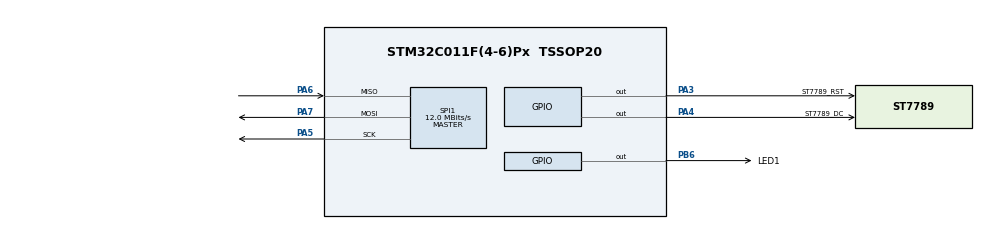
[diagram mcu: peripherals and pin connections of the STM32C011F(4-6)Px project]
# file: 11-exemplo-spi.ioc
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Mcu.Family=STM32C0
Mcu.Name=STM32C011F(4-6)Px
Mcu.Package=TSSOP20
PA13.Mode=Serial_Wire
PA13.Signal=DEBUG_SWDIO
PA14-BOOT0.Mode=Serial_Wire
PA14-BOOT0.Signal=DEBUG_SWCLK
PA3.GPIO_Label=ST7789_RST
PA3.Signal=GPIO_Output
PA4.GPIO_Label=ST7789_DC
PA4.Signal=GPIO_Output
PA5.Mode=Full_Duplex_Master
PA5.Signal=SPI1_SCK
PA6.Mode=Full_Duplex_Master
PA6.Signal=SPI1_MISO
PA7.Mode=Full_Duplex_Master
PA7.Signal=SPI1_MOSI
PB6.GPIO_Label=LED1
PB6.Signal=GPIO_Output
ProjectManager.HeapSize=0x200
ProjectManager.StackSize=0x400
ProjectManager.TargetToolchain=STM32CubeIDE
RCC.ADCFreq_Value=48000000
RCC.AHBFreq_Value=48000000
RCC.CortexFreq_Value=48000000
RCC.EXTERNAL_CLOCK_VALUE=12288000
RCC.HCLKFreq_Value=48000000
RCC.HSE_VALUE=8000000
RCC.HSISYSCLKDivider=RCC_HSI_DIV1
RCC.HSI_VALUE=48000000
RCC.LSE_VALUE=32768
RCC.SYSCLKFreq_VALUE=48000000
SPI1.BaudRatePrescaler=SPI_BAUDRATEPRESCALER_4
SPI1.CLKPolarity=SPI_POLARITY_HIGH
SPI1.CalculateBaudRate=12.0 MBits/s
SPI1.Direction=SPI_DIRECTION_2LINES
SPI1.Mode=SPI_MODE_MASTER
SPI1.VirtualType=VM_MASTER
board=custom

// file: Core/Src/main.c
/* USER CODE BEGIN Header */
/**
  ******************************************************************************
  * @file           : main.c
  * @brief          : Main program body
  ******************************************************************************
  * @attention
  *
  * Copyright (c) 2023 STMicroelectronics.
  * All rights reserved.
  *
  * This software is licensed under terms that can be found in the LICENSE file
  * in the root directory of this software component.
  * If no LICENSE file comes with this software, it is provided AS-IS.
  *
  ******************************************************************************
  */
/* USER CODE END Header */
#include "main.h"
#include "spi.h"
#include "gpio.h"

/* USER CODE BEGIN Includes */

#include "st7789.h"	// Biblioteca utilizada para controlar o display LCD
					// Fonte: https://github.com/Floyd-Fish/ST7789-STM32

/* USER CODE END Includes */

/* USER CODE BEGIN PV */

// Logo Franzininho
const uint16_t logo_franzininho[] =
{
		0xffff, 0xffff, 0xffff, 0xffff, 0xffff, 0xffff, 0xffff, 0xffff, 0xffff, 0xffff, 0xffff, 0xffff, 0xffff, 0xffff, 0xffff, 0xffff, 0xffff, 0xffff, 0xffff, 0xffff, 0xffff, 0xffff, 0xffff, 0xffff, 0xffff, 0xffff, 0xffff, 0xffff, 0xffff, 0xffff, 0xffff, 0xffff, 0xffff, 0xffff, 0xffff, 0xffff, 0xffff, 0xffff, 0xffff, 0xffff, 0xffff, 0xffff, 0xffff, 0xffff, 0xffff, 0xffff, 0xffff, 0xffff, 0xffff, 0xffff, 0xffff, 0xffff, 0xffff, 0xffff, 0xffff, 0xffff, 0xffff, 0xffff, 0xffff, 0xffff, 0xffff, 0xffff, 0xffff, 0xffff, 0xffff, 0xffff, 0xffff, 0xffff, 0xffff, 0xffff, 0xffff, 0xffff, 0xffff, 0xffff, 0xffff, 0xffff, 0xffff, 0xffff, 0xffff, 0xffff, 0xffff, 0x18c6, 0x9ad6, 0xffff, 0xffff, 0xffff, 0xffff, 0xffff, 0xffff, 0xffff, 0xffff, 0xffff, 0xffff, 0xffff, 0xffff, 0xffff,
		0xffff, 0xffff, 0xffff, 0xffff, 0xffff, 0xffff, 0xffff, 0xffff, 0xffff, 0xffff, 0xffff, 0xffff, 0xffff, 0xffff, 0xffff, 0xffff, 0xffff, 0xffff, 0xffff, 0xffff, 0xffff, 0xffff, 0xffff, 0xffff, 0xffff, 0xffff, 0xffff, 0xffff, 0xffff, 0xffff, 0xffff, 0xffff, 0xffff, 0xffff, 0xffff, 0xffff, 0xffff, 0xffff, 0xffff, 0xffff, 0xffff, 0xffff, 0xffff, 0xffff, 0xffff, 0xffff, 0xffff, 0xffff, 0xffff, 0xffff, 0xffff, 0xffff, 0xffff, 0xffff, 0xffff, 0xffff, 0xffff, 0xffff, 0xffff, 0xffff, 0xffff, 0xffff, 0xffff, 0xffff, 0xffff, 0xffff, 0xffff, 0xffff, 0xffff, 0xffff, 0xffff, 0xffff, 0xffff, 0xffff, 0xffff, 0xffff, 0xffff, 0xffff, 0xffff, 0xffff, 0xf7bd, 0x0000, 0xe739, 0xdbde, 0xffff, 0xffff, 0xffff, 0xffff, 0xffff, 0xffff, 0xffff, 0xffff, 0xffff, 0xffff, 0xffff, 0xffff,
		0xffff, 0xffff, 0xffff, 0xffff, 0xffff, 0xffff, 0xffff, 0xffff, 0xffff, 0xffff, 0xffff, 0xffff, 0xffff, 0xffff, 0xffff, 0xffff, 0xffff, 0xffff, 0xffff, 0xffff, 0xffff, 0xffff, 0xffff, 0xffff, 0xffff, 0xffff, 0xffff, 0xffff, 0xffff, 0xffff, 0xffff, 0xffff, 0xffff, 0xffff, 0xffff, 0xffff, 0xffff, 0xffff, 0xffff, 0xffff, 0xffff, 0xffff, 0xffff, 0xffff, 0xffff, 0xffff, 0xffff, 0xffff, 0xffff, 0xffff, 0xffff, 0xffff, 0xffff, 0xffff, 0xffff, 0xffff, 0xffff, 0xffff, 0xffff, 0xffff, 0xffff, 0xffff, 0xffff, 0xffff, 0xffff, 0xffff, 0xffff, 0xffff, 0xffff, 0xffff, 0xffff, 0xffff, 0xffff, 0xffff, 0xffff, 0xffff, 0xffff, 0xffff, 0xffff, 0xd7bd, 0x0000, 0x494a, 0x4529, 0xa631, 0xdbde, 0xffff, 0xffff, 0xffff, 0xffff, 0xffff, 0xffff, 0xffff, 0xffff, 0xffff, 0xffff, 0xffff,
		0xffff, 0xffff, 0xffff, 0xffff, 0xffff, 0xffff, 0xffff, 0xffff, 0xffff, 0xffff, 0xffff, 0xffff, 0xffff, 0xffff, 0xffff, 0xffff, 0xffff, 0xffff, 0xffff, 0xffff, 0xffff, 0xffff, 0xffff, 0xffff, 0xffff, 0xffff, 0xffff, 0xffff, 0xffff, 0xffff, 0xffff, 0xffff, 0xffff, 0xffff, 0xffff, 0xffff, 0xffff, 0xffff, 0xffff, 0xffff, 0xffff, 0xffff, 0xffff, 0xffff, 0xffff, 0xffff, 0xffff, 0xffff, 0xffff, 0xffff, 0xffff, 0xffff, 0xffff, 0xffff, 0xffff, 0xffff, 0xffff, 0xffff, 0xffff, 0xffff, 0xffff, 0xffff, 0xffff, 0xffff, 0xffff, 0xffff, 0xffff, 0xffff, 0xffff, 0xffff, 0xffff, 0xffff, 0xffff, 0xffff, 0xffff, 0xffff, 0xffff, 0xffff, 0xd7bd, 0x0000, 0x2c63, 0x3ce7, 0x9ad6, 0x0000, 0x6529, 0xdbde, 0xffff, 0xffff, 0xffff, 0xffff, 0xffff, 0xffff, 0xffff, 0xffff, 0xffff, 0xffff,
		0xffff, 0xffff, 0xffff, 0xffff, 0xffff, 0xffff, 0xffff, 0xffff, 0xffff, 0xffff, 0xffff, 0xffff, 0xffff, 0xffff, 0xffff, 0xffff, 0xffff, 0xffff, 0xffff, 0xffff, 0xffff, 0xffff, 0xffff, 0xffff, 0xffff, 0xffff, 0xffff, 0xffff, 0xffff, 0xffff, 0xffff, 0xffff, 0xffff, 0xffff, 0xffff, 0xffff, 0xffff, 0xffff, 0xffff, 0xffff, 0xffff, 0xffff, 0xffff, 0xffff, 0xffff, 0xffff, 0xffff, 0xffff, 0xffff, 0xffff, 0xffff, 0xffff, 0xffff, 0xffff, 0xffff, 0xffff, 0xffff, 0xffff, 0xffff, 0xffff, 0xffff, 0xffff, 0xffff, 0xffff, 0xffff, 0xffff, 0xffff, 0xffff, 0xffff, 0xffff, 0xffff, 0xffff, 0xffff, 0xffff, 0xffff, 0xffff, 0xffff, 0xd7bd, 0x0000, 0x0000, 0x34a5, 0xffff, 0xffff, 0x79ce, 0x0000, 0x4529, 0xdbde, 0xffff, 0xffff, 0xffff, 0xffff, 0xffff, 0xffff, 0xffff, 0xffff, 0xffff,
		0xffff, 0xffff, 0xffff, 0xffff, 0xffff, 0xffff, 0xffff, 0xffff, 0xffff, 0xffff, 0xffff, 0xffff, 0xffff, 0xffff, 0xffff, 0xffff, 0xffff, 0xffff, 0xffff, 0xffff, 0xffff, 0xffff, 0xffff, 0xffff, 0xffff, 0xffff, 0xffff, 0xffff, 0xffff, 0xffff, 0xffff, 0xffff, 0xffff, 0xffff, 0xffff, 0xffff, 0xffff, 0xffff, 0xffff, 0xffff, 0xffff, 0xffff, 0xffff, 0xffff, 0xffff, 0xffff, 0xffff, 0xffff, 0xffff, 0xffff, 0xffff, 0xffff, 0xffff, 0xffff, 0xffff, 0xffff, 0xffff, 0xffff, 0xffff, 0xffff, 0xffff, 0xffff, 0xffff, 0xffff, 0xffff, 0xffff, 0xffff, 0xffff, 0xffff, 0xffff, 0xffff, 0xffff, 0xffff, 0xffff, 0xffff, 0xffff, 0xd7bd, 0x0000, 0x8e73, 0xd39c, 0x0000, 0xb6b5, 0xffff, 0xffff, 0x79ce, 0x0000, 0x8631, 0xfbde, 0xffff, 0xffff, 0xffff, 0xffff, 0xffff, 0xffff, 0xffff, 0xffff,
		0xffff, 0xffff, 0xffff, 0xffff, 0xffff, 0xffff, 0xffff, 0xffff, 0xffff, 0xffff, 0xffff, 0xffff, 0xffff, 0xffff, 0xffff, 0xffff, 0xffff, 0xffff, 0xffff, 0xffff, 0xffff, 0xffff, 0xffff, 0xffff, 0xffff, 0xffff, 0xffff, 0xffff, 0xffff, 0xffff, 0xffff, 0xffff, 0xffff, 0xffff, 0xffff, 0xffff, 0xffff, 0xffff, 0xffff, 0xffff, 0xffff, 0xffff, 0xffff, 0xffff, 0xffff, 0xffff, 0xffff, 0xffff, 0xffff, 0xffff, 0xffff, 0xffff, 0xffff, 0xffff, 0xffff, 0xffff, 0xffff, 0xffff, 0xffff, 0xffff, 0xffff, 0xffff, 0xffff, 0xffff, 0xffff, 0xffff, 0xffff, 0xffff, 0xffff, 0xffff, 0xffff, 0xffff, 0xffff, 0xffff, 0xffff, 0xd7bd, 0x0000, 0x2c63, 0x3ce7, 0xffff, 0x34a5, 0x0000, 0xb6b5, 0xffff, 0xffff, 0x79ce, 0x0000, 0x2842, 0x5def, 0xffff, 0xffff, 0xffff, 0xffff, 0xffff, 0xffff, 0xffff,
		0xffff, 0xffff, 0xffff, 0xffff, 0xffff, 0xffff, 0xffff, 0xffff, 0xffff, 0xffff, 0xffff, 0xffff, 0xffff, 0xffff, 0xffff, 0xffff, 0xffff, 0xffff, 0xffff, 0xffff, 0xffff, 0xffff, 0xffff, 0xffff, 0xffff, 0xffff, 0xffff, 0xffff, 0xffff, 0xffff, 0xffff, 0xffff, 0xffff, 0xffff, 0xffff, 0xffff, 0xffff, 0xffff, 0xffff, 0xffff, 0xffff, 0xffff, 0xffff, 0xffff, 0xffff, 0xffff, 0xffff, 0xffff, 0xffff, 0xffff, 0xffff, 0xffff, 0xffff, 0xffff, 0xffff, 0xffff, 0xffff, 0xffff, 0xffff, 0xffff, 0xffff, 0xffff, 0xffff, 0xffff, 0xffff, 0xffff, 0xffff, 0xffff, 0xffff, 0xffff, 0xffff, 0xffff, 0xffff, 0xffff, 0xd7bd, 0x0000, 0x0c63, 0x5def, 0xffff, 0x18c6, 0x59ce, 0x55ad, 0x0000, 0xb6b5, 0xffff, 0xffff, 0x9ad6, 0xe318, 0x2c63, 0x5def, 0xffff, 0xffff, 0xffff, 0xffff, 0xffff, 0xffff,
		0xffff, 0xffff, 0xffff, 0xffff, 0xffff, 0xffff, 0xffff, 0xffff, 0xffff, 0xffff, 0xffff, 0xffff, 0xffff, 0xffff, 0xffff, 0xffff, 0xffff, 0xffff, 0xffff, 0xffff, 0xffff, 0xffff, 0xffff, 0xffff, 0xffff, 0xffff, 0xffff, 0xffff, 0xffff, 0xffff, 0xffff, 0xffff, 0xffff, 0xffff, 0xffff, 0xffff, 0xffff, 0xffff, 0xffff, 0xffff, 0xffff, 0xffff, 0xffff, 0xffff, 0xffff, 0xffff, 0xffff, 0xffff, 0xffff, 0xffff, 0xffff, 0xffff, 0xffff, 0xffff, 0xffff, 0xffff, 0xffff, 0xffff, 0xffff, 0xffff, 0xffff, 0xffff, 0xffff, 0xffff, 0xffff, 0xffff, 0xffff, 0xffff, 0xffff, 0xffff, 0xffff, 0xffff, 0xffff, 0xb6b5, 0x0000, 0x0c63, 0x5def, 0xffff, 0x75ad, 0x0000, 0x18c6, 0xffff, 0x34a5, 0x0000, 0xb6b5, 0xffff, 0xdfff, 0x2c63, 0x0000, 0xbad6, 0xffff, 0xffff, 0xffff, 0xffff, 0xffff, 0xffff,
		0xffff, 0xffff, 0xffff, 0xffff, 0xffff, 0xffff, 0xffff, 0xffff, 0xffff, 0xffff, 0xffff, 0xffff, 0xffff, 0xffff, 0xffff, 0xffff, 0xffff, 0xffff, 0xffff, 0xffff, 0xffff, 0xffff, 0xffff, 0xffff, 0xffff, 0xffff, 0xffff, 0xffff, 0xffff, 0xffff, 0xffff, 0xffff, 0xffff, 0xffff, 0xffff, 0xffff, 0xffff, 0xffff, 0xffff, 0xffff, 0xffff, 0xffff, 0xffff, 0xffff, 0xffff, 0xffff, 0xffff, 0xffff, 0xffff, 0xffff, 0xffff, 0xffff, 0xffff, 0xffff, 0xffff, 0xffff, 0xffff, 0xffff, 0xffff, 0xffff, 0xffff, 0xffff, 0xffff, 0xffff, 0xffff, 0xffff, 0xffff, 0xffff, 0xffff, 0xffff, 0xffff, 0xffff, 0xb6b5, 0x0000, 0x0c63, 0x5def, 0xffff, 0xb6b5, 0x0000, 0x96b5, 0xffff, 0xffff, 0xffff, 0x34a5, 0x0000, 0x75ad, 0x718c, 0x0000, 0xb6b5, 0xffff, 0xffff, 0xffff, 0xffff, 0xffff, 0xffff, 0xffff,
		0xffff, 0xffff, 0xffff, 0xffff, 0xffff, 0xffff, 0xffff, 0xffff, 0xffff, 0xffff, 0xffff, 0xffff, 0xffff, 0xffff, 0xffff, 0xffff, 0xffff, 0xffff, 0xffff, 0xffff, 0xffff, 0xffff, 0xffff, 0xffff, 0xffff, 0xffff, 0xffff, 0xffff, 0xffff, 0xffff, 0xffff, 0xffff, 0xffff, 0xffff, 0xffff, 0xffff, 0xffff, 0xffff, 0xffff, 0xffff, 0xffff, 0xffff, 0xffff, 0xffff, 0xdbde, 0xf7bd, 0xdfff, 0xffff, 0xffff, 0xffff, 0xffff, 0xffff, 0xffff, 0xffff, 0xffff, 0xffff, 0xffff, 0xffff, 0xffff, 0xffff, 0xffff, 0xffff, 0xffff, 0xffff, 0xffff, 0xffff, 0xffff, 0xffff, 0xffff, 0xffff, 0xffff, 0xb6b5, 0x0000, 0x0c63, 0x5def, 0xffff, 0xdfff, 0xb294, 0xf7bd, 0xffff, 0xffff, 0xffff, 0xffff, 0xffff, 0x14a5, 0x0000, 0x0000, 0x75ad, 0xffff, 0xffff, 0xffff, 0xffff, 0xffff, 0xffff, 0xffff, 0xffff,
		0xffff, 0xffff, 0xffff, 0xffff, 0xffff, 0xffff, 0xffff, 0xffff, 0xffff, 0xffff, 0xffff, 0xffff, 0xffff, 0xffff, 0xffff, 0xffff, 0xffff, 0xffff, 0xffff, 0xffff, 0xffff, 0xffff, 0xffff, 0xffff, 0xffff, 0xffff, 0xffff, 0xffff, 0xffff, 0xffff, 0xffff, 0xffff, 0xffff, 0xffff, 0xffff, 0xffff, 0xffff, 0xffff, 0xffff, 0xffff, 0xffff, 0xffff, 0xffff, 0x38c6, 0x6529, 0x0000, 0x55ad, 0xffff, 0xffff, 0xffff, 0xffff, 0xffff, 0xffff, 0xffff, 0xffff, 0xffff, 0xffff, 0xffff, 0xffff, 0xffff, 0xffff, 0xffff, 0xffff, 0xffff, 0xffff, 0xffff, 0xffff, 0xffff, 0xffff, 0xffff, 0xb6b5, 0x0000, 0x0c63, 0x5def, 0xffff, 0x3ce7, 0xdfff, 0xffff, 0xffff, 0xffff, 0xffff, 0xffff, 0xffff, 0xbef7, 0x9294, 0x0000, 0x14a5, 0xffff, 0xffff, 0xffff, 0xffff, 0xffff, 0xffff, 0xffff, 0xffff, 0xffff,
		0xffff, 0xffff, 0xffff, 0xffff, 0xffff, 0xffff, 0xffff, 0xffff, 0xffff, 0xffff, 0xffff, 0xffff, 0xffff, 0xffff, 0xffff, 0xffff, 0xffff, 0xffff, 0xffff, 0xffff, 0xffff, 0xffff, 0xffff, 0xffff, 0xffff, 0xffff, 0xffff, 0xffff, 0xffff, 0xffff, 0xffff, 0xffff, 0xffff, 0xffff, 0xffff, 0xffff, 0xffff, 0xffff, 0xffff, 0xffff, 0xffff, 0xdfff, 0x75ad, 0x0000, 0x4108, 0xa631, 0x0000, 0xd7bd, 0xffff, 0xffff, 0xffff, 0xffff, 0xffff, 0xffff, 0xffff, 0xffff, 0xffff, 0xffff, 0xffff, 0xffff, 0xffff, 0xffff, 0xffff, 0xffff, 0xffff, 0xffff, 0xffff, 0xffff, 0xffff, 0xd7bd, 0x0000, 0x0c63, 0x5def, 0xffff, 0x18c6, 0x2c63, 0x7def, 0xffff, 0xffff, 0xffff, 0xffff, 0xffff, 0xbef7, 0x718c, 0x0000, 0x14a5, 0xdfff, 0xffff, 0xffff, 0xffff, 0xffff, 0xffff, 0xffff, 0xffff, 0xffff, 0xffff,
		0xffff, 0xffff, 0xffff, 0xffff, 0xffff, 0xffff, 0xffff, 0xffff, 0xffff, 0xffff, 0xffff, 0xffff, 0xffff, 0xffff, 0xffff, 0xffff, 0xffff, 0xffff, 0xffff, 0xffff, 0xffff, 0xffff, 0xffff, 0xffff, 0xffff, 0xffff, 0xffff, 0xffff, 0xffff, 0xffff, 0xffff, 0xffff, 0xffff, 0xffff, 0xffff, 0xffff, 0xffff, 0xffff, 0xffff, 0xffff, 0x7def, 0x1084, 0x0000, 0x8a52, 0xdbde, 0xdbde, 0x8631, 0x0000, 0x79ce, 0xffff, 0xffff, 0xffff, 0xffff, 0xffff, 0xffff, 0xffff, 0xffff, 0xffff, 0xffff, 0xffff, 0xffff, 0xffff, 0xffff, 0xffff, 0xffff, 0xffff, 0xffff, 0xffff, 0xb6b5, 0x0000, 0x0c63, 0x5def, 0xffff, 0xb6b5, 0x0000, 0x9ad6, 0xffff, 0xffff, 0xffff, 0xffff, 0xffff, 0xbef7, 0x518c, 0x0000, 0x14a5, 0xdfff, 0xffff, 0xffff, 0xffff, 0xffff, 0xffff, 0xffff, 0xffff, 0xffff, 0xffff, 0xffff,
		0xffff, 0xffff, 0xffff, 0xffff, 0xffff, 0xffff, 0xffff, 0xffff, 0xffff, 0xffff, 0xffff, 0xffff, 0xffff, 0xffff, 0xffff, 0xffff, 0xffff, 0xffff, 0xffff, 0xffff, 0xffff, 0xffff, 0xffff, 0xffff, 0xffff, 0xffff, 0xffff, 0xffff, 0xffff, 0xffff, 0xffff, 0xffff, 0xffff, 0xffff, 0xffff, 0xffff, 0xffff, 0xffff, 0xffff, 0xbad6, 0xaa52, 0x0000, 0x1084, 0x5def, 0xffff, 0xffff, 0x79ce, 0x0000, 0x4529, 0xdbde, 0xffff, 0xffff, 0xffff, 0xffff, 0xffff, 0xffff, 0xffff, 0xffff, 0xffff, 0xffff, 0xffff, 0xffff, 0xffff, 0xffff, 0xffff, 0xffff, 0xffff, 0xb6b5, 0x0000, 0x0c63, 0x5def, 0xffff, 0x75ad, 0x0000, 0xd7bd, 0xffff, 0xffff, 0xffff, 0xffff, 0xffff, 0xdfff, 0x518c, 0x0000, 0xf39c, 0xdfff, 0xffff, 0xffff, 0xffff, 0xffff, 0xffff, 0xffff, 0xffff, 0xffff, 0xffff, 0xffff, 0xffff,
		0xffff, 0xffff, 0xffff, 0xffff, 0xffff, 0xffff, 0xffff, 0xffff, 0xffff, 0xffff, 0xffff, 0xffff, 0xffff, 0xffff, 0xffff, 0xffff, 0xffff, 0xffff, 0xffff, 0xffff, 0xffff, 0xffff, 0xffff, 0xffff, 0xffff, 0xffff, 0xffff, 0xffff, 0xffff, 0xffff, 0xffff, 0xffff, 0xffff, 0xffff, 0xffff, 0xffff, 0xffff, 0xffff, 0xf7bd, 0x0000, 0x0000, 0x55ad, 0xdfff, 0xffff, 0xffff, 0xffff, 0xffff, 0xf7bd, 0x0000, 0x8a52, 0x5def, 0xffff, 0xffff, 0xffff, 0xffff, 0xffff, 0xffff, 0xffff, 0xffff, 0xffff, 0xffff, 0xffff, 0xffff, 0xffff, 0xffff, 0xffff, 0xd7bd, 0x0000, 0x2c63, 0x5def, 0xffff, 0x55ad, 0x0000, 0x96b5, 0xffff, 0xffff, 0xffff, 0xffff, 0xffff, 0xdfff, 0x3084, 0x0000, 0xf39c, 0xdfff, 0xffff, 0xffff, 0xffff, 0xffff, 0xffff, 0xffff, 0xffff, 0xffff, 0xffff, 0xffff, 0xffff, 0xffff,
		0xffff, 0xffff, 0xffff, 0xffff, 0xffff, 0xffff, 0xffff, 0xffff, 0xffff, 0xffff, 0xffff, 0xffff, 0xffff, 0xffff, 0xffff, 0xffff, 0xffff, 0xffff, 0xffff, 0xffff, 0xffff, 0xffff, 0xffff, 0xffff, 0xffff, 0xffff, 0xffff, 0xffff, 0xffff, 0xffff, 0xffff, 0xffff, 0xffff, 0xffff, 0xffff, 0xffff, 0xbef7, 0xd39c, 0x0000, 0x6529, 0x59ce, 0xffff, 0xffff, 0xffff, 0xffff, 0xffff, 0xffff, 0xffff, 0x55ad, 0x0000, 0x8e73, 0xbef7, 0xffff, 0xffff, 0xffff, 0xffff, 0xffff, 0xffff, 0xffff, 0xffff, 0xffff, 0xffff, 0xffff, 0xffff, 0xffff, 0xd7bd, 0x0000, 0x4d6b, 0x3ce7, 0xffff, 0x34a5, 0x0000, 0x96b5, 0xffff, 0xffff, 0xffff, 0xffff, 0xffff, 0xdfff, 0x3084, 0x0000, 0xf39c, 0xdfff, 0xffff, 0xffff, 0xffff, 0xffff, 0xffff, 0xffff, 0xffff, 0xffff, 0xffff, 0xffff, 0xffff, 0xffff, 0xffff,
		0xffff, 0xffff, 0xffff, 0xffff, 0xffff, 0xffff, 0xffff, 0xffff, 0xffff, 0xffff, 0xffff, 0xffff, 0xffff, 0xffff, 0xffff, 0xffff, 0xffff, 0xffff, 0xffff, 0xffff, 0xffff, 0xffff, 0xffff, 0xffff, 0xffff, 0xffff, 0xffff, 0xffff, 0xffff, 0xffff, 0xffff, 0xffff, 0xffff, 0xffff, 0xffff, 0x3ce7, 0xae73, 0x0000, 0x2c63, 0xdbde, 0xffff, 0xffff, 0xffff, 0xffff, 0xffff, 0xffff, 0xffff, 0xffff, 0xdfff, 0x9294, 0x0000, 0x3084, 0xdfff, 0xffff, 0xffff, 0xffff, 0xffff, 0xffff, 0xffff, 0xffff, 0xffff, 0xffff, 0xffff, 0xffff, 0x18c6, 0x0000, 0x2c63, 0x3ce7, 0xffff, 0x34a5, 0x0000, 0x75ad, 0xffff, 0xffff, 0xffff, 0xffff, 0xffff, 0xdfff, 0x3084, 0x0000, 0xf39c, 0xdfff, 0xffff, 0xffff, 0xffff, 0xffff, 0xffff, 0xffff, 0xffff, 0xffff, 0xffff, 0xffff, 0xffff, 0xffff, 0xffff, 0xffff,
		0xffff, 0xffff, 0xffff, 0xffff, 0xffff, 0xffff, 0xffff, 0xffff, 0xffff, 0xffff, 0xffff, 0xffff, 0xffff, 0xffff, 0xffff, 0xffff, 0xffff, 0xffff, 0xffff, 0xffff, 0xffff, 0xffff, 0xffff, 0xffff, 0xffff, 0xffff, 0xffff, 0xffff, 0xffff, 0xffff, 0xffff, 0xffff, 0xffff, 0xffff, 0x79ce, 0x2842, 0x0000, 0x718c, 0x7def, 0xffff, 0xffff, 0xffff, 0xffff, 0xffff, 0xffff, 0xffff, 0xffff, 0xffff, 0xffff, 0x9ef7, 0xcf7b, 0x0000, 0xd39c, 0xffff, 0xffff, 0xffff, 0xffff, 0xffff, 0xffff, 0xffff, 0xffff, 0xffff, 0xffff, 0x38c6, 0x0000, 0x2c63, 0x5def, 0xffff, 0x14a5, 0x0000, 0x75ad, 0xffff, 0xffff, 0xffff, 0xffff, 0xffff, 0xdfff, 0x3084, 0x0000, 0x14a5, 0xdfff, 0xffff, 0xffff, 0xffff, 0xffff, 0xffff, 0xffff, 0xffff, 0xffff, 0xffff, 0xffff, 0xffff, 0xffff, 0xffff, 0xffff, 0xffff,
		0xffff, 0xffff, 0xffff, 0xffff, 0xffff, 0xffff, 0xffff, 0xffff, 0xffff, 0xffff, 0xffff, 0xffff, 0xffff, 0xffff, 0xffff, 0xffff, 0xffff, 0xffff, 0xffff, 0xffff, 0xffff, 0xffff, 0xffff, 0xffff, 0xffff, 0xffff, 0xffff, 0xffff, 0xffff, 0xffff, 0xffff, 0xffff, 0xffff, 0x75ad, 0x0000, 0x0000, 0x96b5, 0xffff, 0xffff, 0xffff, 0xffff, 0xffff, 0xffff, 0xffff, 0xffff, 0xffff, 0xffff, 0xffff, 0xffff, 0xffff, 0x7def, 0x6d6b, 0x0000, 0x96b5, 0xffff, 0xffff, 0xffff, 0xffff, 0xffff, 0xffff, 0xffff, 0xffff, 0x59ce, 0x0000, 0x0c63, 0x5def, 0xffff, 0x14a5, 0x0000, 0x75ad, 0xffff, 0xffff, 0xffff, 0xffff, 0xffff, 0xbef7, 0x518c, 0x0000, 0x34a5, 0xdfff, 0xffff, 0xffff, 0xffff, 0xffff, 0xffff, 0xffff, 0xffff, 0xffff, 0xffff, 0xffff, 0xffff, 0xffff, 0xffff, 0xffff, 0xffff, 0xffff,
		0xffff, 0xffff, 0xffff, 0xffff, 0xffff, 0xffff, 0xffff, 0xffff, 0xffff, 0xffff, 0xffff, 0xffff, 0xffff, 0xffff, 0xffff, 0xffff, 0xffff, 0xffff, 0xffff, 0xffff, 0xffff, 0xffff, 0xffff, 0xffff, 0xffff, 0xffff, 0xffff, 0xffff, 0xffff, 0xffff, 0xffff, 0x7def, 0xb294, 0x0000, 0x0842, 0x79ce, 0xffff, 0xffff, 0xffff, 0xffff, 0xffff, 0xffff, 0xffff, 0xffff, 0xffff, 0xffff, 0xffff, 0xffff, 0xffff, 0xffff, 0xffff, 0x3ce7, 0x694a, 0x0000, 0x18c6, 0xffff, 0xffff, 0xffff, 0xffff, 0xffff, 0xffff, 0xbad6, 0x0000, 0x4d6b, 0x5def, 0xffff, 0x34a5, 0x0000, 0x96b5, 0xffff, 0xffff, 0xffff, 0xffff, 0xffff, 0xbef7, 0x518c, 0x0000, 0x55ad, 0xffff, 0xffff, 0xffff, 0xffff, 0xffff, 0xffff, 0xffff, 0xffff, 0xffff, 0xffff, 0xffff, 0xffff, 0xffff, 0xffff, 0xffff, 0xffff, 0xffff, 0xffff,
		0xffff, 0xffff, 0xffff, 0xffff, 0xffff, 0xffff, 0xffff, 0xffff, 0xffff, 0xffff, 0xffff, 0xffff, 0xffff, 0xffff, 0xffff, 0xffff, 0xffff, 0xffff, 0xffff, 0xffff, 0xffff, 0xffff, 0xffff, 0xffff, 0xffff, 0xffff, 0xffff, 0xffff, 0xffff, 0xffff, 0xfbde, 0x2c63, 0x0000, 0x8e73, 0x3ce7, 0xffff, 0xffff, 0xffff, 0xffff, 0xffff, 0xffff, 0xffff, 0xffff, 0xffff, 0xffff, 0xffff, 0xffff, 0xffff, 0xffff, 0xffff, 0xffff, 0xffff, 0xdbde, 0x0000, 0x0000, 0xbad6, 0xffff, 0xffff, 0xffff, 0xffff, 0xffff, 0xb6b5, 0x0000, 0x9294, 0xffff, 0xb6b5, 0x0000, 0xb6b5, 0xffff, 0xffff, 0xffff, 0xffff, 0xffff, 0x9ef7, 0x518c, 0x0000, 0x75ad, 0xffff, 0xffff, 0xffff, 0xffff, 0xffff, 0xffff, 0xffff, 0xffff, 0xffff, 0xffff, 0xffff, 0xffff, 0xffff, 0xffff, 0xffff, 0xffff, 0xffff, 0xffff, 0xffff,
		0xffff, 0xffff, 0xffff, 0xffff, 0xffff, 0xffff, 0xffff, 0xffff, 0xffff, 0xffff, 0xffff, 0xffff, 0xffff, 0xffff, 0xffff, 0xffff, 0xffff, 0xffff, 0xffff, 0xffff, 0xffff, 0xffff, 0xffff, 0xffff, 0xffff, 0xffff, 0xffff, 0xffff, 0xffff, 0x38c6, 0x8631, 0x0000, 0xd39c, 0xbef7, 0xffff, 0xffff, 0xffff, 0xffff, 0xffff, 0xffff, 0xffff, 0xffff, 0xffff, 0xffff, 0xffff, 0xffff, 0xffff, 0xffff, 0xffff, 0xffff, 0xffff, 0xffff, 0xffff, 0x38c6, 0x0000, 0x9294, 0xffff, 0xffff, 0xffff, 0xffff, 0xffff, 0x75ad, 0x0000, 0x0000, 0xf39c, 0x518c, 0xf7bd, 0xffff, 0xffff, 0xffff, 0xffff, 0xffff, 0x9ef7, 0x718c, 0x0000, 0x75ad, 0xffff, 0xffff, 0xffff, 0xffff, 0xffff, 0xffff, 0xffff, 0xffff, 0xffff, 0xffff, 0xffff, 0xffff, 0xffff, 0xffff, 0xffff, 0xffff, 0xffff, 0xffff, 0xffff, 0xffff,
		0xffff, 0xffff, 0xffff, 0xffff, 0xffff, 0xffff, 0xffff, 0xffff, 0xffff, 0xffff, 0xffff, 0xffff, 0xffff, 0xffff, 0xffff, 0xffff, 0xffff, 0xffff, 0xffff, 0xffff, 0xffff, 0xffff, 0xffff, 0xffff, 0xffff, 0xffff, 0xffff, 0xbef7, 0x55ad, 0x0000, 0x0000, 0xd7bd, 0xffff, 0xffff, 0xffff, 0xffff, 0xffff, 0xffff, 0xffff, 0xffff, 0xffff, 0xffff, 0xffff, 0xffff, 0xffff, 0xffff, 0xffff, 0xffff, 0xffff, 0xffff, 0xffff, 0xffff, 0xffff, 0xffff, 0xbad6, 0x5def, 0xffff, 0xffff, 0xffff, 0xffff, 0x9ad6, 0x0000, 0x6d6b, 0xcf7b, 0x0000, 0x34a5, 0xdfff, 0xffff, 0xffff, 0xffff, 0xffff, 0xbef7, 0x518c, 0x0000, 0x96b5, 0xffff, 0xffff, 0xffff, 0xffff, 0xffff, 0xffff, 0xffff, 0xffff, 0xffff, 0xffff, 0xffff, 0xffff, 0xffff, 0xffff, 0xffff, 0xffff, 0xffff, 0xffff, 0xffff, 0xffff, 0xffff,
		0xffff, 0xffff, 0xffff, 0xffff, 0xffff, 0xffff, 0xffff, 0xffff, 0xffff, 0xffff, 0xffff, 0xffff, 0xffff, 0xffff, 0xffff, 0xffff, 0xffff, 0xffff, 0xffff, 0xffff, 0xffff, 0xffff, 0xffff, 0xffff, 0xffff, 0xffff, 0x7def, 0x518c, 0x0000, 0x494a, 0xfbde, 0xffff, 0xffff, 0xffff, 0xffff, 0xffff, 0xffff, 0xffff, 0xffff, 0xffff, 0xffff, 0xffff, 0xffff, 0xffff, 0xffff, 0xffff, 0xffff, 0xffff, 0xffff, 0xffff, 0xffff, 0xffff, 0xffff, 0xffff, 0xffff, 0xffff, 0xffff, 0xffff, 0xffff, 0xdbde, 0x0000, 0x6d6b, 0xbef7, 0x9ef7, 0x1084, 0x0000, 0x55ad, 0xdfff, 0xffff, 0xffff, 0xbef7, 0x3084, 0x0000, 0xd7bd, 0xffff, 0xffff, 0xffff, 0xffff, 0xffff, 0xffff, 0xffff, 0xffff, 0xffff, 0xffff, 0xffff, 0xffff, 0xffff, 0xffff, 0xffff, 0xffff, 0xffff, 0xffff, 0xffff, 0xffff, 0xffff, 0xffff,
		0xffff, 0xffff, 0xffff, 0xffff, 0xffff, 0xffff, 0xffff, 0xffff, 0xffff, 0xffff, 0xffff, 0xffff, 0xffff, 0xffff, 0xffff, 0xffff, 0xffff, 0xffff, 0xffff, 0xffff, 0xffff, 0xffff, 0xffff, 0xffff, 0xffff, 0xdbde, 0x694a, 0x0000, 0x1084, 0x5def, 0xffff, 0xffff, 0xffff, 0xffff, 0xffff, 0xffff, 0xffff, 0xffff, 0xffff, 0xffff, 0xffff, 0xffff, 0xffff, 0xffff, 0xffff, 0xffff, 0xffff, 0xffff, 0xffff, 0xffff, 0xffff, 0xffff, 0xffff, 0xffff, 0xffff, 0xffff, 0xffff, 0xffff, 0xfbde, 0x8210, 0x8e73, 0x9ef7, 0xffff, 0xffff, 0x9ef7, 0xef7b, 0x0000, 0x14a5, 0xdfff, 0xbef7, 0xef7b, 0x0000, 0x18c6, 0xffff, 0xffff, 0xffff, 0xffff, 0xffff, 0xffff, 0xffff, 0xffff, 0xffff, 0xffff, 0xffff, 0xffff, 0xffff, 0xffff, 0xffff, 0xffff, 0xffff, 0xffff, 0xffff, 0xffff, 0xffff, 0xffff, 0xffff,
		0xffff, 0xffff, 0xffff, 0xffff, 0xffff, 0xffff, 0xffff, 0xffff, 0xffff, 0xffff, 0xffff, 0xffff, 0xffff, 0xffff, 0xffff, 0xffff, 0xffff, 0xffff, 0xffff, 0xffff, 0xffff, 0xffff, 0xffff, 0xffff, 0xf7bd, 0x0000, 0x0000, 0xc522, 0x1ad7, 0xffff, 0xffff, 0xffff, 0xffff, 0xffff, 0xffff, 0xffff, 0xffff, 0xffff, 0xffff, 0xffff, 0xffff, 0xffff, 0xffff, 0xffff, 0xffff, 0xffff, 0xffff, 0xffff, 0xffff, 0xffff, 0xffff, 0xffff, 0xffff, 0xffff, 0xffff, 0xffff, 0xffff, 0x3ce7, 0xc739, 0x6d6b, 0x9ef7, 0xffff, 0xffff, 0xffff, 0xffff, 0x9ef7, 0xcf7b, 0x0000, 0x3084, 0x2c63, 0x0000, 0x79ce, 0xffff, 0xffff, 0xffff, 0xffff, 0xffff, 0xffff, 0xffff, 0xffff, 0xffff, 0xffff, 0xffff, 0xffff, 0xffff, 0xffff, 0xffff, 0xffff, 0xffff, 0xffff, 0xffff, 0xffff, 0xffff, 0xffff, 0xffff, 0xffff,
		0xffff, 0xffff, 0xffff, 0xffff, 0xffff, 0xffff, 0xffff, 0xffff, 0xffff, 0xffff, 0xffff, 0xffff, 0xffff, 0xffff, 0xffff, 0xffff, 0xffff, 0xffff, 0xffff, 0xffff, 0xffff, 0xffff, 0xdfff, 0xd39c, 0x0000, 0xe841, 0x128d, 0xe60b, 0x0e6d, 0xbef7, 0xffff, 0xffff, 0xffff, 0xffff, 0xffff, 0xffff, 0xffff, 0xffff, 0xffff, 0xffff, 0xffff, 0xffff, 0xffff, 0xffff, 0xffff, 0xffff, 0xffff, 0xffff, 0xffff, 0xffff, 0xffff, 0xffff, 0xffff, 0xffff, 0xffff, 0xffff, 0xdfff, 0x8e73, 0x694a, 0x5def, 0xffff, 0xffff, 0xffff, 0xffff, 0xffff, 0xdfff, 0x518c, 0x0000, 0x0000, 0xaa52, 0xdbde, 0xffff, 0xffff, 0xffff, 0xffff, 0xffff, 0xffff, 0xffff, 0xffff, 0xffff, 0xffff, 0xffff, 0xffff, 0xffff, 0xffff, 0xffff, 0xffff, 0xffff, 0xffff, 0xffff, 0xffff, 0xffff, 0xffff, 0xffff, 0xffff, 0xffff,
		0xffff, 0xffff, 0xffff, 0xffff, 0xffff, 0xffff, 0xffff, 0xffff, 0xffff, 0xffff, 0xffff, 0xffff, 0xffff, 0xffff, 0xffff, 0xffff, 0xffff, 0xffff, 0xffff, 0xffff, 0xffff, 0x3ce7, 0xae73, 0x0000, 0x4d6b, 0xfbe6, 0xffff, 0x15a6, 0xa003, 0x7185, 0xdef7, 0xffff, 0xffff, 0xffff, 0xffff, 0xffff, 0xffff, 0xffff, 0xffff, 0xffff, 0xffff, 0xffff, 0xffff, 0xffff, 0xffff, 0xffff, 0xffff, 0xffff, 0xffff, 0xffff, 0xffff, 0xffff, 0xffff, 0xffff, 0xffff, 0xffff, 0xb6b5, 0x0000, 0x38c6, 0xffff, 0xffff, 0xffff, 0xffff, 0xffff, 0xdfff, 0xb294, 0x0000, 0x9294, 0xf7bd, 0x3ce7, 0xffff, 0xffff, 0xffff, 0xffff, 0xffff, 0xffff, 0xffff, 0xffff, 0xffff, 0xffff, 0xffff, 0xffff, 0xffff, 0xffff, 0xffff, 0xffff, 0xffff, 0xffff, 0xffff, 0xffff, 0xffff, 0xffff, 0xffff, 0xffff, 0xffff, 0xffff,
		0xffff, 0xffff, 0xffff, 0xffff, 0xffff, 0xffff, 0xffff, 0xffff, 0xffff, 0xffff, 0xffff, 0xffff, 0xffff, 0xffff, 0xffff, 0xffff, 0xffff, 0xffff, 0xffff, 0xffff, 0x9ad6, 0x2842, 0x0000, 0x518c, 0x7def, 0xffff, 0xffff, 0xdff7, 0xb395, 0x8003, 0xf49d, 0xffff, 0xffff, 0xffff, 0xffff, 0xffff, 0xffff, 0xffff, 0xffff, 0xffff, 0xffff, 0xffff, 0xffff, 0xffff, 0xffff, 0xffff, 0xffff, 0xffff, 0xffff, 0xffff, 0xffff, 0xffff, 0xffff, 0xffff, 0xffff, 0xdfff, 0x694a, 0xcf7b, 0xdfff, 0xffff, 0xffff, 0xffff, 0xffff, 0xdfff, 0xd39c, 0x0000, 0xb6b5, 0xffff, 0xffff, 0xffff, 0xffff, 0xffff, 0xffff, 0xffff, 0xffff, 0xffff, 0xffff, 0xffff, 0xffff, 0xffff, 0xffff, 0xffff, 0xffff, 0xffff, 0xffff, 0xffff, 0xffff, 0xffff, 0xffff, 0xffff, 0xffff, 0xffff, 0xffff, 0xffff, 0xffff, 0xffff,
		0xffff, 0xffff, 0xffff, 0xffff, 0xffff, 0xffff, 0xffff, 0xffff, 0xffff, 0xffff, 0xffff, 0xffff, 0xffff, 0xffff, 0xffff, 0xffff, 0xffff, 0xffff, 0xffff, 0x96b5, 0x0000, 0x0000, 0x96b5, 0xdfff, 0xffff, 0xffff, 0xffff, 0xffff, 0xdef7, 0x718d, 0xa003, 0x56b6, 0xffff, 0xffff, 0xffff, 0xffff, 0xffff, 0xffff, 0xffff, 0xffff, 0xffff, 0xffff, 0xffff, 0xffff, 0xffff, 0xffff, 0xffff, 0xffff, 0xffff, 0xffff, 0xffff, 0xffff, 0xffff, 0xffff, 0xffff, 0x18c6, 0x0000, 0x18c6, 0xffff, 0xffff, 0xffff, 0xffff, 0xbef7, 0x718c, 0x0000, 0x18c6, 0xffff, 0xffff, 0xffff, 0xffff, 0xffff, 0xffff, 0xffff, 0xffff, 0xffff, 0xffff, 0xffff, 0xffff, 0xffff, 0xffff, 0xffff, 0xffff, 0xffff, 0xffff, 0xffff, 0xffff, 0xffff, 0xffff, 0xffff, 0xffff, 0xffff, 0xffff, 0xffff, 0xffff, 0xffff, 0xffff,
		0xffff, 0xffff, 0xffff, 0xffff, 0xffff, 0xffff, 0xffff, 0xffff, 0xffff, 0xffff, 0xffff, 0xffff, 0xffff, 0xffff, 0xffff, 0xffff, 0xffff, 0x9ef7, 0x718c, 0x0000, 0x694a, 0x79ce, 0xffff, 0xffff, 0xffff, 0xffff, 0xffff, 0xffff, 0xffff, 0xbef7, 0x2f75, 0xc103, 0xb8c6, 0xffff, 0xffff, 0xffff, 0xffff, 0xffff, 0xffff, 0xffff, 0xffff, 0xffff, 0xffff, 0xffff, 0xffff, 0xffff, 0xffff, 0xffff, 0xffff, 0xffff, 0xffff, 0xffff, 0xffff, 0xffff, 0xbef7, 0x4d6b, 0x2842, 0x9ef7, 0xffff, 0xffff, 0xffff, 0x1ce7, 0x6d6b, 0x0000, 0x59ce, 0xffff, 0xffff, 0xffff, 0xffff, 0xffff, 0xffff, 0xffff, 0xffff, 0xffff, 0xffff, 0xffff, 0xffff, 0xffff, 0xffff, 0xffff, 0xffff, 0xffff, 0xffff, 0xffff, 0xffff, 0xffff, 0xffff, 0xffff, 0xffff, 0xffff, 0xffff, 0xffff, 0xffff, 0xffff, 0xffff, 0xffff,
		0xffff, 0xffff, 0xffff, 0xffff, 0xffff, 0xffff, 0xffff, 0xffff, 0xffff, 0xffff, 0xffff, 0xffff, 0xffff, 0xffff, 0xffff, 0xffff, 0xfbde, 0xae73, 0x0000, 0x8e73, 0x3ce7, 0xffff, 0xffff, 0xffff, 0xffff, 0xffff, 0xffff, 0xffff, 0xffff, 0xffff, 0x9def, 0xac54, 0xe503, 0xface, 0xffff, 0xffff, 0xffff, 0xffff, 0xffff, 0xffff, 0xffff, 0xffff, 0xffff, 0xffff, 0xffff, 0xffff, 0xffff, 0xffff, 0xffff, 0xffff, 0xffff, 0xffff, 0xffff, 0xffff, 0x1ce7, 0x0000, 0xb6b5, 0xffff, 0xffff, 0xdbde, 0x34a5, 0x2421, 0x494a, 0xbad6, 0xffff, 0xffff, 0xffff, 0xffff, 0xffff, 0xffff, 0xffff, 0xffff, 0xffff, 0xffff, 0xffff, 0xffff, 0xffff, 0xffff, 0xffff, 0xffff, 0xffff, 0xffff, 0xffff, 0xffff, 0xffff, 0xffff, 0xffff, 0xffff, 0xffff, 0xffff, 0xffff, 0xffff, 0xffff, 0xffff, 0xffff, 0xffff,
		0xffff, 0xffff, 0xffff, 0xffff, 0xffff, 0xffff, 0xffff, 0xffff, 0xffff, 0xffff, 0xffff, 0xffff, 0xffff, 0xffff, 0xffff, 0x38c6, 0x4529, 0x0000, 0xb294, 0xbef7, 0xffff, 0xffff, 0xffff, 0xffff, 0xffff, 0xffff, 0xffff, 0xffff, 0xffff, 0xffff, 0xffff, 0x5bdf, 0x4934, 0x2834, 0x1bd7, 0xffff, 0xffff, 0xffff, 0xffff, 0xffff, 0xffff, 0xffff, 0xffff, 0xffff, 0xffff, 0xffff, 0xffff, 0xffff, 0xffff, 0xffff, 0xffff, 0xffff, 0xffff, 0xffff, 0xd39c, 0x0000, 0xb6b5, 0x59ce, 0x3084, 0x0000, 0x0000, 0xb294, 0x7def, 0xffff, 0xffff, 0xffff, 0xffff, 0xffff, 0xffff, 0xffff, 0xffff, 0xffff, 0xffff, 0xffff, 0xffff, 0xffff, 0xffff, 0xffff, 0xffff, 0xffff, 0xffff, 0xffff, 0xffff, 0xffff, 0xffff, 0xffff, 0xffff, 0xffff, 0xffff, 0xffff, 0xffff, 0xffff, 0xffff, 0xffff, 0xffff, 0xffff,
		0xffff, 0xffff, 0xffff, 0xffff, 0xffff, 0xffff, 0xffff, 0xffff, 0xffff, 0xffff, 0xffff, 0xffff, 0xffff, 0xbef7, 0x55ad, 0x0000, 0x2529, 0xd7bd, 0xffff, 0xffff, 0xffff, 0xffff, 0xffff, 0xffff, 0xffff, 0xffff, 0xffff, 0xffff, 0xffff, 0xffff, 0xffff, 0xffff, 0xd9ce, 0xe60b, 0x493c, 0xd9ce, 0x9def, 0x7ce7, 0x9def, 0xffff, 0xffff, 0xffff, 0xffff, 0xffff, 0xffff, 0xffff, 0xffff, 0xffff, 0xffff, 0xffff, 0xffff, 0xffff, 0xffff, 0x7def, 0x8a52, 0x0000, 0x2000, 0x0000, 0x6529, 0xd39c, 0x1ce7, 0xffff, 0xffff, 0xffff, 0xffff, 0xffff, 0xffff, 0xffff, 0xffff, 0xffff, 0xffff, 0xffff, 0xffff, 0xffff, 0xffff, 0xffff, 0xffff, 0xffff, 0xffff, 0xffff, 0xffff, 0xffff, 0xffff, 0xffff, 0xffff, 0xffff, 0xffff, 0xffff, 0xffff, 0xffff, 0xffff, 0xffff, 0xffff, 0xffff, 0xffff, 0xffff,
		0xffff, 0xffff, 0xffff, 0xffff, 0xffff, 0xffff, 0xffff, 0xffff, 0xffff, 0xffff, 0xffff, 0xffff, 0x7def, 0x1084, 0x0000, 0x0000, 0xb5a5, 0xffff, 0xffff, 0xffff, 0xffff, 0xffff, 0xffff, 0xffff, 0xffff, 0xffff, 0xffff, 0xffff, 0xffff, 0xffff, 0xffff, 0xffff, 0xffff, 0x15a6, 0xc403, 0x0724, 0x6b4c, 0x2934, 0x4a44, 0x928d, 0x5cdf, 0xffff, 0xffff, 0xffff, 0xffff, 0xffff, 0xffff, 0xffff, 0xffff, 0xffff, 0xffff, 0xffff, 0xffff, 0x1ce7, 0x0000, 0x0000, 0x4d6b, 0xf7bd, 0x9ef7, 0xffff, 0xffff, 0xffff, 0xffff, 0xffff, 0x1ce7, 0x8e73, 0x1ce7, 0xffff, 0xffff, 0xffff, 0xffff, 0xffff, 0xffff, 0xffff, 0xffff, 0xffff, 0xffff, 0xffff, 0xffff, 0xffff, 0xffff, 0xffff, 0xffff, 0xffff, 0xffff, 0xffff, 0xffff, 0xffff, 0xffff, 0xffff, 0xffff, 0xffff, 0xffff, 0xffff, 0xffff, 0xffff,
		0xffff, 0xffff, 0xffff, 0xffff, 0xffff, 0xffff, 0xffff, 0xffff, 0xffff, 0xffff, 0xffff, 0xfbde, 0xcb5a, 0x0000, 0x8d6b, 0x2a44, 0x6a44, 0x3bdf, 0xffff, 0xffff, 0xffff, 0xffff, 0xffff, 0xffff, 0xffff, 0xffff, 0xffff, 0xffff, 0xffff, 0xffff, 0xffff, 0xffff, 0xffff, 0xdef7, 0xac5c, 0xc403, 0x4a44, 0x3085, 0xee6c, 0xe403, 0x2724, 0xd9ce, 0xffff, 0xffff, 0xffff, 0xffff, 0xffff, 0xffff, 0xffff, 0xffff, 0xffff, 0xffff, 0xffff, 0x7def, 0x96b5, 0x1ce7, 0xbef7, 0xffff, 0xffff, 0xffff, 0xffff, 0xffff, 0xffff, 0xffff, 0xdbde, 0x0000, 0x4d6b, 0x9ef7, 0xffff, 0xffff, 0xffff, 0xffff, 0xffff, 0xffff, 0xffff, 0xffff, 0xffff, 0xffff, 0xffff, 0xffff, 0xffff, 0xffff, 0xffff, 0xffff, 0xffff, 0xffff, 0xffff, 0xffff, 0xffff, 0xffff, 0xffff, 0xffff, 0xffff, 0xffff, 0xffff, 0xffff,
		0xffff, 0xffff, 0xffff, 0xffff, 0xffff, 0xffff, 0xffff, 0xffff, 0xffff, 0xffff, 0xf7bd, 0x0000, 0x0000, 0x34a5, 0xdfff, 0xd9c6, 0xc403, 0xac5c, 0x9def, 0xffff, 0xffff, 0xffff, 0xffff, 0xffff, 0xffff, 0xffff, 0xffff, 0xffff, 0xffff, 0xffff, 0xffff, 0xffff, 0xffff, 0xbdef, 0x6a4c, 0xce64, 0x5ce7, 0xffff, 0xdfff, 0xb8c6, 0xe503, 0xcd64, 0xdef7, 0xffff, 0xffff, 0xffff, 0xffff, 0xffff, 0xffff, 0xffff, 0xffff, 0xffff, 0xffff, 0xffff, 0xffff, 0xffff, 0xffff, 0xffff, 0xffff, 0xffff, 0xffff, 0xffff, 0xffff, 0xffff, 0xffff, 0xb294, 0x0000, 0x14a5, 0xffff, 0xffff, 0xffff, 0xffff, 0xffff, 0xffff, 0xffff, 0xffff, 0xffff, 0xffff, 0xffff, 0xffff, 0xffff, 0xffff, 0xffff, 0xffff, 0xffff, 0xffff, 0xffff, 0xffff, 0xffff, 0xffff, 0xffff, 0xffff, 0xffff, 0xffff, 0xffff, 0xffff,
		0xffff, 0xffff, 0xffff, 0xffff, 0xffff, 0xffff, 0xffff, 0xffff, 0xdfff, 0xd39c, 0x0000, 0xc739, 0x38c6, 0xffff, 0xffff, 0xffff, 0x56b6, 0xa003, 0x507d, 0xdef7, 0xffff, 0xffff, 0xffff, 0xffff, 0xffff, 0xffff, 0xffff, 0xffff, 0xffff, 0xffff, 0xffff, 0xffff, 0xffff, 0xd9ce, 0xc203, 0x97be, 0xffff, 0xffff, 0xffff, 0xffff, 0x507d, 0x282c, 0x9def, 0xffff, 0xffff, 0xffff, 0xffff, 0xffff, 0xffff, 0xffff, 0xffff, 0xffff, 0xffff, 0xffff, 0xffff, 0xffff, 0xffff, 0xffff, 0xffff, 0xffff, 0xffff, 0xffff, 0xffff, 0xffff, 0xffff, 0x9ef7, 0xeb5a, 0x0000, 0x38c6, 0xffff, 0xffff, 0xffff, 0xffff, 0xffff, 0xffff, 0xffff, 0xffff, 0xffff, 0xffff, 0xffff, 0xffff, 0xffff, 0xffff, 0xffff, 0xffff, 0xffff, 0xffff, 0xffff, 0xffff, 0xffff, 0xffff, 0xffff, 0xffff, 0xffff, 0xffff, 0xffff,
		0xffff, 0xffff, 0xffff, 0xffff, 0xffff, 0xffff, 0xffff, 0xffff, 0x3ce7, 0x0000, 0x0000, 0x38c6, 0xffff, 0xffff, 0xffff, 0xffff, 0xffff, 0xf4a5, 0xa003, 0x15a6, 0xffff, 0xffff, 0xffff, 0xffff, 0xffff, 0xffff, 0xffff, 0xffff, 0xffff, 0xffff, 0xffff, 0xffff, 0xffff, 0xf9ce, 0xc303, 0x98be, 0xffff, 0xffff, 0xffff, 0xffff, 0xb28d, 0x2824, 0x9def, 0xffff, 0xffff, 0xffff, 0xffff, 0xffff, 0xffff, 0xffff, 0xffff, 0xffff, 0xffff, 0xffff, 0xffff, 0xffff, 0xffff, 0xffff, 0xffff, 0xffff, 0xffff, 0xffff, 0xffff, 0xffff, 0xffff, 0xffff, 0xdbde, 0x0000, 0xc739, 0x1ce7, 0xffff, 0xffff, 0xffff, 0xffff, 0xffff, 0xffff, 0xffff, 0xffff, 0xffff, 0xffff, 0xffff, 0xffff, 0xffff, 0xffff, 0xffff, 0xffff, 0xffff, 0xffff, 0xffff, 0xffff, 0xffff, 0xffff, 0xffff, 0xffff, 0xffff, 0xffff,
		0xffff, 0xffff, 0xffff, 0xffff, 0xffff, 0xffff, 0xffff, 0xffff, 0xffff, 0x96b5, 0x0000, 0x1084, 0xbef7, 0xffff, 0xffff, 0xffff, 0xffff, 0xdef7, 0x5185, 0xa003, 0xb8c6, 0xffff, 0xffff, 0xffff, 0xffff, 0xffff, 0xffff, 0xffff, 0xffff, 0xffff, 0xffff, 0xffff, 0xffff, 0xbef7, 0x6a4c, 0x307d, 0xdff7, 0xffff, 0xffff, 0x5ce7, 0x493c, 0xac5c, 0xbef7, 0xffff, 0xffff, 0xffff, 0xffff, 0xffff, 0xffff, 0xffff, 0xffff, 0xffff, 0xffff, 0xffff, 0xffff, 0xffff, 0xffff, 0xffff, 0xffff, 0xffff, 0xffff, 0xffff, 0xffff, 0xffff, 0xffff, 0xffff, 0xffff, 0xb6b5, 0x0000, 0xcf7b, 0xdfff, 0xffff, 0xffff, 0xffff, 0xffff, 0xffff, 0xffff, 0xffff, 0xffff, 0xffff, 0xffff, 0xffff, 0xffff, 0xffff, 0xffff, 0xffff, 0xffff, 0xffff, 0xffff, 0xffff, 0xffff, 0xffff, 0xffff, 0xffff, 0xffff, 0xffff,
		0xffff, 0xffff, 0xffff, 0xffff, 0xffff, 0xffff, 0xffff, 0xffff, 0xffff, 0xdfff, 0x3084, 0x0000, 0xf39c, 0xffff, 0xffff, 0xffff, 0xffff, 0xffff, 0x9def, 0xac54, 0x0614, 0x3bdf, 0xffff, 0xffff, 0xffff, 0xffff, 0xffff, 0xffff, 0xffff, 0xffff, 0xffff, 0xffff, 0xffff, 0xffff, 0x97be, 0xc103, 0x307d, 0x77b6, 0x35ae, 0x8c54, 0xe503, 0xd9c6, 0xffff, 0xffff, 0xffff, 0xffff, 0xffff, 0xffff, 0xffff, 0xffff, 0xffff, 0xffff, 0xffff, 0xffff, 0xffff, 0xffff, 0xffff, 0xffff, 0xffff, 0xffff, 0xffff, 0xffff, 0xffff, 0xffff, 0xffff, 0xffff, 0xffff, 0xffff, 0x3084, 0x0000, 0x75ad, 0xffff, 0xffff, 0xffff, 0xffff, 0xffff, 0xffff, 0xffff, 0xffff, 0xffff, 0xffff, 0xffff, 0xffff, 0xffff, 0xffff, 0xffff, 0xffff, 0xffff, 0xffff, 0xffff, 0xffff, 0xffff, 0xffff, 0xffff, 0xffff, 0xffff,
		0xffff, 0xffff, 0xffff, 0xffff, 0xffff, 0xffff, 0xffff, 0xffff, 0xffff, 0xffff, 0x9ef7, 0x2c63, 0x0000, 0xb6b5, 0xffff, 0xffff, 0xffff, 0xffff, 0xffff, 0x5cdf, 0x282c, 0xac54, 0x7de7, 0xffff, 0xffff, 0xffff, 0xffff, 0xffff, 0xffff, 0xffff, 0xffff, 0xffff, 0xffff, 0xffff, 0xffff, 0x98be, 0x8c54, 0x8003, 0xa003, 0xee6c, 0xd9ce, 0xffff, 0xffff, 0xffff, 0xffff, 0xffff, 0xffff, 0xffff, 0xffff, 0xffff, 0xffff, 0xffff, 0xffff, 0xffff, 0xffff, 0xffff, 0xffff, 0xffff, 0xffff, 0xffff, 0xffff, 0xffff, 0xffff, 0xffff, 0xffff, 0xffff, 0xffff, 0xffff, 0x5def, 0x694a, 0x0000, 0x9ad6, 0xffff, 0xffff, 0xffff, 0xffff, 0xffff, 0xffff, 0xffff, 0xffff, 0xffff, 0xffff, 0xffff, 0xffff, 0xffff, 0xffff, 0xffff, 0xffff, 0xffff, 0xffff, 0xffff, 0xffff, 0xffff, 0xffff, 0xffff, 0xffff,
		0xffff, 0xffff, 0xffff, 0xffff, 0xffff, 0xffff, 0xffff, 0xffff, 0xffff, 0xffff, 0xffff, 0x1ce7, 0xc739, 0x4108, 0x9ad6, 0xffff, 0xffff, 0xffff, 0xffff, 0xffff, 0xd9ce, 0xe403, 0x307d, 0xbef7, 0xffff, 0xffff, 0xffff, 0xffff, 0xffff, 0xffff, 0xffff, 0xffff, 0xffff, 0xffff, 0xffff, 0xffff, 0xbef7, 0x1ad7, 0x1bd7, 0xdef7, 0xffff, 0xffff, 0xffff, 0xffff, 0xffff, 0xffff, 0xffff, 0xffff, 0xffff, 0xffff, 0xffff, 0xffff, 0xffff, 0xffff, 0xffff, 0xffff, 0xffff, 0xffff, 0xffff, 0xffff, 0xffff, 0xffff, 0xffff, 0xffff, 0xffff, 0xffff, 0xffff, 0xffff, 0xffff, 0x79ce, 0x0000, 0x694a, 0x5def, 0xffff, 0xffff, 0xffff, 0xffff, 0xffff, 0xffff, 0xffff, 0xffff, 0xffff, 0xffff, 0xffff, 0xffff, 0xffff, 0xffff, 0xffff, 0xffff, 0xffff, 0xffff, 0xffff, 0xffff, 0xffff, 0xffff, 0xffff,
		0xffff, 0xffff, 0xffff, 0xffff, 0xffff, 0xffff, 0xffff, 0xffff, 0xffff, 0xffff, 0xffff, 0xffff, 0x59ce, 0x0000, 0x2842, 0x3ce7, 0xffff, 0xffff, 0xffff, 0xffff, 0xffff, 0x77b6, 0xa003, 0xb395, 0xffff, 0xffff, 0xffff, 0xffff, 0xffff, 0xffff, 0xffff, 0xffff, 0xffff, 0xffff, 0xffff, 0xffff, 0xffff, 0xffff, 0xffff, 0xffff, 0xffff, 0xffff, 0xffff, 0xffff, 0xffff, 0xffff, 0xffff, 0xffff, 0xffff, 0xffff, 0xffff, 0xffff, 0xffff, 0xffff, 0xffff, 0xffff, 0xffff, 0xffff, 0xffff, 0xffff, 0xffff, 0xffff, 0xffff, 0xffff, 0xffff, 0xffff, 0xffff, 0xffff, 0xffff, 0xffff, 0x55ad, 0x0000, 0x518c, 0xffff, 0xffff, 0xffff, 0xffff, 0xffff, 0xffff, 0xffff, 0xffff, 0xffff, 0xffff, 0xffff, 0xffff, 0xffff, 0xffff, 0xffff, 0xffff, 0xffff, 0xffff, 0xffff, 0xffff, 0xffff, 0xffff, 0xffff,
		0xffff, 0xffff, 0xffff, 0xffff, 0xffff, 0xffff, 0xffff, 0xffff, 0xffff, 0xffff, 0xffff, 0xffff, 0xffff, 0x75ad, 0x0000, 0x6d6b, 0x9ef7, 0xffff, 0xffff, 0xffff, 0xffff, 0xffff, 0xf49d, 0xa003, 0x35ae, 0xffff, 0xffff, 0xffff, 0xffff, 0xffff, 0xffff, 0xffff, 0xffff, 0xffff, 0xffff, 0xffff, 0xffff, 0xffff, 0xffff, 0xffff, 0xffff, 0xffff, 0xffff, 0xffff, 0xffff, 0xffff, 0xffff, 0xffff, 0xffff, 0xffff, 0xffff, 0xffff, 0xffff, 0xffff, 0xffff, 0xffff, 0xffff, 0xffff, 0xffff, 0xffff, 0xffff, 0xffff, 0xffff, 0xffff, 0xffff, 0xffff, 0xffff, 0xffff, 0xffff, 0xffff, 0xbef7, 0xcf7b, 0x0000, 0xb6b5, 0xffff, 0xffff, 0xffff, 0xffff, 0xffff, 0xffff, 0xffff, 0xffff, 0xffff, 0xffff, 0xffff, 0xffff, 0xffff, 0xffff, 0xffff, 0xffff, 0xffff, 0xffff, 0xffff, 0xffff, 0xffff, 0xffff,
		0xffff, 0xffff, 0xffff, 0xffff, 0xffff, 0xffff, 0xffff, 0xffff, 0xffff, 0xffff, 0xffff, 0xffff, 0xffff, 0xffff, 0xd39c, 0x0000, 0x9294, 0xffff, 0xffff, 0xffff, 0xffff, 0xffff, 0xdfff, 0x7185, 0xa003, 0x98be, 0xffff, 0xffff, 0xffff, 0xffff, 0xffff, 0xffff, 0xbdef, 0x1ad7, 0x98be, 0xd9ce, 0xbeef, 0xffff, 0xffff, 0xffff, 0xffff, 0xffff, 0xffff, 0xffff, 0xffff, 0xffff, 0xffff, 0xffff, 0xffff, 0xffff, 0xffff, 0xffff, 0xffff, 0xffff, 0xffff, 0xffff, 0xffff, 0xffff, 0xffff, 0xffff, 0xffff, 0xffff, 0xffff, 0xffff, 0xffff, 0xffff, 0xffff, 0xffff, 0xffff, 0xffff, 0xffff, 0x1ce7, 0xa631, 0xc318, 0xfbde, 0xffff, 0xffff, 0xffff, 0xffff, 0xffff, 0xffff, 0xffff, 0xffff, 0xffff, 0xffff, 0xffff, 0xffff, 0xffff, 0xffff, 0xffff, 0xffff, 0xffff, 0xffff, 0xffff, 0xffff, 0xffff,
		0xffff, 0xffff, 0xffff, 0xffff, 0xffff, 0xffff, 0xffff, 0xffff, 0xffff, 0xffff, 0xffff, 0xffff, 0xffff, 0xffff, 0x9ef7, 0x6d6b, 0x0000, 0x96b5, 0xffff, 0xffff, 0xffff, 0xffff, 0xffff, 0xdef7, 0x0f75, 0xc303, 0xb9c6, 0xffff, 0xffff, 0xffff, 0xffff, 0x1ad7, 0x8c54, 0xc003, 0x0604, 0xa003, 0xcd5c, 0x5ce7, 0xffff, 0xffff, 0xffff, 0xffff, 0xffff, 0xffff, 0xffff, 0xffff, 0xffff, 0xffff, 0xffff, 0xffff, 0xffff, 0xffff, 0xffff, 0xffff, 0xffff, 0xffff, 0xffff, 0xffff, 0xffff, 0xffff, 0xffff, 0xffff, 0xffff, 0xffff, 0xffff, 0xffff, 0xffff, 0xffff, 0xffff, 0xffff, 0xffff, 0xffff, 0x18c6, 0x0000, 0xeb5a, 0x9ef7, 0xffff, 0xffff, 0xffff, 0xffff, 0xffff, 0xffff, 0xffff, 0xffff, 0xffff, 0xffff, 0xffff, 0xffff, 0xffff, 0xffff, 0xffff, 0xffff, 0xffff, 0xffff, 0xffff, 0xffff,
		0xffff, 0xffff, 0xffff, 0xffff, 0xffff, 0xffff, 0xffff, 0xffff, 0xffff, 0xffff, 0xffff, 0xffff, 0xffff, 0xffff, 0xffff, 0x3ce7, 0x0842, 0x0000, 0x79ce, 0xffff, 0xffff, 0xffff, 0xffff, 0xffff, 0x9de7, 0xad5c, 0xe503, 0x98be, 0xffff, 0xffff, 0xfad6, 0x060c, 0x0614, 0x98be, 0x9def, 0x98be, 0xe60b, 0x0e6d, 0xdef7, 0xffff, 0xffff, 0xffff, 0xffff, 0xffff, 0xffff, 0xffff, 0xffff, 0xffff, 0xffff, 0xffff, 0xffff, 0xffff, 0xffff, 0xffff, 0xffff, 0xffff, 0xffff, 0xffff, 0xffff, 0xffff, 0xffff, 0xffff, 0xffff, 0xffff, 0xffff, 0xffff, 0xffff, 0xffff, 0xffff, 0xffff, 0xffff, 0xffff, 0xffff, 0x34a5, 0x0000, 0xd39c, 0xffff, 0xffff, 0xffff, 0xffff, 0xffff, 0xffff, 0xffff, 0xffff, 0xffff, 0xffff, 0xffff, 0xffff, 0xffff, 0xffff, 0xffff, 0xffff, 0xffff, 0xffff, 0xffff, 0xffff,
		0xffff, 0xffff, 0xffff, 0xffff, 0xffff, 0xffff, 0xffff, 0xffff, 0xffff, 0xffff, 0xffff, 0xffff, 0xffff, 0xffff, 0xffff, 0xffff, 0x9ad6, 0x0000, 0x6529, 0x3ce7, 0xffff, 0xffff, 0xffff, 0xffff, 0xffff, 0x5ce7, 0xac54, 0xc203, 0x5185, 0xb39d, 0x2834, 0x071c, 0xd9c6, 0xffff, 0xffff, 0xffff, 0x56b6, 0x8003, 0xb8c6, 0xffff, 0xffff, 0xffff, 0xffff, 0xffff, 0xffff, 0xffff, 0xffff, 0xffff, 0xffff, 0xffff, 0xffff, 0xffff, 0xffff, 0xffff, 0xffff, 0xffff, 0xffff, 0xffff, 0xffff, 0xffff, 0xffff, 0xffff, 0xffff, 0xffff, 0xffff, 0xffff, 0xffff, 0xffff, 0xffff, 0xffff, 0xffff, 0xffff, 0xffff, 0x9ef7, 0x2c63, 0x0000, 0x59ce, 0xffff, 0xffff, 0xffff, 0xffff, 0xffff, 0xffff, 0xffff, 0xffff, 0xffff, 0xffff, 0xffff, 0xffff, 0xffff, 0xffff, 0xffff, 0xffff, 0xffff, 0xffff, 0xffff,
		0xffff, 0xffff, 0xffff, 0xffff, 0xffff, 0xffff, 0xffff, 0xffff, 0xffff, 0xffff, 0xffff, 0xffff, 0xffff, 0xffff, 0xffff, 0xffff, 0xffff, 0xb6b5, 0x0000, 0xeb5a, 0x7def, 0xffff, 0xffff, 0xffff, 0xffff, 0xffff, 0x7ce7, 0x728d, 0xe61b, 0xa203, 0xe503, 0xad64, 0xdef7, 0xffff, 0xffff, 0xffff, 0x5cdf, 0xa003, 0x15a6, 0xffff, 0xffff, 0xffff, 0xffff, 0xffff, 0xffff, 0xffff, 0xffff, 0xffff, 0xffff, 0xffff, 0xffff, 0xffff, 0xffff, 0xffff, 0xffff, 0xffff, 0xffff, 0xffff, 0xffff, 0xffff, 0xffff, 0xffff, 0xffff, 0xffff, 0xffff, 0xffff, 0xffff, 0xffff, 0xffff, 0xffff, 0xffff, 0xffff, 0xffff, 0xffff, 0xdbde, 0x2000, 0x8631, 0x1ce7, 0xffff, 0xffff, 0xffff, 0xffff, 0xffff, 0xffff, 0xffff, 0xffff, 0xffff, 0xffff, 0xffff, 0xffff, 0xffff, 0xffff, 0xffff, 0xffff, 0xffff, 0xffff,
		0xffff, 0xffff, 0xffff, 0xffff, 0xffff, 0xffff, 0xffff, 0xffff, 0xffff, 0xffff, 0xffff, 0xffff, 0xffff, 0xffff, 0xffff, 0xffff, 0xffff, 0xdfff, 0x14a5, 0x0000, 0x718c, 0xdfff, 0xffff, 0xffff, 0xffff, 0xffff, 0xffff, 0xffff, 0x7ce7, 0x97be, 0x282c, 0x493c, 0x7ce7, 0xffff, 0xffff, 0xffff, 0xfad6, 0x8003, 0x56b6, 0xffff, 0xffff, 0xffff, 0xffff, 0xffff, 0xffff, 0xffff, 0xffff, 0xffff, 0xffff, 0xffff, 0xffff, 0xffff, 0xffff, 0xffff, 0xffff, 0xffff, 0xffff, 0x7ce7, 0x36ae, 0xd49d, 0x98c6, 0xdff7, 0xffff, 0xffff, 0xffff, 0xffff, 0xffff, 0xffff, 0xffff, 0xffff, 0xffff, 0xffff, 0xffff, 0xffff, 0xffff, 0xd7bd, 0x0000, 0xae73, 0xbef7, 0xffff, 0xffff, 0xffff, 0xffff, 0xffff, 0xffff, 0xffff, 0xffff, 0xffff, 0xffff, 0xffff, 0xffff, 0xffff, 0xffff, 0xffff, 0xffff, 0xffff,
		0xffff, 0xffff, 0xffff, 0xffff, 0xffff, 0xffff, 0xffff, 0xffff, 0xffff, 0xffff, 0xffff, 0xffff, 0xffff, 0xffff, 0xffff, 0xffff, 0xffff, 0xffff, 0xbef7, 0xcf7b, 0x0000, 0x75ad, 0xffff, 0xffff, 0xffff, 0xffff, 0xffff, 0xffff, 0xffff, 0xffff, 0x56ae, 0xa003, 0x507d, 0x5bdf, 0xdef7, 0x3bdf, 0xee6c, 0x493c, 0x7de7, 0xffff, 0xffff, 0xffff, 0xffff, 0xffff, 0xffff, 0xffff, 0xffff, 0xffff, 0xffff, 0xffff, 0xffff, 0xffff, 0xffff, 0xffff, 0xffff, 0xffff, 0x35ae, 0x2834, 0x8003, 0xa103, 0x8003, 0x307d, 0x7de7, 0xffff, 0xffff, 0xffff, 0xffff, 0xffff, 0xffff, 0xffff, 0xffff, 0xffff, 0xffff, 0xffff, 0xffff, 0xffff, 0xcf7b, 0x0000, 0x96b5, 0xffff, 0xffff, 0xffff, 0xffff, 0xffff, 0xffff, 0xffff, 0xffff, 0xffff, 0xffff, 0xffff, 0xffff, 0xffff, 0xffff, 0xffff, 0xffff, 0xffff,
		0xffff, 0xffff, 0xffff, 0xffff, 0xffff, 0xffff, 0xffff, 0xffff, 0xffff, 0xffff, 0xffff, 0xffff, 0xffff, 0xffff, 0xffff, 0xffff, 0xffff, 0xffff, 0xffff, 0x5def, 0x2842, 0x0000, 0x59ce, 0xffff, 0xffff, 0xffff, 0xffff, 0xffff, 0xffff, 0xffff, 0xdfff, 0xb395, 0x8003, 0x071c, 0xad5c, 0xe503, 0x061c, 0xb9c6, 0xffff, 0xffff, 0xffff, 0xffff, 0xffff, 0xffff, 0xffff, 0xffff, 0xffff, 0xffff, 0xffff, 0xffff, 0xffff, 0xffff, 0xffff, 0xffff, 0xffff, 0x77be, 0xa003, 0x0f6d, 0x1ad7, 0x5ce7, 0x35ae, 0xe403, 0xee6c, 0xdef7, 0xffff, 0xffff, 0xffff, 0xffff, 0xffff, 0xffff, 0xffff, 0xffff, 0xffff, 0xffff, 0xffff, 0x18c6, 0xe739, 0x0000, 0xb6b5, 0xffff, 0xffff, 0xffff, 0xffff, 0xffff, 0xffff, 0xffff, 0xffff, 0xffff, 0xffff, 0xffff, 0xffff, 0xffff, 0xffff, 0xffff, 0xffff, 0xffff,
		0xffff, 0xffff, 0xffff, 0xffff, 0xffff, 0xffff, 0xffff, 0xffff, 0xffff, 0xffff, 0xffff, 0xffff, 0xffff, 0xffff, 0xffff, 0xffff, 0xffff, 0xffff, 0xffff, 0xffff, 0xdbde, 0x0000, 0x4529, 0xdbde, 0xffff, 0xffff, 0xffff, 0xffff, 0xffff, 0xffff, 0xffff, 0xffff, 0xb8c6, 0x928d, 0x507d, 0xd395, 0x3bdf, 0xffff, 0xffff, 0xffff, 0xffff, 0xffff, 0xffff, 0xffff, 0xffff, 0xffff, 0xffff, 0xffff, 0xffff, 0xffff, 0xffff, 0xffff, 0xffff, 0xffff, 0xdef7, 0xee6c, 0x0724, 0x5cdf, 0xffff, 0xffff, 0xffff, 0x56b6, 0xa003, 0xb8c6, 0xffff, 0xffff, 0xffff, 0xffff, 0xffff, 0xffff, 0xffff, 0xffff, 0xffff, 0xbef7, 0xd39c, 0x0000, 0x0421, 0xf7bd, 0xffff, 0xffff, 0xffff, 0xffff, 0xffff, 0xffff, 0xffff, 0xffff, 0xffff, 0xffff, 0xffff, 0xffff, 0xffff, 0xffff, 0xffff, 0xffff, 0xffff, 0xffff,
		0xffff, 0xffff, 0xffff, 0xffff, 0xffff, 0xffff, 0xffff, 0xffff, 0xffff, 0xffff, 0xffff, 0xffff, 0xffff, 0xffff, 0xffff, 0xffff, 0xffff, 0xffff, 0xffff, 0xffff, 0xffff, 0xf7bd, 0x0000, 0x4d6b, 0x7def, 0xffff, 0xffff, 0xffff, 0xffff, 0xffff, 0xffff, 0xffff, 0xffff, 0xffff, 0xffff, 0xffff, 0xffff, 0xffff, 0xffff, 0xffff, 0xffff, 0xffff, 0xffff, 0x1ad7, 0x97be, 0xb8c6, 0x7ce7, 0xffff, 0xffff, 0xffff, 0xffff, 0xffff, 0xffff, 0xffff, 0xbef7, 0xab4c, 0xcd5c, 0xdfff, 0xffff, 0xffff, 0xffff, 0x5ce7, 0xe60b, 0x36ae, 0xffff, 0xffff, 0xffff, 0xffff, 0xffff, 0xffff, 0xffff, 0xffff, 0x1ce7, 0xef7b, 0x0000, 0x2c63, 0xdbde, 0xffff, 0xffff, 0xffff, 0xffff, 0xffff, 0xffff, 0xffff, 0xffff, 0xffff, 0xffff, 0xffff, 0xffff, 0xffff, 0xffff, 0xffff, 0xffff, 0xffff, 0xffff, 0xffff,
		0xffff, 0xffff, 0xffff, 0xffff, 0xffff, 0xffff, 0xffff, 0xffff, 0xffff, 0xffff, 0xffff, 0xffff, 0xffff, 0xffff, 0xffff, 0xffff, 0xffff, 0xffff, 0xffff, 0xffff, 0xffff, 0xffff, 0xf39c, 0x0000, 0xef7b, 0xbef7, 0xffff, 0xffff, 0xffff, 0xffff, 0xffff, 0xffff, 0xffff, 0xffff, 0xffff, 0xffff, 0xffff, 0xffff, 0xffff, 0xffff, 0xffff, 0xdef7, 0xb295, 0xc403, 0xa003, 0xa003, 0x2834, 0x98be, 0xffff, 0xffff, 0xffff, 0xffff, 0xffff, 0xffff, 0xdef7, 0x0e6d, 0x493c, 0x9def, 0xffff, 0xffff, 0xffff, 0xb9c6, 0xc303, 0xb9c6, 0xffff, 0xffff, 0xffff, 0xffff, 0xffff, 0xffff, 0xffff, 0x59ce, 0x8631, 0x0000, 0x518c, 0xbef7, 0xffff, 0xffff, 0xffff, 0xffff, 0xffff, 0xffff, 0xffff, 0xffff, 0xffff, 0xffff, 0xffff, 0xffff, 0xffff, 0xffff, 0xffff, 0xffff, 0xffff, 0xffff, 0xffff, 0xffff,
		0xffff, 0xffff, 0xffff, 0xffff, 0xffff, 0xffff, 0xffff, 0xffff, 0xffff, 0xffff, 0xffff, 0xffff, 0xffff, 0xffff, 0xffff, 0xffff, 0xffff, 0xffff, 0xffff, 0xffff, 0xffff, 0xffff, 0xdfff, 0x1084, 0x0000, 0x14a5, 0xffff, 0xffff, 0xffff, 0xffff, 0xffff, 0xffff, 0xffff, 0xffff, 0xffff, 0xffff, 0xffff, 0xffff, 0xffff, 0xffff, 0xffff, 0xf49d, 0xa003, 0xee6c, 0x97be, 0x77be, 0xcd64, 0xa003, 0x98be, 0xffff, 0xffff, 0xffff, 0xffff, 0xffff, 0xffff, 0x98be, 0xc003, 0xd395, 0x9def, 0xbeef, 0xface, 0x6a44, 0x8b4c, 0xbef7, 0xffff, 0xffff, 0xffff, 0xffff, 0xffff, 0xbef7, 0x34a5, 0x0000, 0x0000, 0xb6b5, 0xdfff, 0xffff, 0xffff, 0xffff, 0xffff, 0xffff, 0xffff, 0xffff, 0xffff, 0xffff, 0xffff, 0xffff, 0xffff, 0xffff, 0xffff, 0xffff, 0xffff, 0xffff, 0xffff, 0xffff, 0xffff, 0xffff,
		0xffff, 0xffff, 0xffff, 0xffff, 0xffff, 0xffff, 0xffff, 0xffff, 0xffff, 0xffff, 0xffff, 0xffff, 0xffff, 0xffff, 0xffff, 0xffff, 0xffff, 0xffff, 0xffff, 0xffff, 0xffff, 0xffff, 0xffff, 0x7def, 0xeb5a, 0x0000, 0x18c6, 0xffff, 0xffff, 0xffff, 0xffff, 0xffff, 0xffff, 0xffff, 0xffff, 0xffff, 0xffff, 0xffff, 0xffff, 0xffff, 0x7ce7, 0x2834, 0x8b54, 0x7de7, 0xffff, 0xffff, 0xbef7, 0x2f75, 0xee6c, 0xffff, 0xffff, 0xffff, 0xffff, 0xffff, 0xffff, 0xffff, 0x928d, 0xa003, 0x4a44, 0x8c5c, 0xc403, 0x4834, 0xface, 0xffff, 0xffff, 0xffff, 0xffff, 0xffff, 0x5def, 0xcf7b, 0x0000, 0x694a, 0xdbde, 0xffff, 0xffff, 0xffff, 0xffff, 0xffff, 0xffff, 0xffff, 0xffff, 0xffff, 0xffff, 0xffff, 0xffff, 0xffff, 0xffff, 0xffff, 0xffff, 0xffff, 0xffff, 0xffff, 0xffff, 0xffff, 0xffff, 0xffff,
		0xffff, 0xffff, 0xffff, 0xffff, 0xffff, 0xffff, 0xffff, 0xffff, 0xffff, 0xffff, 0xffff, 0xffff, 0xffff, 0xffff, 0xffff, 0xffff, 0xffff, 0xffff, 0xffff, 0xffff, 0xffff, 0xffff, 0xffff, 0xffff, 0xdbde, 0xc318, 0x6108, 0xbad6, 0xffff, 0xffff, 0xffff, 0xffff, 0xffff, 0xffff, 0xffff, 0xffff, 0xffff, 0xffff, 0xffff, 0xffff, 0x1bd7, 0xc303, 0xb395, 0xffff, 0xffff, 0xffff, 0xffff, 0x98c6, 0x0724, 0x7ce7, 0xffff, 0xffff, 0xffff, 0xffff, 0xffff, 0xffff, 0xdef7, 0xb8c6, 0x493c, 0xc403, 0xd395, 0x9def, 0xffff, 0xffff, 0xffff, 0xffff, 0xffff, 0x79ce, 0xe739, 0x0000, 0x718c, 0x9ef7, 0xffff, 0xffff, 0xffff, 0xffff, 0xffff, 0xffff, 0xffff, 0xffff, 0xffff, 0xffff, 0xffff, 0xffff, 0xffff, 0xffff, 0xffff, 0xffff, 0xffff, 0xffff, 0xffff, 0xffff, 0xffff, 0xffff, 0xffff, 0xffff,
		0xffff, 0xffff, 0xffff, 0xffff, 0xffff, 0xffff, 0xffff, 0xffff, 0xffff, 0xffff, 0xffff, 0xffff, 0xffff, 0xffff, 0xffff, 0xffff, 0xffff, 0xffff, 0xffff, 0xffff, 0xffff, 0xffff, 0xffff, 0xffff, 0xffff, 0x38c6, 0x0000, 0xaa52, 0x7def, 0xffff, 0xffff, 0xffff, 0xffff, 0xffff, 0xffff, 0xffff, 0xffff, 0xffff, 0xffff, 0xffff, 0x1bd7, 0xe303, 0x728d, 0xffff, 0xffff, 0xffff, 0xffff, 0xb295, 0x8b4c, 0xbdef, 0xffff, 0xffff, 0xffff, 0xffff, 0xffff, 0xffff, 0xffff, 0xffff, 0xee6c, 0xef74, 0xffff, 0xffff, 0xffff, 0xffff, 0xffff, 0xbef7, 0x55ad, 0x0000, 0x0000, 0x96b5, 0xdfff, 0xffff, 0xffff, 0xffff, 0xffff, 0xffff, 0xffff, 0xffff, 0xffff, 0xffff, 0xffff, 0xffff, 0xffff, 0xffff, 0xffff, 0xffff, 0xffff, 0xffff, 0xffff, 0xffff, 0xffff, 0xffff, 0xffff, 0xffff, 0xffff, 0xffff,
		0xffff, 0xffff, 0xffff, 0xffff, 0xffff, 0xffff, 0xffff, 0xffff, 0xffff, 0xffff, 0xffff, 0xffff, 0xffff, 0xffff, 0xffff, 0xffff, 0xffff, 0xffff, 0xffff, 0xffff, 0xffff, 0xffff, 0xffff, 0xffff, 0xffff, 0xffff, 0x34a5, 0x0000, 0xae73, 0xbef7, 0xffff, 0xffff, 0xffff, 0xffff, 0xffff, 0xffff, 0xffff, 0xffff, 0xffff, 0xffff, 0x1ad7, 0x060c, 0x2834, 0xd9c6, 0xffff, 0xffff, 0x77b6, 0xa003, 0xb395, 0xffff, 0xffff, 0xffff, 0xffff, 0xffff, 0xffff, 0xffff, 0xffff, 0x5cdf, 0x2724, 0x718d, 0xffff, 0xffff, 0xffff, 0xffff, 0x5def, 0xcf7b, 0x0000, 0x494a, 0x9ad6, 0xffff, 0xffff, 0xffff, 0xffff, 0xffff, 0xffff, 0xffff, 0xffff, 0xffff, 0xffff, 0xffff, 0xffff, 0xffff, 0xffff, 0xffff, 0xffff, 0xffff, 0xffff, 0xffff, 0xffff, 0xffff, 0xffff, 0xffff, 0xffff, 0xffff, 0xffff, 0xffff,
		0xffff, 0xffff, 0xffff, 0xffff, 0xffff, 0xffff, 0xffff, 0xffff, 0xffff, 0xffff, 0xffff, 0xffff, 0xffff, 0xffff, 0xffff, 0xffff, 0xffff, 0xffff, 0xffff, 0xffff, 0xffff, 0xffff, 0xffff, 0xffff, 0xffff, 0xffff, 0xbef7, 0x518c, 0x0000, 0xd39c, 0xffff, 0xffff, 0xffff, 0xffff, 0xffff, 0xffff, 0xffff, 0xffff, 0xffff, 0x5ce7, 0x0e6d, 0xc403, 0xc403, 0xe503, 0x3075, 0x307d, 0xc403, 0xad64, 0x7de7, 0xffff, 0xffff, 0xffff, 0xffff, 0xffff, 0xffff, 0xffff, 0xffff, 0xb395, 0x6003, 0x56ae, 0xffff, 0xffff, 0xffff, 0x9ad6, 0x694a, 0x0000, 0x718c, 0x5def, 0xffff, 0xffff, 0xffff, 0xffff, 0xffff, 0xffff, 0xffff, 0xffff, 0xffff, 0xffff, 0xffff, 0xffff, 0xffff, 0xffff, 0xffff, 0xffff, 0xffff, 0xffff, 0xffff, 0xffff, 0xffff, 0xffff, 0xffff, 0xffff, 0xffff, 0xffff, 0xffff, 0xffff,
		0xffff, 0xffff, 0xffff, 0xffff, 0xffff, 0xffff, 0xffff, 0xffff, 0xffff, 0xffff, 0xffff, 0xffff, 0xffff, 0xffff, 0xffff, 0xffff, 0xffff, 0xffff, 0xffff, 0xffff, 0xffff, 0xffff, 0xffff, 0xffff, 0xffff, 0xffff, 0xffff, 0x7def, 0x8e73, 0x0000, 0xd7bd, 0xffff, 0xffff, 0xffff, 0xffff, 0xffff, 0xffff, 0xffff, 0xd9c6, 0x6a4c, 0xa003, 0xf49d, 0xd8c6, 0xd49d, 0x8b4c, 0x8b4c, 0xd49d, 0x7ce7, 0xffff, 0xffff, 0xffff, 0xffff, 0xffff, 0xffff, 0xffff, 0x9def, 0x718d, 0xc103, 0x15a6, 0xdfff, 0xffff, 0xdfff, 0x96b5, 0x0000, 0x0000, 0x55ad, 0xdfff, 0xffff, 0xffff, 0xffff, 0xffff, 0xffff, 0xffff, 0xffff, 0xffff, 0xffff, 0xffff, 0xffff, 0xffff, 0xffff, 0xffff, 0xffff, 0xffff, 0xffff, 0xffff, 0xffff, 0xffff, 0xffff, 0xffff, 0xffff, 0xffff, 0xffff, 0xffff, 0xffff, 0xffff, 0xffff,
		0xffff, 0xffff, 0xffff, 0xffff, 0xffff, 0xffff, 0xffff, 0xffff, 0xffff, 0xffff, 0xffff, 0xffff, 0xffff, 0xffff, 0xffff, 0xffff, 0xffff, 0xffff, 0xffff, 0xffff, 0xffff, 0xffff, 0xffff, 0xffff, 0xffff, 0xffff, 0xffff, 0xffff, 0x1ce7, 0x4529, 0x0000, 0xbad6, 0xffff, 0xffff, 0xffff, 0xffff, 0xffff, 0x36ae, 0xc403, 0x4934, 0x97be, 0xffff, 0xffff, 0xffff, 0xbeef, 0xbeef, 0xffff, 0xffff, 0xffff, 0xffff, 0xffff, 0xffff, 0xffff, 0xffff, 0x1bd7, 0xac5c, 0xe603, 0x98be, 0xffff, 0xffff, 0x5def, 0x3084, 0x0000, 0xe739, 0x59ce, 0xffff, 0xffff, 0xffff, 0xffff, 0xffff, 0xffff, 0xffff, 0xffff, 0xffff, 0xffff, 0xffff, 0xffff, 0xffff, 0xffff, 0xffff, 0xffff, 0xffff, 0xffff, 0xffff, 0xffff, 0xffff, 0xffff, 0xffff, 0xffff, 0xffff, 0xffff, 0xffff, 0xffff, 0xffff, 0xffff, 0xffff,
		0xffff, 0xffff, 0xffff, 0xffff, 0xffff, 0xffff, 0xffff, 0xffff, 0xffff, 0xffff, 0xffff, 0xffff, 0xffff, 0xffff, 0xffff, 0xffff, 0xffff, 0xffff, 0xffff, 0xffff, 0xffff, 0xffff, 0xffff, 0xffff, 0xffff, 0xffff, 0xffff, 0xffff, 0xffff, 0x79ce, 0x0000, 0xe739, 0x3ce7, 0xffff, 0xffff, 0x9def, 0x7185, 0x6003, 0x0e6d, 0x3bdf, 0xffff, 0xffff, 0xffff, 0xffff, 0xffff, 0xffff, 0xffff, 0xffff, 0xffff, 0xffff, 0xffff, 0xffff, 0xffff, 0x77be, 0xe603, 0xac5c, 0x1ad7, 0xffff, 0xffff, 0xbad6, 0xaa52, 0x0000, 0xef7b, 0x3ce7, 0xffff, 0xffff, 0xffff, 0xffff, 0xffff, 0xffff, 0xffff, 0xffff, 0xffff, 0xffff, 0xffff, 0xffff, 0xffff, 0xffff, 0xffff, 0xffff, 0xffff, 0xffff, 0xffff, 0xffff, 0xffff, 0xffff, 0xffff, 0xffff, 0xffff, 0xffff, 0xffff, 0xffff, 0xffff, 0xffff, 0xffff, 0xffff,
		0xffff, 0xffff, 0xffff, 0xffff, 0xffff, 0xffff, 0xffff, 0xffff, 0xffff, 0xffff, 0xffff, 0xffff, 0xffff, 0xffff, 0xffff, 0xffff, 0xffff, 0xffff, 0xffff, 0xffff, 0xffff, 0xffff, 0xffff, 0xffff, 0xffff, 0xffff, 0xffff, 0xffff, 0xffff, 0xffff, 0x96b5, 0x0000, 0xef7b, 0x9ef7, 0x1bd7, 0xac5c, 0xa003, 0xd395, 0xbef7, 0xffff, 0xffff, 0xffff, 0xffff, 0xffff, 0xffff, 0xffff, 0xffff, 0xffff, 0xffff, 0xffff, 0xffff, 0xbdef, 0xd39d, 0xa003, 0x507d, 0x9def, 0xffff, 0xffff, 0xd7bd, 0xa210, 0x0000, 0x34a5, 0xdfff, 0xffff, 0xffff, 0xffff, 0xffff, 0xffff, 0xffff, 0xffff, 0xffff, 0xffff, 0xffff, 0xffff, 0xffff, 0xffff, 0xffff, 0xffff, 0xffff, 0xffff, 0xffff, 0xffff, 0xffff, 0xffff, 0xffff, 0xffff, 0xffff, 0xffff, 0xffff, 0xffff, 0xffff, 0xffff, 0xffff, 0xffff, 0xffff, 0xffff,
		0xffff, 0xffff, 0xffff, 0xffff, 0xffff, 0xffff, 0xffff, 0xffff, 0xffff, 0xffff, 0xffff, 0xffff, 0xffff, 0xffff, 0xffff, 0xffff, 0xffff, 0xffff, 0xffff, 0xffff, 0xffff, 0xffff, 0xffff, 0xffff, 0xffff, 0xffff, 0xffff, 0xffff, 0xffff, 0xffff, 0xdfff, 0x718c, 0x0000, 0x4f7c, 0x4a44, 0x271c, 0x77be, 0xffff, 0xffff, 0xffff, 0xffff, 0xffff, 0xffff, 0xffff, 0xffff, 0xffff, 0xffff, 0xffff, 0xffff, 0xffff, 0x3bdf, 0xee6c, 0xa003, 0xf49d, 0xdef7, 0xffff, 0x7def, 0x9294, 0x0000, 0xa631, 0x38c6, 0xffff, 0xffff, 0xffff, 0xffff, 0xffff, 0xffff, 0xffff, 0xffff, 0xffff, 0xffff, 0xffff, 0xffff, 0xffff, 0xffff, 0xffff, 0xffff, 0xffff, 0xffff, 0xffff, 0xffff, 0xffff, 0xffff, 0xffff, 0xffff, 0xffff, 0xffff, 0xffff, 0xffff, 0xffff, 0xffff, 0xffff, 0xffff, 0xffff, 0xffff, 0xffff,
		0xffff, 0xffff, 0xffff, 0xffff, 0xffff, 0xffff, 0xffff, 0xffff, 0xffff, 0xffff, 0xffff, 0xffff, 0xffff, 0xffff, 0xffff, 0xffff, 0xffff, 0xffff, 0xffff, 0xffff, 0xffff, 0xffff, 0xffff, 0xffff, 0xffff, 0xffff, 0xffff, 0xffff, 0xffff, 0xffff, 0xffff, 0x9ef7, 0x2c63, 0x0000, 0x072b, 0xface, 0xffff, 0xffff, 0xffff, 0xffff, 0xffff, 0xffff, 0xffff, 0xffff, 0xffff, 0xffff, 0xffff, 0xffff, 0xffff, 0xb8c6, 0x072c, 0x282c, 0x98c6, 0xffff, 0xffff, 0xdbde, 0x0c63, 0x0000, 0x6d6b, 0x1ce7, 0xffff, 0xffff, 0xffff, 0xffff, 0xffff, 0xffff, 0xffff, 0xffff, 0xffff, 0xffff, 0xffff, 0xffff, 0xffff, 0xffff, 0xffff, 0xffff, 0xffff, 0xffff, 0xffff, 0xffff, 0xffff, 0xffff, 0xffff, 0xffff, 0xffff, 0xffff, 0xffff, 0xffff, 0xffff, 0xffff, 0xffff, 0xffff, 0xffff, 0xffff, 0xffff, 0xffff,
		0xffff, 0xffff, 0xffff, 0xffff, 0xffff, 0xffff, 0xffff, 0xffff, 0xffff, 0xffff, 0xffff, 0xffff, 0xffff, 0xffff, 0xffff, 0xffff, 0xffff, 0xffff, 0xffff, 0xffff, 0xffff, 0xffff, 0xffff, 0xffff, 0xffff, 0xffff, 0xffff, 0xffff, 0xffff, 0xffff, 0xffff, 0xffff, 0x5def, 0x0842, 0x0000, 0x79ce, 0xffff, 0xffff, 0xffff, 0xffff, 0xffff, 0xffff, 0xffff, 0xffff, 0xffff, 0xffff, 0xffff, 0xbef7, 0xd49d, 0xa003, 0xee64, 0x5cdf, 0xffff, 0xffff, 0x38c6, 0x6108, 0x0000, 0xf39c, 0xbef7, 0xffff, 0xffff, 0xffff, 0xffff, 0xffff, 0xffff, 0xffff, 0xffff, 0xffff, 0xffff, 0xffff, 0xffff, 0xffff, 0xffff, 0xffff, 0xffff, 0xffff, 0xffff, 0xffff, 0xffff, 0xffff, 0xffff, 0xffff, 0xffff, 0xffff, 0xffff, 0xffff, 0xffff, 0xffff, 0xffff, 0xffff, 0xffff, 0xffff, 0xffff, 0xffff, 0xffff, 0xffff,
		0xffff, 0xffff, 0xffff, 0xffff, 0xffff, 0xffff, 0xffff, 0xffff, 0xffff, 0xffff, 0xffff, 0xffff, 0xffff, 0xffff, 0xffff, 0xffff, 0xffff, 0xffff, 0xffff, 0xffff, 0xffff, 0xffff, 0xffff, 0xffff, 0xffff, 0xffff, 0xffff, 0xffff, 0xffff, 0xffff, 0xffff, 0xffff, 0xffff, 0x79ce, 0x0000, 0xa631, 0x1ce7, 0xffff, 0xffff, 0xffff, 0xffff, 0xffff, 0xffff, 0xffff, 0xffff, 0xffff, 0x5ce7, 0xee6c, 0xa003, 0xb395, 0xbef7, 0xffff, 0x9ef7, 0xb294, 0x0000, 0xe318, 0x18c6, 0xffff, 0xffff, 0xffff, 0xffff, 0xffff, 0xffff, 0xffff, 0xffff, 0xffff, 0xffff, 0xffff, 0xffff, 0xffff, 0xffff, 0xffff, 0xffff, 0xffff, 0xffff, 0xffff, 0xffff, 0xffff, 0xffff, 0xffff, 0xffff, 0xffff, 0xffff, 0xffff, 0xffff, 0xffff, 0xffff, 0xffff, 0xffff, 0xffff, 0xffff, 0xffff, 0xffff, 0xffff, 0xffff, 0xffff,
		0xffff, 0xffff, 0xffff, 0xffff, 0xffff, 0xffff, 0xffff, 0xffff, 0xffff, 0xffff, 0xffff, 0xffff, 0xffff, 0xffff, 0xffff, 0xffff, 0xffff, 0xffff, 0xffff, 0xffff, 0xffff, 0xffff, 0xffff, 0xffff, 0xffff, 0xffff, 0xffff, 0xffff, 0xffff, 0xffff, 0xffff, 0xffff, 0xffff, 0xffff, 0xd7bd, 0x0000, 0x4d6b, 0x9ef7, 0xffff, 0xffff, 0xffff, 0xffff, 0xffff, 0xffff, 0xffff, 0x98be, 0x282c, 0xe503, 0x77be, 0xffff, 0xffff, 0xfbde, 0x2c63, 0x0000, 0x4d6b, 0xfbde, 0xffff, 0xffff, 0xffff, 0xffff, 0xffff, 0xffff, 0xffff, 0xffff, 0xffff, 0xffff, 0xffff, 0xffff, 0xffff, 0xffff, 0xffff, 0xffff, 0xffff, 0xffff, 0xffff, 0xffff, 0xffff, 0xffff, 0xffff, 0xffff, 0xffff, 0xffff, 0xffff, 0xffff, 0xffff, 0xffff, 0xffff, 0xffff, 0xffff, 0xffff, 0xffff, 0xffff, 0xffff, 0xffff, 0xffff, 0xffff,
		0xffff, 0xffff, 0xffff, 0xffff, 0xffff, 0xffff, 0xffff, 0xffff, 0xffff, 0xffff, 0xffff, 0xffff, 0xffff, 0xffff, 0xffff, 0xffff, 0xffff, 0xffff, 0xffff, 0xffff, 0xffff, 0xffff, 0xffff, 0xffff, 0xffff, 0xffff, 0xffff, 0xffff, 0xffff, 0xffff, 0xffff, 0xffff, 0xffff, 0xffff, 0xffff, 0xd39c, 0x0000, 0x718c, 0xffff, 0xffff, 0xffff, 0xffff, 0xffff, 0xbef7, 0xb395, 0xc003, 0xac5c, 0x3bd7, 0xffff, 0xffff, 0x59ce, 0xc318, 0x0000, 0xd39c, 0x9ef7, 0xffff, 0xffff, 0xffff, 0xffff, 0xffff, 0xffff, 0xffff, 0xffff, 0xffff, 0xffff, 0xffff, 0xffff, 0xffff, 0xffff, 0xffff, 0xffff, 0xffff, 0xffff, 0xffff, 0xffff, 0xffff, 0xffff, 0xffff, 0xffff, 0xffff, 0xffff, 0xffff, 0xffff, 0xffff, 0xffff, 0xffff, 0xffff, 0xffff, 0xffff, 0xffff, 0xffff, 0xffff, 0xffff, 0xffff, 0xffff, 0xffff,
		0xffff, 0xffff, 0xffff, 0xffff, 0xffff, 0xffff, 0xffff, 0xffff, 0xffff, 0xffff, 0xffff, 0xffff, 0xffff, 0xffff, 0xffff, 0xffff, 0xffff, 0xffff, 0xffff, 0xffff, 0xffff, 0xffff, 0xffff, 0xffff, 0xffff, 0xffff, 0xffff, 0xffff, 0xffff, 0xffff, 0xffff, 0xffff, 0xffff, 0xffff, 0xffff, 0xbef7, 0x8e73, 0x0000, 0x55ad, 0xffff, 0xffff, 0xffff, 0x3bdf, 0xee6c, 0xa003, 0x9295, 0x9def, 0xffff, 0xbef7, 0xd39c, 0x0000, 0x2000, 0x18c6, 0xdfff, 0xffff, 0xffff, 0xffff, 0xffff, 0xffff, 0xffff, 0xffff, 0xffff, 0xffff, 0xffff, 0xffff, 0xffff, 0xffff, 0xffff, 0xffff, 0xffff, 0xffff, 0xffff, 0xffff, 0xffff, 0xffff, 0xffff, 0xffff, 0xffff, 0xffff, 0xffff, 0xffff, 0xffff, 0xffff, 0xffff, 0xffff, 0xffff, 0xffff, 0xffff, 0xffff, 0xffff, 0xffff, 0xffff, 0xffff, 0xffff, 0xffff, 0xffff,
		0xffff, 0xffff, 0xffff, 0xffff, 0xffff, 0xffff, 0xffff, 0xffff, 0xffff, 0xffff, 0xffff, 0xffff, 0xffff, 0xffff, 0xffff, 0xffff, 0xffff, 0xffff, 0xffff, 0xffff, 0xffff, 0xffff, 0xffff, 0xffff, 0xffff, 0xffff, 0xffff, 0xffff, 0xffff, 0xffff, 0xffff, 0xffff, 0xffff, 0xffff, 0xffff, 0xffff, 0x3ce7, 0x8a52, 0x0000, 0x59ce, 0xffff, 0x77be, 0x2934, 0xc403, 0x36ae, 0xdff7, 0xffff, 0x1ce7, 0x8e73, 0x0000, 0x0c63, 0xbad6, 0xffff, 0xffff, 0xffff, 0xffff, 0xffff, 0xffff, 0xffff, 0xffff, 0xffff, 0xffff, 0xffff, 0xffff, 0xffff, 0xffff, 0xffff, 0xffff, 0xffff, 0xffff, 0xffff, 0xffff, 0xffff, 0xffff, 0xffff, 0xffff, 0xffff, 0xffff, 0xffff, 0xffff, 0xffff, 0xffff, 0xffff, 0xffff, 0xffff, 0xffff, 0xffff, 0xffff, 0xffff, 0xffff, 0xffff, 0xffff, 0xffff, 0xffff, 0xffff, 0xffff,
		0xffff, 0xffff, 0xffff, 0xffff, 0xffff, 0xffff, 0xffff, 0xffff, 0xffff, 0xffff, 0xffff, 0xffff, 0xffff, 0xffff, 0xffff, 0xffff, 0xffff, 0xffff, 0xffff, 0xffff, 0xffff, 0xffff, 0xffff, 0xffff, 0xffff, 0xffff, 0xffff, 0xffff, 0xffff, 0xffff, 0xffff, 0xffff, 0xffff, 0xffff, 0xffff, 0xffff, 0xffff, 0x9ad6, 0x6110, 0xc739, 0x318d, 0xc303, 0x493c, 0xd9ce, 0xffff, 0xffff, 0x38c6, 0xc739, 0x0000, 0x9294, 0x7def, 0xffff, 0xffff, 0xffff, 0xffff, 0xffff, 0xffff, 0xffff, 0xffff, 0xffff, 0xffff, 0xffff, 0xffff, 0xffff, 0xffff, 0xffff, 0xffff, 0xffff, 0xffff, 0xffff, 0xffff, 0xffff, 0xffff, 0xffff, 0xffff, 0xffff, 0xffff, 0xffff, 0xffff, 0xffff, 0xffff, 0xffff, 0xffff, 0xffff, 0xffff, 0xffff, 0xffff, 0xffff, 0xffff, 0xffff, 0xffff, 0xffff, 0xffff, 0xffff, 0xffff, 0xffff,
		0xffff, 0xffff, 0xffff, 0xffff, 0xffff, 0xffff, 0xffff, 0xffff, 0xffff, 0xffff, 0xffff, 0xffff, 0xffff, 0xffff, 0xffff, 0xffff, 0xffff, 0xffff, 0xffff, 0xffff, 0xffff, 0xffff, 0xffff, 0xffff, 0xffff, 0xffff, 0xffff, 0xffff, 0xffff, 0xffff, 0xffff, 0xffff, 0xffff, 0xffff, 0xffff, 0xffff, 0xffff, 0xffff, 0xf7bd, 0x0000, 0x0000, 0xce6c, 0x7ce7, 0xffff, 0xbef7, 0x34a5, 0x0000, 0x4108, 0xb6b5, 0xffff, 0xffff, 0xffff, 0xffff, 0xffff, 0xffff, 0xffff, 0xffff, 0xffff, 0xffff, 0xffff, 0xffff, 0xffff, 0xffff, 0xffff, 0xffff, 0xffff, 0xffff, 0xffff, 0xffff, 0xffff, 0xffff, 0xffff, 0xffff, 0xffff, 0xffff, 0xffff, 0xffff, 0xffff, 0xffff, 0xffff, 0xffff, 0xffff, 0xffff, 0xffff, 0xffff, 0xffff, 0xffff, 0xffff, 0xffff, 0xffff, 0xffff, 0xffff, 0xffff, 0xffff, 0xffff, 0xffff,
		0xffff, 0xffff, 0xffff, 0xffff, 0xffff, 0xffff, 0xffff, 0xffff, 0xffff, 0xffff, 0xffff, 0xffff, 0xffff, 0xffff, 0xffff, 0xffff, 0xffff, 0xffff, 0xffff, 0xffff, 0xffff, 0xffff, 0xffff, 0xffff, 0xffff, 0xffff, 0xffff, 0xffff, 0xffff, 0xffff, 0xffff, 0xffff, 0xffff, 0xffff, 0xffff, 0xffff, 0xffff, 0xffff, 0xffff, 0x14a5, 0x0000, 0x3084, 0xffff, 0x3ce7, 0xcf7b, 0x0000, 0xaa52, 0xbad6, 0xffff, 0xffff, 0xffff, 0xffff, 0xffff, 0xffff, 0xffff, 0xffff, 0xffff, 0xffff, 0xffff, 0xffff, 0xffff, 0xffff, 0xffff, 0xffff, 0xffff, 0xffff, 0xffff, 0xffff, 0xffff, 0xffff, 0xffff, 0xffff, 0xffff, 0xffff, 0xffff, 0xffff, 0xffff, 0xffff, 0xffff, 0xffff, 0xffff, 0xffff, 0xffff, 0xffff, 0xffff, 0xffff, 0xffff, 0xffff, 0xffff, 0xffff, 0xffff, 0xffff, 0xffff, 0xffff, 0xffff, 0xffff,
		0xffff, 0xffff, 0xffff, 0xffff, 0xffff, 0xffff, 0xffff, 0xffff, 0xffff, 0xffff, 0xffff, 0xffff, 0xffff, 0xffff, 0xffff, 0xffff, 0xffff, 0xffff, 0xffff, 0xffff, 0xffff, 0xffff, 0xffff, 0xffff, 0xffff, 0xffff, 0xffff, 0xffff, 0xffff, 0xffff, 0xffff, 0xffff, 0xffff, 0xffff, 0xffff, 0xffff, 0xffff, 0xffff, 0xffff, 0xbef7, 0x1084, 0x0000, 0xd39c, 0x8a52, 0x0000, 0x3084, 0x5def, 0xffff, 0xffff, 0xffff, 0xffff, 0xffff, 0xffff, 0xffff, 0xffff, 0xffff, 0xffff, 0xffff, 0xffff, 0xffff, 0xffff, 0xffff, 0xffff, 0xffff, 0xffff, 0xffff, 0xffff, 0xffff, 0xffff, 0xffff, 0xffff, 0xffff, 0xffff, 0xffff, 0xffff, 0xffff, 0xffff, 0xffff, 0xffff, 0xffff, 0xffff, 0xffff, 0xffff, 0xffff, 0xffff, 0xffff, 0xffff, 0xffff, 0xffff, 0xffff, 0xffff, 0xffff, 0xffff, 0xffff, 0xffff, 0xffff,
		0xffff, 0xffff, 0xffff, 0xffff, 0xffff, 0xffff, 0xffff, 0xffff, 0xffff, 0xffff, 0xffff, 0xffff, 0xffff, 0xffff, 0xffff, 0xffff, 0xffff, 0xffff, 0xffff, 0xffff, 0xffff, 0xffff, 0xffff, 0xffff, 0xffff, 0xffff, 0xffff, 0xffff, 0xffff, 0xffff, 0xffff, 0xffff, 0xffff, 0xffff, 0xffff, 0xffff, 0xffff, 0xffff, 0xffff, 0xffff, 0x5def, 0x8a52, 0x0000, 0x0000, 0x75ad, 0xdfff, 0xffff, 0xffff, 0xffff, 0xffff, 0xffff, 0xffff, 0xffff, 0xffff, 0xffff, 0xffff, 0xffff, 0xffff, 0xffff, 0xffff, 0xffff, 0xffff, 0xffff, 0xffff, 0xffff, 0xffff, 0xffff, 0xffff, 0xffff, 0xffff, 0xffff, 0xffff, 0xffff, 0xffff, 0xffff, 0xffff, 0xffff, 0xffff, 0xffff, 0xffff, 0xffff, 0xffff, 0xffff, 0xffff, 0xffff, 0xffff, 0xffff, 0xffff, 0xffff, 0xffff, 0xffff, 0xffff, 0xffff, 0xffff, 0xffff, 0xffff,
		0xffff, 0xffff, 0xffff, 0xffff, 0xffff, 0xffff, 0xffff, 0xffff, 0xffff, 0xffff, 0xffff, 0xffff, 0xffff, 0xffff, 0xffff, 0xffff, 0xffff, 0xffff, 0xffff, 0xffff, 0xffff, 0xffff, 0xffff, 0xffff, 0xffff, 0xffff, 0xffff, 0xffff, 0xffff, 0xffff, 0xffff, 0xffff, 0xffff, 0xffff, 0xffff, 0xffff, 0xffff, 0xffff, 0xffff, 0xffff, 0xffff, 0xfbde, 0xae73, 0xdbde, 0xffff, 0xffff, 0xffff, 0xffff, 0xffff, 0xffff, 0xffff, 0xffff, 0xffff, 0xffff, 0xffff, 0xffff, 0xffff, 0xffff, 0xffff, 0xffff, 0xffff, 0xffff, 0xffff, 0xffff, 0xffff, 0xffff, 0xffff, 0xffff, 0xffff, 0xffff, 0xffff, 0xffff, 0xffff, 0xffff, 0xffff, 0xffff, 0xffff, 0xffff, 0xffff, 0xffff, 0xffff, 0xffff, 0xffff, 0xffff, 0xffff, 0xffff, 0xffff, 0xffff, 0xffff, 0xffff, 0xffff, 0xffff, 0xffff, 0xffff, 0xffff, 0xffff,
		0xffff, 0xffff, 0xffff, 0xffff, 0xffff, 0xffff, 0xffff, 0xffff, 0xffff, 0xffff, 0xffff, 0xffff, 0xffff, 0xffff, 0xffff, 0xffff, 0xffff, 0xffff, 0xffff, 0xffff, 0xffff, 0xffff, 0xffff, 0xffff, 0xffff, 0xffff, 0xffff, 0xffff, 0xffff, 0xffff, 0xffff, 0xffff, 0xffff, 0xffff, 0xffff, 0xffff, 0xffff, 0xffff, 0xffff, 0xffff, 0xffff, 0xffff, 0xdfff, 0xffff, 0xffff, 0xffff, 0xffff, 0xffff, 0xffff, 0xffff, 0xffff, 0xffff, 0xffff, 0xffff, 0xffff, 0xffff, 0xffff, 0xffff, 0xffff, 0xffff, 0xffff, 0xffff, 0xffff, 0xffff, 0xffff, 0xffff, 0xffff, 0xffff, 0xffff, 0xffff, 0xffff, 0xffff, 0xffff, 0xffff, 0xffff, 0xffff, 0xffff, 0xffff, 0xffff, 0xffff, 0xffff, 0xffff, 0xffff, 0xffff, 0xffff, 0xffff, 0xffff, 0xffff, 0xffff, 0xffff, 0xffff, 0xffff, 0xffff, 0xffff, 0xffff, 0xffff,
		0xffff, 0xffff, 0xffff, 0xffff, 0xffff, 0xffff, 0xffff, 0xffff, 0xffff, 0xffff, 0xffff, 0xffff, 0xffff, 0xffff, 0xffff, 0xffff, 0xffff, 0xffff, 0xffff, 0xffff, 0xffff, 0xffff, 0xffff, 0xffff, 0xffff, 0xffff, 0xffff, 0xffff, 0xffff, 0xffff, 0xffff, 0xffff, 0xffff, 0xffff, 0xffff, 0xffff, 0xffff, 0xffff, 0xffff, 0xffff, 0xffff, 0xffff, 0xffff, 0xffff, 0xffff, 0xffff, 0xffff, 0xffff, 0xffff, 0xffff, 0xffff, 0xffff, 0xffff, 0xffff, 0xffff, 0xffff, 0xffff, 0xffff, 0xffff, 0xffff, 0xffff, 0xffff, 0xffff, 0xffff, 0xffff, 0xffff, 0xffff, 0xffff, 0xffff, 0xffff, 0xffff, 0xffff, 0xffff, 0xffff, 0xffff, 0xffff, 0xffff, 0xffff, 0xffff, 0xffff, 0xffff, 0xffff, 0xffff, 0xffff, 0xffff, 0xffff, 0xffff, 0xffff, 0xffff, 0xffff, 0xffff, 0xffff, 0xffff, 0xffff, 0xffff, 0xffff,
		0xffff, 0xffff, 0xffff, 0xffff, 0xffff, 0xffff, 0xffff, 0xffff, 0xffff, 0xffff, 0xffff, 0xffff, 0xffff, 0xffff, 0xffff, 0xffff, 0xffff, 0xffff, 0xffff, 0xffff, 0xffff, 0xffff, 0xffff, 0xffff, 0xffff, 0xffff, 0xffff, 0xffff, 0xffff, 0xffff, 0xffff, 0xffff, 0xffff, 0xffff, 0xffff, 0xffff, 0xffff, 0xffff, 0xffff, 0xffff, 0xffff, 0xffff, 0xffff, 0xffff, 0xffff, 0xffff, 0xffff, 0xffff, 0xffff, 0xffff, 0xffff, 0xffff, 0xffff, 0xffff, 0xffff, 0xffff, 0xffff, 0xffff, 0xffff, 0xffff, 0xffff, 0xffff, 0xffff, 0xffff, 0xffff, 0xffff, 0xffff, 0xffff, 0xffff, 0xffff, 0xffff, 0xffff, 0xffff, 0xffff, 0xffff, 0xffff, 0xffff, 0xffff, 0xffff, 0xffff, 0xffff, 0xffff, 0xffff, 0xffff, 0xffff, 0xffff, 0xffff, 0xffff, 0xffff, 0xffff, 0xffff, 0xffff, 0xffff, 0xffff, 0xffff, 0xffff,
		0xffff, 0xffff, 0xffff, 0xffff, 0xffff, 0xffff, 0xffff, 0xffff, 0xffff, 0xffff, 0xffff, 0xffff, 0xffff, 0xffff, 0xffff, 0xffff, 0xffff, 0xffff, 0xffff, 0xffff, 0xffff, 0xffff, 0xffff, 0xffff, 0xffff, 0xffff, 0xffff, 0xffff, 0xffff, 0xffff, 0xffff, 0xffff, 0xffff, 0xffff, 0xffff, 0xffff, 0xffff, 0xffff, 0xffff, 0xffff, 0xffff, 0xffff, 0xffff, 0xffff, 0xffff, 0xffff, 0xffff, 0xffff, 0xffff, 0xffff, 0xffff, 0xffff, 0xffff, 0xffff, 0xffff, 0xffff, 0xffff, 0xffff, 0xffff, 0xffff, 0xffff, 0xffff, 0xffff, 0xffff, 0xffff, 0xffff, 0xffff, 0xffff, 0xffff, 0xffff, 0xffff, 0xffff, 0xffff, 0xffff, 0xffff, 0xffff, 0xffff, 0xffff, 0xffff, 0xffff, 0xffff, 0xffff, 0xffff, 0xffff, 0xffff, 0xffff, 0xffff, 0xffff, 0xffff, 0xffff, 0xffff, 0xffff, 0xffff, 0xffff, 0xffff, 0xffff,
		0xffff, 0xffff, 0xffff, 0xffff, 0xffff, 0xffff, 0xffff, 0xffff, 0xffff, 0xffff, 0xffff, 0xffff, 0xffff, 0xffff, 0xffff, 0xffff, 0xffff, 0xffff, 0xffff, 0xffff, 0xffff, 0xffff, 0xffff, 0xffff, 0xffff, 0xffff, 0xffff, 0xffff, 0xffff, 0xffff, 0xffff, 0xffff, 0xffff, 0xffff, 0xffff, 0xffff, 0xffff, 0xffff, 0xffff, 0xffff, 0xffff, 0xffff, 0xffff, 0xffff, 0xffff, 0xffff, 0xffff, 0xffff, 0xffff, 0xffff, 0xffff, 0xffff, 0xffff, 0xffff, 0xffff, 0xffff, 0xffff, 0xffff, 0xffff, 0xffff, 0xffff, 0xffff, 0xffff, 0xffff, 0xffff, 0xffff, 0xffff, 0xffff, 0xffff, 0xffff, 0xffff, 0xffff, 0xffff, 0xffff, 0xffff, 0xffff, 0xffff, 0xffff, 0xffff, 0xffff, 0xffff, 0xffff, 0xffff, 0xffff, 0xffff, 0xffff, 0xffff, 0xffff, 0xffff, 0xffff, 0xffff, 0xffff, 0xffff, 0xffff, 0xffff, 0xffff,
		0xffff, 0xffff, 0xffff, 0xffff, 0xffff, 0xffff, 0xffff, 0xffff, 0xffff, 0xffff, 0xffff, 0xffff, 0xffff, 0xffff, 0xffff, 0xffff, 0xffff, 0xffff, 0xffff, 0xffff, 0xffff, 0xffff, 0xffff, 0xffff, 0xffff, 0xffff, 0xffff, 0xffff, 0xffff, 0xffff, 0xffff, 0xffff, 0xffff, 0xffff, 0xffff, 0xffff, 0xffff, 0xffff, 0xffff, 0xffff, 0xffff, 0xffff, 0xffff, 0xffff, 0xffff, 0xffff, 0xffff, 0xffff, 0xffff, 0xffff, 0xffff, 0xffff, 0xffff, 0xffff, 0xffff, 0xffff, 0xffff, 0xffff, 0xffff, 0xffff, 0xffff, 0xffff, 0xffff, 0xffff, 0xffff, 0xffff, 0xffff, 0xffff, 0xffff, 0xffff, 0xffff, 0xffff, 0xffff, 0xffff, 0xffff, 0xffff, 0xffff, 0xffff, 0xffff, 0xffff, 0xffff, 0xffff, 0xffff, 0xffff, 0xffff, 0xffff, 0xffff, 0xffff, 0xffff, 0xffff, 0xdef7, 0xdef7, 0xffff, 0xffff, 0xffff, 0xffff,
		0x56ae, 0x5185, 0x5185, 0x5185, 0x5185, 0x5185, 0x5185, 0x928d, 0xbeef, 0x77b6, 0x5185, 0x5185, 0x5185, 0x5185, 0x5185, 0x5185, 0xb295, 0x5ce7, 0xffff, 0xffff, 0xffff, 0xb8c6, 0x928d, 0x5185, 0x5185, 0x5185, 0x5185, 0x56b6, 0xffff, 0x3cdf, 0x2f75, 0x5bdf, 0xffff, 0xffff, 0xffff, 0xffff, 0xd9ce, 0x5185, 0x9de7, 0x1ad7, 0x307d, 0x5185, 0x5185, 0x5185, 0x5185, 0x718d, 0x5185, 0x5bdf, 0x1bd7, 0x3085, 0x5bdf, 0xffff, 0xb395, 0x15a6, 0xffff, 0xffff, 0xffff, 0xffff, 0xdef7, 0xd49d, 0x57b6, 0xffff, 0xd9ce, 0x928d, 0xbef7, 0xbef7, 0x507d, 0xb8c6, 0xffff, 0xffff, 0xffff, 0xffff, 0x5ce7, 0x5185, 0xd9ce, 0xffff, 0xf4a5, 0xf4a5, 0xffff, 0xffff, 0xffff, 0xffff, 0xffff, 0x36ae, 0xf4a5, 0xffff, 0xffff, 0x7ce7, 0xb395, 0xee6c, 0xcd64, 0xcd64, 0xef6c, 0xd49d, 0x7de7, 0xffff,
		0xcd5c, 0x493c, 0x507d, 0x507d, 0x507d, 0x507d, 0x507d, 0xb28d, 0x9def, 0x0f7d, 0xe603, 0x507d, 0x507d, 0x507d, 0x507d, 0x507d, 0x0724, 0x7185, 0xffff, 0xffff, 0xf4a5, 0x8003, 0xac5c, 0x507d, 0x507d, 0x507d, 0x493c, 0x0f6d, 0xffff, 0xfad6, 0x8003, 0x8b4c, 0x5ce7, 0xffff, 0xffff, 0xffff, 0x56b6, 0xa003, 0x5bdf, 0x1ad7, 0x2f75, 0x507d, 0x507d, 0x7185, 0xcd5c, 0xa003, 0x2934, 0x5cdf, 0xb8c6, 0x8003, 0xface, 0xbef7, 0x6b4c, 0xa003, 0x15a6, 0xffff, 0xffff, 0xffff, 0xdef7, 0xac5c, 0x928d, 0xffff, 0x57b6, 0x2604, 0xbeef, 0x9def, 0xe503, 0xe503, 0xd9c6, 0xffff, 0xffff, 0xffff, 0x1ad7, 0x8003, 0x77b6, 0xffff, 0xcd64, 0xcd64, 0xffff, 0xffff, 0xffff, 0xffff, 0xffff, 0x507d, 0xee64, 0xffff, 0xbef7, 0xac54, 0x282c, 0x9185, 0xb295, 0xb295, 0x7185, 0x061c, 0xee6c, 0xbef7,
		0xed5c, 0x728d, 0xffff, 0xffff, 0xffff, 0xffff, 0xffff, 0xffff, 0xdff7, 0x0f75, 0xcd64, 0xffff, 0xffff, 0xffff, 0xffff, 0xffff, 0x718d, 0xee64, 0xffff, 0xface, 0xc003, 0xf4a5, 0xdef7, 0xffff, 0xffff, 0xffff, 0x9295, 0x0f6d, 0xffff, 0xfad6, 0xe503, 0x282c, 0x8c54, 0x7ce7, 0xffff, 0xffff, 0x77b6, 0xe403, 0x3bdf, 0xffff, 0xffff, 0xffff, 0xffff, 0xbef7, 0x2f75, 0x282c, 0xfad6, 0xffff, 0xb8c6, 0xa103, 0xface, 0xbef7, 0x8c5c, 0x282c, 0xe403, 0x35ae, 0xffff, 0xffff, 0xdef7, 0xcd64, 0xb28d, 0xffff, 0x77be, 0x482c, 0xbeef, 0x9def, 0x282c, 0x493c, 0x071c, 0xd9ce, 0xffff, 0xffff, 0x1bd7, 0xc403, 0x77b6, 0xffff, 0xee6c, 0xee6c, 0xffff, 0xffff, 0xffff, 0xffff, 0xffff, 0x7185, 0x0f6d, 0xffff, 0x97be, 0xc303, 0xfad6, 0xffff, 0xffff, 0xffff, 0xffff, 0xb8c6, 0x8003, 0x77b6,
		0xed5c, 0x928d, 0x5cdf, 0xd9ce, 0xd9ce, 0xd9ce, 0xd9ce, 0xbef7, 0xffff, 0x0f75, 0xcd64, 0xffff, 0xffff, 0xffff, 0xffff, 0xbef7, 0xce64, 0x0f75, 0xffff, 0x7185, 0x6b4c, 0xbeef, 0xffff, 0xffff, 0xffff, 0xffff, 0x928d, 0x0f6d, 0xffff, 0xfad6, 0x2714, 0xb8be, 0x6b4c, 0xac5c, 0x7ce7, 0xffff, 0x77b6, 0xe403, 0x3bdf, 0xffff, 0xffff, 0xffff, 0xdfff, 0x5185, 0xc303, 0xd9c6, 0xffff, 0xffff, 0xb8c6, 0xa103, 0xface, 0xbef7, 0x6b4c, 0x7185, 0xf49d, 0xc103, 0x56b6, 0xffff, 0xdef7, 0xcd64, 0xb28d, 0xffff, 0x77be, 0x482c, 0xbeef, 0x9def, 0x260c, 0x77b6, 0x5185, 0x0604, 0xface, 0xffff, 0x1bd7, 0xc403, 0x77b6, 0xffff, 0xef74, 0xac54, 0xd9ce, 0xd9ce, 0xd9ce, 0xf9ce, 0xd9ce, 0xee6c, 0x2f75, 0xffff, 0x7185, 0x8b54, 0xbef7, 0xffff, 0xffff, 0xffff, 0xffff, 0x9def, 0x2834, 0xb395,
		0xcd5c, 0xb395, 0xf395, 0xc003, 0xe503, 0xe503, 0xe203, 0x1ad7, 0xffff, 0x0f75, 0xcd64, 0xb8be, 0xf49d, 0x14a6, 0x15a6, 0x0f75, 0xa003, 0x57b6, 0xffff, 0xee6c, 0xcd64, 0x9def, 0xbeef, 0xbdef, 0xbeef, 0xbef7, 0x7185, 0x0f6d, 0xffff, 0xfad6, 0x0404, 0x7de7, 0x3bdf, 0x282c, 0xce64, 0x9def, 0x77be, 0xe403, 0x3bdf, 0xffff, 0xffff, 0xffff, 0xb395, 0xa003, 0x77b6, 0xffff, 0xffff, 0xffff, 0xb8c6, 0xa103, 0xface, 0xbef7, 0x4a4c, 0x9295, 0xffff, 0xb28d, 0xc203, 0x77be, 0xdef7, 0xcd64, 0xb28d, 0xffff, 0x77be, 0x482c, 0xbeef, 0x9def, 0x0504, 0xd9ce, 0xbef7, 0xee6c, 0x2724, 0x3bd7, 0x3bdf, 0xc403, 0x77b6, 0xffff, 0x0f75, 0xe503, 0xe503, 0xe503, 0xe503, 0xe503, 0xe503, 0xe503, 0x307d, 0xffff, 0x7185, 0x8c5c, 0xbef7, 0xffff, 0xffff, 0xffff, 0xffff, 0xbdef, 0x6a3c, 0x928d,
		0xed5c, 0x928d, 0x9def, 0x5ce7, 0x5ce7, 0x5ce7, 0x5ce7, 0xdef7, 0xffff, 0x0f7d, 0xcd64, 0xd49d, 0xe503, 0xa003, 0xc403, 0x8c5c, 0x56b6, 0xffff, 0xffff, 0xef74, 0x071c, 0x6b54, 0x6b54, 0x6b54, 0x6b54, 0x6b54, 0x082c, 0x3075, 0xffff, 0xfad6, 0x0404, 0x7ce7, 0xffff, 0x1ad7, 0x071c, 0x0f75, 0xf49d, 0xe613, 0x3bdf, 0xffff, 0xffff, 0x35ae, 0xa003, 0x35ae, 0xffff, 0xffff, 0xffff, 0xffff, 0xb8c6, 0xa103, 0xface, 0xbef7, 0x6a4c, 0x928d, 0xffff, 0xdef7, 0x928d, 0xc403, 0x56ae, 0xce64, 0xb28d, 0xffff, 0x77be, 0x482c, 0xbeef, 0x9def, 0x0504, 0xb9c6, 0xffff, 0x9def, 0xcd5c, 0x4a44, 0x35a6, 0xe613, 0x77b6, 0xffff, 0xee74, 0xad5c, 0x5cdf, 0x5ce7, 0x5ce7, 0x5ce7, 0x5cdf, 0x0f75, 0x2f75, 0xffff, 0x9185, 0x6b54, 0xbef7, 0xffff, 0xffff, 0xffff, 0xffff, 0x9def, 0x282c, 0xb395,
		0xed5c, 0x728d, 0xffff, 0xffff, 0xffff, 0xffff, 0xffff, 0xffff, 0xdff7, 0x0f75, 0xcd64, 0xbeef, 0x9def, 0x7185, 0xa003, 0xb395, 0xffff, 0xffff, 0xffff, 0xef74, 0x2934, 0x7185, 0x7185, 0x7185, 0x7185, 0x7185, 0x6a4c, 0x2f75, 0xffff, 0xfad6, 0x0404, 0x7ce7, 0xffff, 0xffff, 0xface, 0x0724, 0x071c, 0x282c, 0x3bdf, 0xffff, 0x98be, 0xa003, 0x928d, 0xdef7, 0xdef7, 0xdef7, 0xdef7, 0xffff, 0xb8c6, 0xa103, 0xface, 0xbef7, 0x6a4c, 0x928d, 0xffff, 0xffff, 0xdef7, 0x7185, 0xe503, 0x071c, 0xd395, 0xffff, 0x77be, 0x482c, 0xbeef, 0x9def, 0x0504, 0xb9c6, 0xffff, 0xffff, 0x7ce7, 0xac5c, 0xe503, 0xe503, 0x77b6, 0xffff, 0xee6c, 0xee6c, 0xffff, 0xffff, 0xffff, 0xffff, 0xffff, 0x7185, 0x0f6d, 0xffff, 0x98be, 0xc203, 0xface, 0xffff, 0xffff, 0xffff, 0xffff, 0x98be, 0x8003, 0x77be,
		0xcc54, 0x718d, 0xffff, 0xffff, 0xffff, 0xffff, 0xffff, 0xffff, 0xdff7, 0xef74, 0xcd5c, 0xffff, 0xffff, 0xdef7, 0xd395, 0xc103, 0x728d, 0xbef7, 0xffff, 0xce6c, 0xce6c, 0xffff, 0xffff, 0xffff, 0xffff, 0xffff, 0x728d, 0x0e6d, 0xffff, 0xfad6, 0xe103, 0x5ce7, 0xffff, 0xffff, 0xffff, 0xd9ce, 0x071c, 0x0614, 0x5bdf, 0x1ad7, 0xe403, 0xe613, 0xce6c, 0x0f75, 0xee6c, 0xee6c, 0xcd64, 0x1ad7, 0xb9c6, 0x8003, 0xface, 0xbef7, 0x4a44, 0x728d, 0xffff, 0xffff, 0xffff, 0xbef7, 0x507d, 0x8003, 0xb395, 0xffff, 0x57be, 0x271c, 0xbeef, 0x9def, 0xe303, 0xb9c6, 0xffff, 0xffff, 0xffff, 0x7ce7, 0xac54, 0xa003, 0x77b6, 0xffff, 0xce6c, 0xce6c, 0xffff, 0xffff, 0xffff, 0xffff, 0xffff, 0x5185, 0x0e6d, 0xffff, 0xbef7, 0xcd64, 0xe503, 0x307d, 0x518d, 0x518d, 0x107d, 0xe503, 0x2f75, 0xdef7,
		0x9185, 0xf4a5, 0xffff, 0xffff, 0xffff, 0xffff, 0xffff, 0xffff, 0xffff, 0xb395, 0x9185, 0xffff, 0xffff, 0xffff, 0xdfff, 0x56ae, 0xcc54, 0xf495, 0xdef7, 0x928d, 0x928d, 0xffff, 0xffff, 0xffff, 0xffff, 0xffff, 0x15a6, 0xb28d, 0xffff, 0x3bdf, 0x0d5d, 0x7def, 0xffff, 0xffff, 0xffff, 0xffff, 0xb8c6, 0x0e6d, 0xdef7, 0x3bdf, 0x0e65, 0xee64, 0xed64, 0xed64, 0xed64, 0xed64, 0xac54, 0x1ad7, 0x1ad7, 0xcc54, 0x3bdf, 0xdef7, 0x2f75, 0x15a6, 0xffff, 0xffff, 0xffff, 0xffff, 0xbef7, 0x507d, 0x56b6, 0xffff, 0xb9c6, 0x2f6d, 0xbef7, 0x9eef, 0x0d65, 0xfad6, 0xffff, 0xffff, 0xffff, 0xffff, 0x5cdf, 0xcd5c, 0x3bdf, 0xffff, 0x928d, 0xb28d, 0xffff, 0xffff, 0xffff, 0xffff, 0xffff, 0xf49d, 0xb28d, 0xffff, 0xffff, 0x9def, 0xf49d, 0x4934, 0x2724, 0x2724, 0x693c, 0x15a6, 0x9def, 0xffff
};

// Foto da placa Franzininho Aprenda Soldar
const uint16_t franzininho_as[] =
{
		0xa559, 0xa559, 0xa559, 0xe559, 0x065a, 0x065a, 0xc551, 0x6451, 0x2349, 0x2349, 0x8451, 0x8441, 0xc220, 0x8108, 0x8208, 0x0419, 0xc310, 0xa310, 0xe741, 0x8862, 0x877a, 0x857a, 0x657a, 0x6672, 0x676a, 0x886a, 0xa86a, 0x886a, 0x886a, 0x2762, 0xa551, 0x6451, 0x4351, 0x6451, 0xa559, 0x2662, 0x886a, 0xc972, 0xca72, 0xc649, 0x6100, 0x0411, 0xe410, 0x6100, 0x064a, 0x0a7b, 0xc87a, 0xa782, 0xc88a, 0xe88a, 0x0a9b, 0x2ba3, 0x4a9b, 0x6a9b, 0xaa9b, 0xaa93, 0xab93, 0xab93, 0x8b9b, 0xaba3, 0xaca3, 0xaca3, 0xadab, 0xaca3, 0xcdab, 0xcda3, 0xaca3, 0x8ba3, 0x8ba3, 0x6b9b, 0x6b9b, 0x6b9b, 0x4b93, 0x4b93, 0x6b93, 0x6b93, 0x8c9b, 0xcca3, 0xcdab, 0xedb3, 0x0eb4, 0x2eac, 0x6fb4, 0x90b4, 0xb1b4, 0x90b4, 0x91bc, 0x70c4, 0x50bc, 0x90b4, 0x909c, 0xcc63, 0xe802, 0x0803, 0xe902, 0xe90a,
		0xa559, 0xa559, 0xc559, 0xe659, 0x0662, 0x065a, 0xc551, 0x8451, 0x4349, 0x4351, 0x6351, 0xa449, 0x6439, 0xe218, 0xe318, 0xe418, 0x0419, 0xc408, 0x2421, 0xc549, 0x2562, 0x0472, 0x2472, 0x256a, 0x2662, 0x2662, 0x4762, 0x4762, 0x2762, 0xe659, 0x8451, 0x6349, 0x4349, 0x6451, 0x6451, 0xc551, 0x265a, 0x4762, 0x896a, 0x0752, 0x6110, 0xa208, 0xc308, 0x6108, 0x2331, 0xa86a, 0x8772, 0x877a, 0xa782, 0xc882, 0x2983, 0x498b, 0x498b, 0x898b, 0x898b, 0x898b, 0xaa93, 0x8a8b, 0x4a9b, 0x4ba3, 0x4ba3, 0x4ca3, 0x6ca3, 0x8ca3, 0x8da3, 0xac9b, 0x6c9b, 0x4c9b, 0x6c9b, 0x6c93, 0x8c8b, 0x8c83, 0x6c73, 0x6c73, 0x8b63, 0xaa5b, 0xaa5b, 0xcb73, 0x0c94, 0xeda3, 0xcdab, 0x2eac, 0x4fac, 0x70b4, 0x90b4, 0x70b4, 0x70bc, 0x70bc, 0x50bc, 0x6fac, 0x6f94, 0x4b4b, 0xe802, 0x2903, 0xea02, 0xca02,
		0xa559, 0xa559, 0xc559, 0xe559, 0xe659, 0xe659, 0xa559, 0x8451, 0x6451, 0x2249, 0x4351, 0x8449, 0x8449, 0x6439, 0xa218, 0x8208, 0xa308, 0x0511, 0x8200, 0xe220, 0xa449, 0xe459, 0xc461, 0xc461, 0xc559, 0xc559, 0xe559, 0xe559, 0xc551, 0xa451, 0x6449, 0x4349, 0x4349, 0x4349, 0x4451, 0xa551, 0xe551, 0x065a, 0x2762, 0xe751, 0xa218, 0x6100, 0x6100, 0x6108, 0x8118, 0x0652, 0x4662, 0x666a, 0x6672, 0x877a, 0xe77a, 0x0783, 0x0783, 0x288b, 0x4893, 0x2893, 0x4993, 0x4a9b, 0x4b9b, 0x4b93, 0x2b93, 0x4b93, 0x6c93, 0x8c93, 0xac83, 0xcd83, 0xcd7b, 0xcd73, 0xac6b, 0xcc5b, 0xec4b, 0x2c44, 0x4c34, 0x6d2c, 0xac2c, 0xec2c, 0xab24, 0x0934, 0xeb63, 0x0d94, 0xcda3, 0x0dac, 0x2eac, 0x4fb4, 0x70b4, 0x70ac, 0x50b4, 0x50bc, 0x70b4, 0x8fa4, 0x6f84, 0x4b43, 0xc802, 0x0903, 0xca0a, 0xeb0a,
		0xa561, 0xc561, 0xc561, 0xc559, 0xc559, 0xa551, 0x8451, 0x6451, 0x4451, 0x0249, 0x0249, 0x2349, 0x4349, 0x8449, 0x2431, 0x6110, 0xa210, 0xc310, 0xc310, 0xe318, 0x4431, 0xa541, 0xa449, 0x8449, 0x8351, 0x8451, 0x8349, 0x6349, 0x6349, 0x4349, 0x4341, 0x2341, 0x2341, 0x2349, 0x4449, 0x8449, 0xa549, 0xc551, 0xc659, 0xe651, 0xe328, 0x8108, 0x6100, 0x8210, 0x2008, 0x6439, 0x065a, 0x2662, 0x456a, 0x6672, 0xa67a, 0xe782, 0xe782, 0xe78a, 0x088b, 0xe882, 0x098b, 0x4a8b, 0x6b7b, 0x8b7b, 0x6b73, 0x4a73, 0x8b6b, 0xac63, 0xec53, 0x2c4c, 0x8d44, 0xcd34, 0xcd2c, 0x2e2d, 0x8f2d, 0xaf25, 0xce1d, 0xce15, 0xad1d, 0x8c1d, 0xad1d, 0x0b15, 0x0a34, 0x0c7c, 0x0da4, 0xecab, 0x2dac, 0x4fac, 0x4fac, 0x4fac, 0x2fac, 0x4fb4, 0x4fa4, 0x8f94, 0x2d6c, 0xcc43, 0xca2b, 0x6813, 0xc80a, 0xca02,
		0xa561, 0xc661, 0xc661, 0xc559, 0xc559, 0xa551, 0x6451, 0x6451, 0x2351, 0x0349, 0xe248, 0xe248, 0x0249, 0x2349, 0x6441, 0xe328, 0x0008, 0xa210, 0xe210, 0xe310, 0xc308, 0x2521, 0x2429, 0x4441, 0x4349, 0x4249, 0x2249, 0x2241, 0x2241, 0x2241, 0x2241, 0x2341, 0x2341, 0x0341, 0x0349, 0x4341, 0x4341, 0x6449, 0x6449, 0x6549, 0xc220, 0x4000, 0x4100, 0x4108, 0x0000, 0x0329, 0xe551, 0x055a, 0x0462, 0x256a, 0x666a, 0xa76a, 0xc76a, 0xc76a, 0xe862, 0x8b6b, 0xac63, 0x8b53, 0x2d5c, 0x6e5c, 0x8e5c, 0x306d, 0xd26d, 0xf265, 0x124e, 0x1146, 0x103e, 0xef35, 0xae25, 0x8d1d, 0x8c15, 0x8c0d, 0xac0d, 0xab05, 0xac15, 0x6c0d, 0xac05, 0x8c0d, 0x8b1c, 0x0b64, 0x0c94, 0x0ca4, 0x0da4, 0x2fac, 0x2fac, 0x2fac, 0x0eac, 0x2fa4, 0x4e94, 0x4d7c, 0x694b, 0x8933, 0x6a34, 0x082c, 0x6823, 0x090b,
		0x8559, 0xa551, 0xa551, 0xa551, 0x8549, 0x6449, 0x4449, 0x2341, 0xe340, 0x0241, 0xe240, 0xc138, 0xe138, 0x2239, 0x6331, 0x6329, 0x2219, 0x6008, 0x4008, 0xa310, 0xc410, 0xe418, 0xe420, 0x0329, 0x6439, 0x4339, 0x4231, 0x2231, 0x2331, 0x2331, 0xe230, 0xe338, 0xe338, 0xe338, 0x0339, 0x0239, 0x2239, 0x2341, 0x2341, 0x2441, 0xa120, 0x2008, 0x4000, 0x4000, 0x2000, 0xc218, 0x8541, 0xa549, 0xe551, 0x2652, 0xa74a, 0x084b, 0x4943, 0xaa3b, 0x2c3c, 0xef4c, 0x9155, 0x135e, 0x7466, 0x946e, 0x5366, 0x115e, 0xf04d, 0xcf35, 0xae1d, 0xad05, 0x8d05, 0x6c05, 0x6c0d, 0x6c0d, 0x8c15, 0x8b15, 0x8b0d, 0xaa15, 0xab0d, 0xac0d, 0xac05, 0x8c05, 0xec1c, 0x0b54, 0xec8b, 0xcca3, 0xcda3, 0xefab, 0x0ea4, 0x2ea4, 0x0da4, 0x0da4, 0x0e94, 0xcc63, 0xc822, 0xc812, 0x681b, 0x082c, 0x293c, 0xc833,
		0x0339, 0x2331, 0x4429, 0x4431, 0x2329, 0x2329, 0x2329, 0x0329, 0xe228, 0xc549, 0x465a, 0xe541, 0x0542, 0xa74a, 0x295b, 0xe74a, 0x8532, 0x6319, 0x4100, 0x6108, 0x6208, 0xc318, 0xe418, 0xc308, 0xc621, 0x472a, 0x6722, 0x461a, 0x261a, 0x261a, 0x061a, 0xc521, 0xa521, 0xa521, 0x8421, 0x6329, 0x4329, 0x2231, 0x0331, 0x2439, 0xa220, 0x0010, 0x2008, 0x2000, 0x4000, 0x2311, 0x4732, 0x093b, 0xab33, 0x2c2c, 0x8d2c, 0xee2c, 0x5035, 0xd135, 0x1136, 0xf02d, 0x1036, 0xd035, 0xaf1d, 0x6e0d, 0x4c05, 0x4c05, 0x6b0d, 0x8b0d, 0xab0d, 0xac05, 0xac05, 0xad0d, 0x8d0d, 0x6c0d, 0x6d0d, 0x6c0d, 0xac0d, 0x8b05, 0xec05, 0xcd05, 0x8d0d, 0x8d0d, 0x2c15, 0x0b44, 0xcc83, 0x8c9b, 0xada3, 0xaea3, 0x0e9c, 0x0c9c, 0xec9b, 0xcc9b, 0xad83, 0xea3a, 0xc90a, 0xca02, 0xe90a, 0xe50a, 0xc633, 0xa854,
		0xa130, 0xa128, 0xa128, 0xa120, 0xa020, 0xc118, 0xc118, 0xc118, 0xc110, 0x0119, 0x4229, 0x0121, 0x0121, 0x6329, 0xe539, 0xa329, 0x4221, 0x2311, 0xc100, 0x8100, 0x6100, 0xa208, 0xc308, 0x0411, 0xe300, 0xa509, 0x6812, 0x8812, 0x880a, 0xc802, 0xc802, 0x0903, 0x2903, 0x0913, 0xc922, 0x8822, 0x461a, 0x0512, 0xa419, 0x6419, 0xc310, 0x0000, 0x0008, 0x0000, 0x0000, 0xc409, 0x6c34, 0x6e25, 0xce1d, 0x0f16, 0xcf1d, 0xae1d, 0xae15, 0xae0d, 0x8d05, 0x8d05, 0x6c05, 0x8d05, 0x8d15, 0x6d15, 0x6c15, 0x6b0d, 0x8b15, 0x8c15, 0x8c15, 0x8c0d, 0xab0d, 0x8b0d, 0x6b0d, 0xce1d, 0x6e15, 0x4e15, 0xb43e, 0x5336, 0x8e0d, 0xad0d, 0x8d15, 0xad0d, 0x6d05, 0x4b2c, 0xec6b, 0x8b8b, 0xcc8b, 0xec8b, 0xec93, 0xac9b, 0x6c93, 0x4c7b, 0x0b53, 0xa912, 0xe902, 0xe702, 0x060b, 0x8723, 0x6944, 0xca54,
		0xc559, 0xc669, 0xa669, 0xa661, 0xa561, 0x4451, 0xe240, 0x0341, 0xe240, 0x2231, 0x0121, 0x0129, 0xe128, 0x8020, 0x2018, 0x2020, 0x6120, 0xa118, 0xc210, 0xc210, 0x6108, 0x8208, 0x8208, 0xc308, 0x8200, 0x8200, 0xa300, 0x2401, 0xc601, 0x4702, 0xc902, 0x4a0b, 0x4a03, 0x4a03, 0x2a0b, 0x6a03, 0x8a03, 0xca13, 0x4913, 0xe501, 0xc200, 0x4100, 0x2000, 0x0008, 0x0008, 0xa309, 0x8b1c, 0xad0d, 0xcc05, 0xcc05, 0xcd05, 0xac05, 0x8c05, 0xad0d, 0x8c0d, 0x8c0d, 0x8c0d, 0x8c0d, 0x6c0d, 0x6c0d, 0x8c0d, 0x8b0d, 0xac0d, 0xac0d, 0x8d0d, 0x8d15, 0xac0d, 0x6a05, 0x0e26, 0x923e, 0x3336, 0x343e, 0x7a5f, 0xf84e, 0x6f15, 0x6d15, 0x6d15, 0xad05, 0xad05, 0xab1c, 0xeb5b, 0x6b7b, 0x8a7b, 0xeb83, 0x8b8b, 0x2c93, 0x2c7b, 0xea52, 0xa81a, 0xc802, 0x0703, 0xa723, 0x6a3c, 0xcb4c, 0x4a3c, 0xa82b,
		0x4b8b, 0x8c93, 0xad9b, 0xad9b, 0xad9b, 0x4c93, 0x897a, 0xe669, 0x6459, 0x6351, 0x6351, 0x8451, 0xe659, 0xc659, 0x8549, 0x4541, 0x0439, 0xe438, 0xc330, 0x8220, 0x4110, 0x6210, 0x2100, 0x4100, 0xa300, 0xe200, 0x4301, 0xe509, 0x670a, 0x8602, 0x2803, 0xaa0b, 0xeb13, 0x4c14, 0xae14, 0xee14, 0x2e15, 0x4e1d, 0x8c1c, 0xa60a, 0xc100, 0x6000, 0x6100, 0x2008, 0x0010, 0x2209, 0xe91b, 0x4c1d, 0x4b15, 0x4b1d, 0x8c0d, 0x8c05, 0x8c15, 0x6c15, 0x6c1d, 0x6c15, 0x6c0d, 0x6c0d, 0x8b0d, 0x6b0d, 0x8c05, 0x8c05, 0xac05, 0xad0d, 0x8d0d, 0x8d0d, 0x6d05, 0xf025, 0x5236, 0x701d, 0xf335, 0x395f, 0xb74e, 0x9225, 0x4f0d, 0x8d15, 0x6d15, 0xae0d, 0xce05, 0xec1c, 0xca53, 0x0a7b, 0x0983, 0x6a83, 0x0a83, 0xea7a, 0xe952, 0x0723, 0x260b, 0x872b, 0x0944, 0xaa4c, 0x8b44, 0xc92b, 0x0813, 0xc802,
		0x6fac, 0xaf9c, 0xd09c, 0xb09c, 0xb0a4, 0x8fa4, 0x0e9c, 0x6c8b, 0xc97a, 0xe671, 0xa569, 0xc669, 0x276a, 0xea72, 0x4c73, 0x8c6b, 0x2b5b, 0xa952, 0x2642, 0x8421, 0xa419, 0xc409, 0x0402, 0x6502, 0xe70a, 0x4703, 0xa803, 0x290c, 0x8a0c, 0xcb0c, 0x0c15, 0x2c15, 0x4d1d, 0x4d1d, 0x2d15, 0x4d0d, 0x4c05, 0x4c0d, 0xcb1c, 0x0713, 0x2201, 0x4000, 0x6000, 0x2008, 0x0008, 0xa000, 0x060b, 0xeb14, 0x4b15, 0x4c1d, 0x6c0d, 0x6c0d, 0x6c15, 0x6c15, 0x6c15, 0x6c0d, 0x8c0d, 0x8c05, 0x6b0d, 0x8c15, 0x6c0d, 0x8d0d, 0x4c05, 0xae15, 0x8e0d, 0x8e05, 0x9015, 0xd746, 0x3436, 0x110d, 0x5546, 0x595f, 0x9546, 0x701d, 0x8e0d, 0xad0d, 0x4d15, 0x8d0d, 0x8d05, 0xec24, 0x8a53, 0xa97a, 0x6882, 0xa97a, 0xc972, 0x8752, 0xa522, 0x8613, 0x6834, 0xa954, 0x695c, 0xc933, 0x2713, 0xc802, 0x0a0b, 0xeb0a,
		0xd1bc, 0xf1b4, 0xf1ac, 0xd1ac, 0xf1b4, 0xf1b4, 0xb0ac, 0xb0ac, 0x4f9c, 0xac8b, 0xc96a, 0xa75a, 0x8752, 0xc84a, 0x8a53, 0xec53, 0xaa4b, 0x693b, 0x2723, 0x2713, 0xa813, 0x090c, 0x690c, 0xaa0c, 0xca0c, 0xea0c, 0x2b0d, 0x4b0d, 0x4b0d, 0x4b0d, 0x2b05, 0x4b0d, 0x4b0d, 0x4b0d, 0x2b0d, 0x4b05, 0x4b05, 0x2b0d, 0x8a1c, 0xe612, 0x0101, 0x2000, 0x2000, 0x2000, 0x0000, 0xc000, 0x6402, 0x6a04, 0x8c05, 0x8c05, 0x6c0d, 0x8d15, 0x8c0d, 0x8d0d, 0xad0d, 0x8d0d, 0x2c05, 0x4c05, 0x6d1d, 0x6d1d, 0x8b0c, 0x4b14, 0x8c14, 0xcd14, 0x8f1d, 0x8e0d, 0xb646, 0xf52d, 0x5746, 0xb84e, 0xb84e, 0x9646, 0xf22d, 0x7336, 0xcf0d, 0x8d05, 0x4d15, 0x6e15, 0xae05, 0x2d1d, 0xca43, 0xa862, 0x676a, 0x8762, 0x864a, 0x0633, 0x0834, 0xeb44, 0xca44, 0x0844, 0x2633, 0x0913, 0xe90a, 0xea0a, 0xea02, 0xeb02,
		0xd1c4, 0xf2c4, 0xf2bc, 0x12bd, 0x32b5, 0x32ad, 0x32a5, 0x1195, 0x8f84, 0x2c6c, 0x6843, 0x072b, 0x061b, 0x461b, 0x870b, 0xc703, 0x0804, 0x290c, 0x6a14, 0xcb14, 0xeb14, 0xea0c, 0x0a0d, 0x2a0d, 0x090d, 0x0a0d, 0x0b0d, 0x0b0d, 0x2b0d, 0x4b0d, 0x4b0d, 0x2b0d, 0x2b0d, 0x4b0d, 0x6b0d, 0x4b05, 0x4b0d, 0x0b15, 0x4a1c, 0xa712, 0xc100, 0x0100, 0x0008, 0x2000, 0x4000, 0xc100, 0xa301, 0xa913, 0x4d15, 0x8d05, 0x4d1d, 0x4d15, 0x2c05, 0x6d0d, 0x6e1d, 0x6b0c, 0x6803, 0x690b, 0x2a04, 0x6c1c, 0x490b, 0x8f4c, 0xb044, 0x2903, 0xee1c, 0xd025, 0xb53e, 0x553e, 0x7646, 0x9746, 0x3636, 0x152e, 0x921d, 0x131e, 0xb326, 0x8d05, 0x2e1d, 0x4e15, 0xae05, 0x6d15, 0x2a2c, 0x073b, 0xa63a, 0xc63a, 0xa73b, 0x8a44, 0xaa4c, 0x093c, 0x071b, 0x080b, 0x0a03, 0x0b13, 0x2b13, 0x0a03, 0x2a03, 0x2a03,
		0xf2c4, 0x13c5, 0x13bd, 0x73b5, 0x5295, 0x6d6c, 0xaa43, 0x8823, 0x8703, 0xe803, 0x080c, 0x2814, 0x6814, 0xa914, 0xa914, 0xc90c, 0xc90c, 0xea0c, 0xca0c, 0xea0c, 0xca0c, 0xe90c, 0xe914, 0xc914, 0xc914, 0xe914, 0xea0c, 0xea0c, 0x2b0d, 0x4b0d, 0x4b05, 0x4b05, 0x2b0d, 0x4b0d, 0x4c05, 0x4b05, 0x4b05, 0x0b15, 0x2a14, 0x660a, 0x8200, 0x2100, 0x2000, 0x4000, 0x4000, 0xc208, 0x6311, 0x4923, 0xad24, 0x0e15, 0x6c14, 0xce3c, 0x1366, 0x6b1c, 0x4b14, 0x8913, 0xf58d, 0xf9b6, 0x6e54, 0x0803, 0xc90a, 0x9164, 0x5485, 0x6b33, 0x4c14, 0x6e1d, 0xf22d, 0x753e, 0x7646, 0x7746, 0x563e, 0xf94e, 0x352e, 0x5526, 0x1216, 0x6c05, 0x4d15, 0x6d15, 0xae05, 0x8e05, 0x8b14, 0x8623, 0xa743, 0x8a4c, 0xcb4c, 0x2934, 0x4723, 0xa81a, 0xca12, 0xeb02, 0x2c03, 0x0b03, 0x0a03, 0x4a0b, 0x4903, 0x2903,
		0x12c5, 0x53c5, 0x53c5, 0x119d, 0xca43, 0xc703, 0x291c, 0x691c, 0xc90c, 0xe90c, 0xc90c, 0xc90c, 0xc90c, 0xc90c, 0xc90c, 0xc90c, 0xe90c, 0xe90c, 0xe90c, 0xc90c, 0xc90c, 0xc90c, 0xca14, 0xca14, 0xca14, 0xe90c, 0x0905, 0x2a0d, 0x0a0d, 0x4b0d, 0x4b05, 0x2a05, 0x2a15, 0x0b15, 0x2d15, 0x4b0d, 0x6a05, 0x2a05, 0x4a0c, 0xc80a, 0xc200, 0x0000, 0x8100, 0x2000, 0x8218, 0x4419, 0xe501, 0xaf3c, 0x1977, 0xb766, 0x0d0c, 0xf68d, 0xfed7, 0x7375, 0xe602, 0x081b, 0xb8ae, 0xfedf, 0x958d, 0xa902, 0xa802, 0x3064, 0x79c6, 0xfabe, 0x0f35, 0x4e0d, 0x4e0d, 0xd22d, 0x3536, 0x563e, 0xb84e, 0x563e, 0x753e, 0xf225, 0x4f15, 0x4e15, 0xcc05, 0xcc05, 0x8e05, 0x7005, 0xac04, 0xca4c, 0xe96c, 0x684c, 0x662b, 0xe80a, 0xca02, 0xec0a, 0xec0a, 0x0b0b, 0x0a03, 0x2a03, 0x2a03, 0x2a03, 0x2a0b, 0x2a13,
		0x33c5, 0x53bd, 0x73bd, 0x2d74, 0xa703, 0xa914, 0x8914, 0x8914, 0xc904, 0xe904, 0xc90c, 0xc90c, 0xc90c, 0xc90c, 0xc90c, 0xc90c, 0xe90c, 0xc90c, 0xc90c, 0xc90c, 0xc90c, 0xe90c, 0xea0c, 0x0a05, 0x0a05, 0x0a05, 0xe904, 0x0a0d, 0xea0c, 0x2c15, 0x0b05, 0x4c15, 0x0b15, 0xcb1c, 0x6b0c, 0xec14, 0x0b15, 0xec0c, 0x8e1c, 0x8c1b, 0xa91a, 0xa511, 0x0000, 0x0411, 0x8932, 0xa81a, 0x4a03, 0x7766, 0xdd97, 0x7d97, 0x7455, 0xb585, 0x5ccf, 0xf68d, 0x2913, 0x4712, 0xb17c, 0x79b6, 0x137d, 0xe912, 0xc802, 0x6b43, 0x507c, 0xd174, 0x2b1c, 0x2d0d, 0x8f0d, 0x6f05, 0xf225, 0xb63e, 0xb746, 0x7636, 0x132e, 0x4f05, 0x2f05, 0x4f0d, 0x8e05, 0x4d05, 0x301d, 0x9435, 0xd33d, 0xec44, 0xea54, 0x0734, 0x050b, 0xe702, 0x090b, 0xea02, 0xeb02, 0xea0a, 0xea0a, 0xea0a, 0xea0a, 0xea0a, 0xea0a, 0xea0a,
		0x73c5, 0x93bd, 0x52ad, 0x694b, 0x490c, 0xc904, 0xc904, 0x8804, 0xc904, 0xe904, 0xc90c, 0xc90c, 0xc90c, 0xc90c, 0xc90c, 0xc90c, 0xc90c, 0xc90c, 0xc90c, 0xc90c, 0xe90c, 0xea04, 0xea04, 0x0b05, 0x0b05, 0x0b0d, 0xca0c, 0xcb1c, 0x8b14, 0x4a04, 0xcb0c, 0x0c1d, 0x4a14, 0x6703, 0xca2b, 0xc913, 0x6c24, 0xf455, 0x1a7f, 0x9976, 0x2e2c, 0x2e4c, 0x548d, 0xd274, 0xac2b, 0x8a03, 0x6d04, 0x5656, 0xbe97, 0x7d9f, 0x9455, 0xad33, 0x137d, 0xb57d, 0x0913, 0x270a, 0xaa32, 0xaf5b, 0x6c43, 0x291b, 0xc702, 0x4612, 0xc509, 0xe301, 0x8803, 0x2e1d, 0x8e0d, 0x8f05, 0x4f05, 0xb21d, 0xb746, 0xf42d, 0x3005, 0x711d, 0xb32d, 0xb41d, 0x132e, 0x3446, 0x3766, 0xfb6e, 0x9756, 0x5045, 0xa62b, 0x493c, 0x2a34, 0x681b, 0xe702, 0xe802, 0xea0a, 0xea0a, 0xeb12, 0xcb12, 0xca0a, 0xca0a, 0xea02, 0xea02,
		0x74c5, 0x73bd, 0x72b5, 0xca5b, 0x2804, 0xe904, 0xc904, 0x880c, 0xa804, 0xc90c, 0xc90c, 0xc90c, 0xc90c, 0xc90c, 0xc90c, 0xc90c, 0xc90c, 0xe90c, 0xe90c, 0xe90c, 0xe90c, 0xca0c, 0xaa14, 0x8a0c, 0x4a04, 0x2a14, 0x0914, 0x2603, 0x070b, 0x6d3c, 0xca23, 0xea1b, 0x0703, 0xb375, 0x9baf, 0x3165, 0x6b13, 0xda86, 0x9e8f, 0x5c7f, 0x523d, 0xeb13, 0x0d3c, 0x0c24, 0x6c0c, 0x0e0d, 0x0e05, 0x7225, 0x3a6f, 0xd65d, 0x6e24, 0x0e44, 0x8d53, 0x8c43, 0xc91a, 0x471a, 0x2832, 0x282a, 0x681a, 0x6a1b, 0x4913, 0xe501, 0x8401, 0x0502, 0xeb0b, 0x3025, 0x4f15, 0x6f05, 0x911d, 0x3536, 0x7746, 0x774e, 0x974e, 0x9756, 0x5b6f, 0xfa5e, 0x7a5f, 0x3967, 0xd966, 0xf966, 0x7656, 0x0f45, 0xcb4b, 0x8a53, 0x0b5c, 0x2b54, 0x893b, 0xe81a, 0xc80a, 0xaa0a, 0xca0a, 0xea0a, 0xea0a, 0x0a03, 0x0a03, 0xe902,
		0x74c5, 0x53c5, 0x73bd, 0xcb63, 0xe703, 0xc904, 0xa80c, 0x8914, 0xa90c, 0xc90c, 0xa90c, 0xa90c, 0xa90c, 0xa90c, 0xc90c, 0xc90c, 0xc90c, 0xe904, 0xe904, 0xe904, 0xca0c, 0x8a14, 0x8703, 0x8923, 0xec3b, 0x6502, 0x8502, 0x2402, 0xed4b, 0x9796, 0x8f54, 0x4602, 0x8712, 0xd485, 0x789e, 0x905c, 0xc902, 0x3876, 0x9e8f, 0x7c7f, 0x3125, 0x6b04, 0xab04, 0x0c05, 0x6e15, 0x6e15, 0x0e0d, 0x912d, 0x395f, 0x511d, 0x2c04, 0x8f64, 0xd595, 0xd485, 0x6e4c, 0xc822, 0x4622, 0xe519, 0x4602, 0xab13, 0x8e24, 0xee33, 0xce43, 0x2e34, 0x312d, 0x3656, 0xb85e, 0xb756, 0xb856, 0xd956, 0x1a67, 0xf95e, 0x1b6f, 0xfa66, 0xd96e, 0xf54d, 0x343e, 0x122e, 0x701d, 0x701d, 0x2f1d, 0x2c3c, 0xf18c, 0xb1a4, 0xb09c, 0xf09c, 0xcf8c, 0x2d6c, 0x6b4b, 0x0a2b, 0xa90a, 0xc902, 0x0903, 0x0903, 0x0903, 0x4a0b,
		0x73c5, 0x53c5, 0x52bd, 0xcb6b, 0x8603, 0x880c, 0x8814, 0x6814, 0xa80c, 0xa80c, 0xa90c, 0xa90c, 0xa90c, 0xa90c, 0xa90c, 0xc90c, 0xc90c, 0xe904, 0xe904, 0xc904, 0xaa14, 0x2914, 0x4202, 0x4e5c, 0xd9b6, 0x6f6c, 0xe301, 0x261a, 0x6c4b, 0xd695, 0x9164, 0x8812, 0x050a, 0x4b43, 0xce53, 0xcd43, 0x0913, 0x4f2c, 0x9445, 0xf95e, 0xf33d, 0x0d05, 0x6c05, 0x6c05, 0x8d05, 0x6e15, 0xee14, 0xf33d, 0x1857, 0x5005, 0x0e05, 0xeb13, 0x726d, 0x7676, 0x8d24, 0xad24, 0x6b24, 0xc803, 0xea0b, 0xce1c, 0x502d, 0x3987, 0x3a97, 0x9766, 0xd866, 0xfa76, 0x1a7f, 0x1a77, 0x575e, 0x975e, 0x975e, 0x364e, 0xb33d, 0xf124, 0x1035, 0xce2c, 0x2d05, 0x4d05, 0x6d0d, 0x6d05, 0x2d15, 0x0b34, 0xd194, 0xd2bc, 0xd2bc, 0x12bd, 0x12b5, 0x12a5, 0x129d, 0xd18c, 0x2f6c, 0x8b3b, 0xe91a, 0xe80a, 0x6a13, 0x6b13,
		0x73bd, 0x73bd, 0x52bd, 0x2c7c, 0x4503, 0x6814, 0x6814, 0x6814, 0xc804, 0xa804, 0xa80c, 0xa80c, 0xa80c, 0xa80c, 0xa80c, 0xa90c, 0xa90c, 0xc90c, 0xc90c, 0xc90c, 0xaa14, 0x0914, 0x4302, 0x4e5c, 0x5bc7, 0x98ae, 0x4a3b, 0xa409, 0x8932, 0x5064, 0x126d, 0x0923, 0x0502, 0xa92a, 0xcb32, 0xe922, 0x281b, 0xeb0b, 0x8d04, 0xd33d, 0x185f, 0x2f1d, 0x2d0d, 0x6d05, 0x6d05, 0x2d05, 0xce0c, 0x154e, 0x9856, 0x3205, 0x921d, 0x5345, 0x755d, 0xd54d, 0x3005, 0x0e05, 0x0d05, 0x4c05, 0x2c15, 0x4d15, 0x6e1d, 0xd66e, 0x3466, 0x7556, 0x7656, 0xb455, 0x9044, 0xb03c, 0x8e24, 0x0f25, 0xee14, 0xed0c, 0x0d0d, 0x0d15, 0xec14, 0x2c15, 0x6c05, 0x6c0d, 0x2b0d, 0x2b0d, 0x0c0d, 0x2c1c, 0x128d, 0x53bd, 0x33bd, 0x13c5, 0x14c5, 0x13c5, 0x13bd, 0x12bd, 0x32b5, 0xf2a4, 0x4f84, 0xac53, 0x0923, 0xe90a,
		0x53b5, 0x52b5, 0x11ad, 0x8d84, 0x040b, 0x4814, 0x6814, 0x880c, 0xc804, 0xa804, 0xa80c, 0xa80c, 0xa80c, 0xa80c, 0xa80c, 0xa80c, 0xa80c, 0xa90c, 0xa90c, 0xa90c, 0xaa14, 0x6a1c, 0x680b, 0xab33, 0x737d, 0xb485, 0x4a3b, 0xa401, 0x472a, 0x0a33, 0x8c3b, 0x0923, 0x2502, 0xa922, 0xab2a, 0x4a2b, 0x891b, 0x4a14, 0xac0c, 0xad04, 0x9656, 0x144e, 0x8d04, 0xcd04, 0x0e05, 0x5025, 0x933d, 0x996e, 0x1c7f, 0xfc76, 0x5d87, 0x5eaf, 0x3fbf, 0x9eaf, 0xda7e, 0xf565, 0xb35d, 0x4f2d, 0xeb04, 0x2b05, 0x2b0d, 0x4d25, 0xac1c, 0x0d1d, 0x7035, 0x8b23, 0x6b2b, 0xcc2b, 0xaa13, 0xcc1c, 0xeb0c, 0x0b05, 0x2b05, 0x2b0d, 0x0b05, 0x4b05, 0x4b05, 0x0b0d, 0xca14, 0xea0c, 0x4d1d, 0xae14, 0x1275, 0xb3b5, 0x73bd, 0x54c5, 0x55cd, 0x14cd, 0x14d5, 0x13d5, 0x32cd, 0x13cd, 0x12bd, 0xd19c, 0x0e6c, 0x0a33,
		0x32bd, 0x11b5, 0x11b5, 0xaf94, 0x062b, 0x0814, 0x880c, 0x880c, 0x6714, 0xa80c, 0xa80c, 0xa80c, 0xa80c, 0xa80c, 0xa80c, 0xa80c, 0xa80c, 0xa804, 0xa804, 0xa804, 0xa90c, 0x6914, 0x8813, 0x450a, 0x6722, 0x0933, 0xa722, 0xe409, 0xe411, 0x4722, 0xa82a, 0xc922, 0x0913, 0x4a1b, 0xc91a, 0xc81a, 0xa502, 0xe903, 0x8c0c, 0xce0c, 0xd445, 0xf96e, 0x376e, 0x586e, 0x9976, 0xfb7e, 0x5d8f, 0x7e97, 0x7e9f, 0x7e9f, 0xbf97, 0x7faf, 0x1ebf, 0x5ebf, 0x5dbf, 0xfbbe, 0xbaae, 0x978e, 0x7045, 0xca0c, 0xea0c, 0xa804, 0xe90c, 0x0b05, 0xa903, 0x0822, 0x2d43, 0x4f54, 0xab2b, 0x6b1c, 0x2b1d, 0xe904, 0xeb0c, 0x290c, 0x0804, 0x6904, 0xea0c, 0xea04, 0xe904, 0xe90c, 0x2d25, 0xef24, 0xb064, 0x73bd, 0x53c5, 0x53c5, 0x94bd, 0x54cd, 0x14dd, 0x34d5, 0x74c5, 0x33cd, 0x33c5, 0x12bd, 0xf1ac, 0x2f84,
		0xf1b4, 0xd0b4, 0xd0b4, 0xd09c, 0x283b, 0xa703, 0x880c, 0x880c, 0x6714, 0x880c, 0xa80c, 0xa80c, 0xa80c, 0xa80c, 0xa80c, 0xa80c, 0xa80c, 0xa804, 0xa804, 0xa804, 0xa80c, 0x6914, 0x460b, 0x0302, 0xe511, 0x671a, 0x8612, 0xa502, 0x6402, 0x0302, 0x2302, 0xe60a, 0x2a1c, 0x6b1c, 0x8b13, 0x4a13, 0xd14c, 0xf55d, 0xb86e, 0x3a77, 0x3b7f, 0x7d8f, 0x7d8f, 0x7d97, 0x9e97, 0x5d97, 0x5e97, 0x5e9f, 0x5e9f, 0x7f9f, 0x7e97, 0x5fbf, 0x9cc6, 0xb8b5, 0x56bd, 0x8f9b, 0xac8a, 0x4d7b, 0xae6c, 0x8a2c, 0xc914, 0xe90c, 0xe90c, 0xea04, 0xe903, 0x0612, 0xc719, 0x8822, 0xa612, 0x8b24, 0x2b1d, 0xea0c, 0x490c, 0x2713, 0xa92b, 0x060b, 0xc80b, 0xaa14, 0xe90c, 0xc804, 0x2c25, 0x0f25, 0x4e54, 0x73bd, 0x53cd, 0x74cd, 0x94bd, 0x74cd, 0x14dd, 0x34d5, 0x74c5, 0x74cd, 0x53c5, 0x32bd, 0x12bd, 0xf2ac,
		0xd1b4, 0xb0b4, 0x8fb4, 0x6e9c, 0x484b, 0x4603, 0x680c, 0x8704, 0x670c, 0x870c, 0xa80c, 0x880c, 0x880c, 0x880c, 0x880c, 0x880c, 0x880c, 0xa80c, 0xa804, 0xa804, 0xa80c, 0xa914, 0xe813, 0xa502, 0xc401, 0x2502, 0x480b, 0x2b1c, 0x0914, 0x4503, 0x6403, 0x4714, 0xc814, 0xaa04, 0x6d04, 0x1556, 0x5c8f, 0x7d97, 0x7e97, 0x5e8f, 0x5e97, 0x1d97, 0x5d8f, 0x3d8f, 0x7e97, 0x5e97, 0x3e9f, 0x5e9f, 0x3e9f, 0x5fa7, 0x5eaf, 0x7cbe, 0xf18b, 0x8f9b, 0xec9a, 0x6498, 0xe9c1, 0x0dd3, 0x667a, 0xe84b, 0xc91c, 0xe904, 0xca0c, 0xcb0c, 0x6a14, 0xc502, 0x8201, 0x8201, 0xe602, 0x8a1c, 0xca0c, 0xca14, 0x4603, 0x082b, 0x4a43, 0x693b, 0xe71a, 0x4a1c, 0xc914, 0xc804, 0xeb14, 0x4f2d, 0x2d3c, 0x32ad, 0x54cd, 0x54cd, 0x74c5, 0x54cd, 0x14dd, 0x34d5, 0x74c5, 0x54cd, 0x54cd, 0x53c5, 0x32bd, 0x12b5,
		0x8fac, 0x0dac, 0x8b9b, 0x4a83, 0x084b, 0x0503, 0x480c, 0x6704, 0x670c, 0x870c, 0x880c, 0x880c, 0x880c, 0x880c, 0x880c, 0x880c, 0x880c, 0x880c, 0xa80c, 0xa804, 0xa80c, 0x8914, 0x4a1c, 0x681b, 0xe401, 0x4502, 0x0a1c, 0xab24, 0xaa14, 0xa914, 0x8814, 0xa914, 0xa904, 0x0c05, 0x543e, 0xbc7f, 0x9e97, 0x7f97, 0x3e8f, 0x5f97, 0x5e97, 0x3e9f, 0x5e97, 0x7e97, 0x5e9f, 0x5e9f, 0x3e9f, 0x1e9f, 0x5fa7, 0xfd9e, 0x778d, 0xb183, 0x2a7a, 0x6eab, 0x2892, 0x24a1, 0xe7c1, 0xaaca, 0xa489, 0x475b, 0x8924, 0xea04, 0xcb14, 0xaa14, 0xaa14, 0x680c, 0x670b, 0x871b, 0x6a1c, 0xca14, 0xc904, 0xaa0c, 0x4703, 0x461a, 0xe521, 0xa72a, 0xe71a, 0x4a1c, 0xc90c, 0xe804, 0xeb14, 0x4f2d, 0xec2b, 0xf194, 0x34c5, 0x13c5, 0x74c5, 0x54cd, 0x14d5, 0x34d5, 0x74c5, 0x74cd, 0x74cd, 0x53c5, 0x32c5, 0xf1bc,
		0x2ea4, 0x6b9b, 0xc98a, 0xa872, 0x6642, 0xe50a, 0x4814, 0x880c, 0x680c, 0x870c, 0x870c, 0x870c, 0x870c, 0x880c, 0x880c, 0x880c, 0x880c, 0x880c, 0xa80c, 0xa80c, 0xa80c, 0x8914, 0xe813, 0xc602, 0x4a2b, 0x8a2b, 0xa813, 0x4914, 0x890c, 0xa90c, 0x6a0c, 0x8b0c, 0x7135, 0x796f, 0xba77, 0x3977, 0x9976, 0x196e, 0x3966, 0x1d7f, 0x7e8f, 0x5e8f, 0x5e97, 0x5e97, 0x9b8e, 0x187e, 0xf97d, 0x7b8e, 0x3ea7, 0xdd9e, 0x3374, 0x4b6a, 0x0a8a, 0x0cb3, 0x07aa, 0xc3a8, 0xc3b0, 0xc298, 0x4389, 0x4763, 0x891c, 0xea04, 0x8a14, 0x8a14, 0xa90c, 0xc904, 0xa914, 0x891c, 0xa914, 0xc904, 0xe904, 0xca0c, 0x0914, 0x0302, 0x030a, 0x4402, 0x6703, 0xaa14, 0xa804, 0xa704, 0xaa14, 0x2f35, 0x2d24, 0xf18c, 0x13bd, 0xf4cc, 0x34c5, 0x33c5, 0x13d5, 0x13cd, 0x33c5, 0x34cd, 0x54cd, 0x53cd, 0x32cd, 0xf1c4,
		0xcc9b, 0xe98a, 0x677a, 0x066a, 0x2542, 0xa51a, 0x0814, 0x680c, 0x680c, 0x670c, 0x6704, 0x870c, 0x870c, 0x880c, 0x880c, 0x880c, 0x880c, 0x880c, 0x880c, 0xa80c, 0x880c, 0x6914, 0x4603, 0xc60a, 0x316d, 0xaf5c, 0x0613, 0x8603, 0x890c, 0xaa0c, 0x6b14, 0xae1c, 0xfa76, 0x1a77, 0x7035, 0xae24, 0xae24, 0xef24, 0xf124, 0x7335, 0xba66, 0x7e8f, 0x7f9f, 0xfd8e, 0x7244, 0xb35c, 0x7675, 0x7254, 0x7b8e, 0x3ea7, 0x526c, 0x0a6a, 0xa989, 0x09aa, 0xe8c9, 0x67d1, 0xe6c0, 0x64a0, 0x8da3, 0x3085, 0xaa04, 0xc904, 0x8914, 0x8914, 0xc80c, 0xe804, 0xc804, 0xc804, 0xc804, 0xc904, 0xc904, 0xc904, 0xaa14, 0xe81b, 0x660b, 0xe70b, 0x8914, 0xa90c, 0xa704, 0xc804, 0x8904, 0xad1c, 0x4d1c, 0x8f74, 0xf3b4, 0xd3cc, 0x14c5, 0x13bd, 0xf3cc, 0xd2c4, 0x12c5, 0x13cd, 0x33cd, 0x33c5, 0x12c5, 0xf2cc,
		0x4b93, 0xa77a, 0x2672, 0xc461, 0x054a, 0x641a, 0x870b, 0x480c, 0x480c, 0x670c, 0x670c, 0x670c, 0x670c, 0x870c, 0x880c, 0x880c, 0x880c, 0x880c, 0x880c, 0x880c, 0x880c, 0x6914, 0x460b, 0xa612, 0x2933, 0xe92a, 0x071b, 0xe813, 0x690c, 0x890c, 0xaa0c, 0x503d, 0xf876, 0x8f24, 0x2a04, 0xcb1c, 0xaa14, 0xca0c, 0xeb04, 0xce0c, 0x7445, 0x3d8f, 0x5e97, 0x5665, 0x514c, 0x9154, 0xb264, 0x7154, 0x566d, 0x1da7, 0xb36c, 0xa440, 0x2679, 0x4699, 0xa8b9, 0x2ad2, 0xeab9, 0x0da3, 0x17be, 0xf375, 0xa904, 0xc904, 0x8814, 0xa80c, 0xc804, 0xc80c, 0xc804, 0xc804, 0xa80c, 0xa90c, 0xa90c, 0xc904, 0xa90c, 0xa914, 0xa81c, 0x870c, 0x870c, 0x870c, 0x870c, 0x870c, 0x890c, 0xed14, 0xae1c, 0x2e5c, 0xd3ac, 0x73c4, 0xd3c4, 0x13c5, 0x13cd, 0xf2cc, 0x13c5, 0xf3cc, 0x13cd, 0x13c5, 0x12c5, 0xd2c4,
		0xe982, 0x6672, 0x056a, 0xc461, 0xe449, 0x241a, 0x460b, 0x2814, 0x480c, 0x670c, 0x6704, 0x670c, 0x670c, 0x880c, 0x880c, 0x880c, 0x870c, 0x880c, 0x880c, 0x880c, 0x880c, 0x6914, 0xc813, 0x4402, 0x8301, 0x8401, 0xc70a, 0x2a1c, 0x890c, 0xa804, 0xa90c, 0x8b24, 0x0e3d, 0x4b1c, 0x6a0c, 0xc90c, 0xc704, 0x490d, 0xec1d, 0x8b04, 0x6f2c, 0xdb86, 0x3d97, 0x565d, 0x6d2b, 0x891a, 0x6912, 0x8e3b, 0xd35c, 0x1ca7, 0x147d, 0x8749, 0x8779, 0x4679, 0x8689, 0x6681, 0xeb7a, 0x179e, 0xd996, 0xef2c, 0xca04, 0xa804, 0x8714, 0xa70c, 0xc704, 0xa80c, 0xa804, 0xa804, 0x8814, 0x6814, 0x8814, 0xa90c, 0x8804, 0x8804, 0x870c, 0x8614, 0x6614, 0x6714, 0x871c, 0x8714, 0x890c, 0xcd0c, 0xef14, 0x0d4c, 0x92a4, 0x73c4, 0xb2bc, 0xf3bc, 0xf3cc, 0xf3cc, 0x33cd, 0xf3cc, 0x13cd, 0x13c5, 0xf2c4, 0xd2c4,
		0xc97a, 0x466a, 0xc469, 0x8461, 0x8449, 0x0422, 0x050b, 0x2814, 0x480c, 0x670c, 0x8704, 0x8804, 0x6804, 0x680c, 0x6814, 0x6814, 0x670c, 0x880c, 0x680c, 0x680c, 0x470c, 0x4714, 0x891c, 0xe713, 0x050b, 0x2503, 0x080c, 0x4814, 0x470c, 0x880c, 0x680c, 0x4603, 0xaa23, 0xca23, 0x690c, 0x880c, 0xc604, 0xe604, 0xc80c, 0x6a0c, 0x0d14, 0x986e, 0xbc8f, 0x366e, 0xce33, 0x2912, 0x491a, 0x4d33, 0x766d, 0xfb96, 0xd46c, 0x0d5b, 0xac6a, 0x4a6a, 0x285a, 0xea52, 0x9485, 0xf575, 0xee34, 0x6904, 0xa90c, 0xa90c, 0x880c, 0xa80c, 0xa80c, 0xa80c, 0x880c, 0x870c, 0x880c, 0x880c, 0x880c, 0xa80c, 0xa80c, 0xa80c, 0xa70c, 0x870c, 0x880c, 0x880c, 0x870c, 0x870c, 0x890c, 0xed14, 0x0f1d, 0xeb3b, 0x70a4, 0x71bc, 0xf1ac, 0xf2b4, 0x92cc, 0xd3cc, 0x54bd, 0x33c5, 0x13c5, 0x13c5, 0xf2c4, 0xd1c4,
		0xa97a, 0x266a, 0xa469, 0x6461, 0x6449, 0xe429, 0xc50a, 0x080c, 0x480c, 0x670c, 0x670c, 0x8804, 0x6804, 0x490c, 0x4914, 0x680c, 0xa804, 0xa804, 0x880c, 0x680c, 0x470c, 0x870c, 0x870c, 0x8814, 0x691c, 0x6914, 0x890c, 0x680c, 0x8814, 0x870c, 0x6814, 0x2603, 0xe812, 0x2813, 0x280c, 0x880c, 0xa70c, 0xc704, 0x8704, 0x4a04, 0x1135, 0xfb76, 0x5d87, 0x1d8f, 0x355d, 0x6d23, 0xeb12, 0x0f2c, 0x1666, 0xd565, 0xef43, 0x6d4b, 0x2d53, 0x0c5b, 0x2d5b, 0x5585, 0xda96, 0xb034, 0x4904, 0x880c, 0x890c, 0x880c, 0x880c, 0x880c, 0x880c, 0x880c, 0x880c, 0x870c, 0x870c, 0x870c, 0xa70c, 0xa70c, 0xa70c, 0xa70c, 0xa70c, 0x870c, 0x880c, 0x880c, 0x870c, 0xa70c, 0x6804, 0x8b0c, 0x0e1d, 0xc923, 0x2f94, 0x91bc, 0xf1a4, 0xd1b4, 0x72d4, 0xb3cc, 0x33bd, 0x12bd, 0xf2bc, 0xf2c4, 0xd1bc, 0xb1bc,
		0xa87a, 0x256a, 0xa461, 0x6461, 0x6449, 0xc429, 0x640a, 0xc70b, 0x480c, 0x470c, 0x670c, 0x6804, 0x6804, 0x690c, 0x4904, 0x6904, 0x6904, 0x890c, 0x480c, 0x6804, 0xa80c, 0x8704, 0x8704, 0x8804, 0x880c, 0x890c, 0x880c, 0x680c, 0x880c, 0x870c, 0x680c, 0xc80b, 0xe70a, 0xe60a, 0xc703, 0x8914, 0xa80c, 0xc90c, 0xaa0c, 0x0f25, 0xf96e, 0x5d87, 0x1f8f, 0x7b7e, 0xf765, 0x8f34, 0xa903, 0x4b14, 0x6b04, 0xea03, 0xa602, 0x4a2b, 0x6d43, 0x4e43, 0x5364, 0x9b96, 0x3c87, 0x7445, 0x6904, 0x880c, 0x880c, 0x880c, 0x880c, 0x880c, 0x880c, 0x880c, 0x870c, 0x870c, 0x870c, 0x870c, 0x870c, 0xa70c, 0xa70c, 0xa70c, 0x870c, 0x870c, 0x880c, 0x880c, 0x870c, 0x8604, 0x8704, 0x6904, 0xab0c, 0xe913, 0x0e84, 0x70b4, 0xb0a4, 0xb1b4, 0x71cc, 0x92cc, 0x13bd, 0xf2c4, 0xf2c4, 0xb1bc, 0xb1bc, 0xb1bc,
		0x8872, 0x256a, 0xa461, 0x6459, 0x6449, 0xa431, 0x230a, 0x8613, 0x280c, 0x270c, 0x470c, 0x6804, 0x4804, 0x2914, 0xad3c, 0x6c34, 0x4703, 0x8703, 0x2814, 0x2704, 0x4704, 0x6704, 0x8804, 0x880c, 0x880c, 0x8804, 0xa80c, 0x680c, 0x870c, 0x6704, 0x680c, 0x4914, 0x681b, 0x481b, 0x8813, 0x0914, 0x2914, 0x290c, 0x4c0c, 0x1556, 0x1b7f, 0x1d87, 0xd86d, 0xad13, 0x2b0c, 0x890c, 0x8804, 0x8804, 0x6804, 0x6904, 0x2c2c, 0xd14c, 0x724c, 0xd564, 0x3b86, 0x1d97, 0x5c87, 0xb33d, 0x6904, 0x880c, 0x880c, 0x880c, 0x870c, 0x870c, 0x870c, 0x870c, 0x870c, 0x870c, 0x870c, 0x870c, 0x870c, 0x870c, 0x870c, 0x870c, 0x870c, 0x870c, 0x680c, 0x870c, 0x870c, 0x8504, 0x860c, 0x4704, 0xeb1c, 0x4b14, 0xac6b, 0x2fa4, 0x70a4, 0x4fac, 0x30bc, 0x72c4, 0xd2bc, 0xf2c4, 0xf2c4, 0xb1bc, 0x91bc, 0x90bc,
		0x887a, 0x056a, 0xa461, 0x6459, 0x4349, 0x8339, 0xe319, 0x260b, 0x480c, 0x470c, 0x4704, 0x6804, 0x280c, 0x880b, 0xae4c, 0xaf5c, 0x1175, 0x282b, 0x460b, 0x4814, 0x680c, 0x670c, 0x670c, 0x680c, 0x680c, 0x8804, 0x6804, 0x6704, 0x6804, 0x8804, 0x880c, 0x280c, 0xc502, 0x640a, 0xe612, 0x2713, 0x280b, 0x6a0b, 0x534d, 0xdb7e, 0xfd8e, 0xfd8e, 0x7555, 0xec0b, 0x4a04, 0x8904, 0xca14, 0x2e35, 0x714d, 0x3676, 0xda86, 0xdc8e, 0x7c8e, 0xbd96, 0x1e97, 0x5c8f, 0x387f, 0x2e2d, 0x4704, 0x670c, 0x670c, 0x870c, 0x870c, 0x870c, 0x870c, 0x870c, 0x870c, 0x870c, 0x870c, 0x870c, 0x670c, 0x670c, 0x670c, 0x670c, 0x670c, 0x670c, 0x680c, 0x680c, 0x860c, 0x850c, 0x6504, 0x6604, 0xca14, 0x6b1c, 0x8b53, 0xee93, 0xee9b, 0xeea3, 0xefb3, 0x50bc, 0x71b4, 0x91bc, 0xb1bc, 0x91bc, 0x90bc, 0x70b4,
		0x887a, 0x056a, 0xc461, 0x8459, 0x4351, 0x6341, 0xc321, 0xe512, 0x280c, 0x670c, 0x4704, 0x6804, 0x070c, 0xe502, 0xc201, 0xc93a, 0x2f6c, 0xac4b, 0x8402, 0x080c, 0x680c, 0x470c, 0x2714, 0x2714, 0x480c, 0x6804, 0x6804, 0x680c, 0x6804, 0x6804, 0x680c, 0xe70b, 0x8302, 0xe101, 0xc201, 0xc201, 0xc80a, 0xd24c, 0xbb86, 0xfd8e, 0xfd96, 0xdd8e, 0xdb7e, 0x3866, 0x175e, 0x996e, 0xfb7e, 0x1d8f, 0xfe96, 0xde9e, 0x1f9f, 0xfe96, 0x1f97, 0xfd8e, 0x1c8f, 0xb876, 0x9045, 0x6814, 0x480c, 0x670c, 0x680c, 0x670c, 0x670c, 0x670c, 0x670c, 0x670c, 0x670c, 0x670c, 0x670c, 0x670c, 0x670c, 0x670c, 0x670c, 0x670c, 0x670c, 0x670c, 0x670c, 0x680c, 0x670c, 0x860c, 0x650c, 0x660c, 0x890c, 0x6c14, 0x6a43, 0xcd83, 0x8d9b, 0xada3, 0xaea3, 0xefab, 0xefab, 0x2fac, 0x50b4, 0x50b4, 0x70b4, 0x70b4,
		0x687a, 0x056a, 0xc461, 0x8459, 0x6451, 0x6341, 0xa329, 0xa412, 0x070c, 0x470c, 0x470c, 0x4704, 0x270c, 0x460b, 0xe201, 0x462a, 0x2622, 0x6622, 0xc502, 0x490c, 0x6804, 0x670c, 0x2714, 0x2714, 0x480c, 0x6804, 0x6704, 0x470c, 0x480c, 0x6804, 0x680c, 0xe70b, 0xa302, 0xe101, 0xa101, 0xa101, 0xea1a, 0xf875, 0x3d97, 0x1e97, 0xdd8e, 0xdd8e, 0x1d87, 0x3e87, 0x3e8f, 0x1f8f, 0xff8e, 0xdf8e, 0xdf96, 0xbe96, 0xfe96, 0x1e8f, 0x9b7e, 0x334d, 0xaf34, 0x6c1c, 0x290c, 0x280c, 0x680c, 0x680c, 0x680c, 0x680c, 0x680c, 0x670c, 0x670c, 0x670c, 0x670c, 0x670c, 0x670c, 0x670c, 0x670c, 0x670c, 0x670c, 0x670c, 0x660c, 0x660c, 0x470c, 0x480c, 0x670c, 0x660c, 0x660c, 0x670c, 0x690c, 0x6c0c, 0x2923, 0x6b73, 0x4c93, 0x6c9b, 0x8d9b, 0x8d9b, 0xaea3, 0xefab, 0x0fac, 0x2fac, 0x4fb4, 0x4fac,
		0x4772, 0xe569, 0xa459, 0x8459, 0x6451, 0x4449, 0x8331, 0x630a, 0xc703, 0x2714, 0x2714, 0x2704, 0x470c, 0xe713, 0xa40a, 0xe201, 0xc401, 0x450a, 0xc91b, 0x690c, 0x8804, 0x8804, 0x270c, 0x2714, 0x6704, 0x6704, 0x470c, 0x470c, 0x470c, 0x480c, 0x480c, 0x281c, 0x0513, 0x0102, 0xc001, 0xc101, 0x4c23, 0x9a7e, 0x3e8f, 0x1e8f, 0x1d8f, 0x1d8f, 0x1c87, 0x1d8f, 0xfd8e, 0xde8e, 0xfe8e, 0x1d8f, 0x3b8f, 0x5b8f, 0x5d97, 0x5c8f, 0xb876, 0x2c04, 0xe903, 0x0a04, 0x4b04, 0x6b0c, 0x2804, 0x4804, 0x480c, 0x480c, 0x680c, 0x680c, 0x680c, 0x680c, 0x670c, 0x670c, 0x670c, 0x670c, 0x670c, 0x670c, 0x670c, 0x6704, 0x660c, 0x660c, 0x470c, 0x480c, 0x4704, 0x4604, 0x670c, 0x470c, 0x6904, 0xcd14, 0x8a23, 0x2b6b, 0x0b93, 0x2b93, 0x6c93, 0x6c93, 0x6da3, 0xaea3, 0xefab, 0x0fac, 0x2fac, 0x2fac,
		0x6772, 0x056a, 0xc461, 0x8459, 0x4351, 0x4349, 0x6331, 0x2312, 0x6613, 0x0714, 0x270c, 0x470c, 0x470c, 0x4714, 0x0714, 0x6603, 0x2503, 0x860b, 0x0714, 0x2804, 0x6804, 0x6804, 0x480c, 0x270c, 0x470c, 0x6704, 0x4704, 0x470c, 0x470c, 0x470c, 0x6704, 0x470c, 0x0714, 0x860b, 0x260b, 0x4813, 0xe80a, 0xd24c, 0x9a7e, 0xdc86, 0xbc7e, 0x5a6e, 0x9776, 0x1b87, 0x1d8f, 0xfe96, 0xfe8e, 0x3d8f, 0x5c8f, 0x5b8f, 0x1c8f, 0x1c8f, 0xfb7e, 0x554d, 0x9555, 0x3766, 0x9976, 0xda7e, 0x3766, 0x8d24, 0x680c, 0x670c, 0x2704, 0x2804, 0x4804, 0xa704, 0x8704, 0x4704, 0x480c, 0x270c, 0x480c, 0x480c, 0x4704, 0x8704, 0x8604, 0x660c, 0x6704, 0x6804, 0x670c, 0x470c, 0x270c, 0x280c, 0x6a0c, 0x2e25, 0x2c24, 0x2a53, 0x0b83, 0x0a93, 0x6b8b, 0x6d93, 0x4da3, 0x8ea3, 0xcea3, 0xcea3, 0xcea3, 0xceab,
		0x476a, 0xe561, 0xa461, 0x6459, 0x2351, 0x2349, 0x6331, 0xe311, 0x2613, 0x080c, 0x270c, 0x270c, 0x470c, 0x470c, 0x480c, 0x0804, 0xe803, 0x0804, 0x280c, 0x280c, 0x480c, 0x480c, 0x480c, 0x470c, 0x470c, 0x470c, 0x470c, 0x270c, 0x2714, 0x470c, 0x6704, 0x4704, 0x280c, 0x2814, 0x0814, 0xc713, 0xc402, 0x6713, 0x8a23, 0x0d2c, 0x4e1c, 0xec03, 0x3245, 0x3b8f, 0xfd8e, 0xfe8e, 0xfe96, 0x1e97, 0x1d8f, 0x1c8f, 0xfd8e, 0x3e97, 0x1d8f, 0x1d87, 0x3d8f, 0x3d8f, 0x3d8f, 0x3d97, 0x5e8f, 0x3666, 0x4904, 0x4804, 0x7045, 0x1456, 0x2f35, 0x8804, 0x6704, 0x280c, 0x2814, 0xe813, 0xe81b, 0x281c, 0x6814, 0x6704, 0x8604, 0x660c, 0x6704, 0x6704, 0x670c, 0x6614, 0x460c, 0x470c, 0x6904, 0x2e25, 0x8d24, 0x2a43, 0x0b7b, 0xea8a, 0x2a83, 0x2c8b, 0x0d9b, 0x4d9b, 0x8d9b, 0xad9b, 0xad9b, 0xada3,
		0x266a, 0xc561, 0xa459, 0x6459, 0x4351, 0x2349, 0x8339, 0xc211, 0xe50a, 0xe813, 0x080c, 0x270c, 0x470c, 0x470c, 0xe803, 0x0f3d, 0xd455, 0xf03c, 0x2a0c, 0xe903, 0x480c, 0x470c, 0x4704, 0x470c, 0x270c, 0x280c, 0x280c, 0x0814, 0x0814, 0x270c, 0x470c, 0x280c, 0x280c, 0x0814, 0x271c, 0x0303, 0x6513, 0x650b, 0xa002, 0xc603, 0x2804, 0x0904, 0x1345, 0xfb86, 0xfc8e, 0xfd96, 0xfe96, 0xfe96, 0xfe96, 0x1e97, 0xfd96, 0x1d97, 0x1d8f, 0x3d8f, 0x3d8f, 0x1c8f, 0x1c8f, 0x1c97, 0x3e8f, 0xba76, 0x8f24, 0xd455, 0x3b7f, 0x7e8f, 0xd976, 0xad24, 0x0804, 0x2914, 0x670b, 0x850a, 0xea33, 0x271b, 0xa70b, 0x480c, 0x670c, 0x660c, 0x670c, 0x680c, 0x670c, 0x660c, 0x6504, 0x6604, 0x6804, 0xcd14, 0x8e1c, 0x2b3b, 0x0b7b, 0xca82, 0x097b, 0xeb82, 0xec92, 0x4c8b, 0x6c8b, 0x8c93, 0xac9b, 0xcc9b,
		0xe669, 0xa559, 0x8451, 0x6451, 0x2349, 0x0341, 0x4331, 0xa219, 0x840a, 0xc813, 0x080c, 0x270c, 0x4604, 0x2604, 0x6a1c, 0xd76e, 0x7d8f, 0x3c87, 0x165e, 0x8d1c, 0x0804, 0x4704, 0x4604, 0x470c, 0x270c, 0x2804, 0x2904, 0x080c, 0x0714, 0x270c, 0x470c, 0x470c, 0x080c, 0x081c, 0x6713, 0xe60a, 0x8913, 0xe702, 0x6e3c, 0xb355, 0x555e, 0xb86e, 0xdb7e, 0x1d8f, 0x1c8f, 0xfc96, 0xfd96, 0xfd96, 0xfe96, 0xff96, 0x1e97, 0xfe8e, 0x1d8f, 0x1d8f, 0x1c8f, 0x1c8f, 0x1d97, 0xfd96, 0x1e97, 0x1d87, 0x5445, 0x1c7f, 0x3f8f, 0xff8e, 0x1e8f, 0xf665, 0xef34, 0xca0b, 0x6502, 0x4a3b, 0x8f64, 0x0833, 0xc502, 0x2814, 0x270c, 0x270c, 0xc70b, 0x6603, 0x8503, 0x060c, 0x660c, 0x4604, 0x4804, 0xad14, 0xef24, 0x4b2b, 0x0c6b, 0xaa7a, 0xa87a, 0xa97a, 0xab8a, 0x0c83, 0x2b83, 0x6a8b, 0x8a93, 0xab93,
		0x6459, 0x4351, 0x2349, 0xe240, 0xc240, 0xc238, 0xe128, 0x4111, 0x230a, 0x870b, 0xe70b, 0x260c, 0x4504, 0x2504, 0x8b24, 0xd876, 0x5d8f, 0x5e8f, 0x5d87, 0x9766, 0xed2c, 0x0604, 0x2604, 0x470c, 0x2704, 0x2804, 0x4804, 0x270c, 0x270c, 0x260c, 0x6704, 0x4704, 0x270c, 0xa713, 0xa502, 0x491b, 0x8c2b, 0xb66d, 0xfc8e, 0x1e8f, 0x3e8f, 0x1e87, 0x1e8f, 0x1d8f, 0xfc8e, 0x1c97, 0xfc96, 0x1d97, 0x1e97, 0x1f97, 0xff8e, 0xff8e, 0x1e8f, 0x1e8f, 0x3e97, 0x1e97, 0xfe96, 0xfe96, 0x3e9f, 0x1d8f, 0xd755, 0xfc7e, 0x3f8f, 0xff96, 0x1e97, 0x3d97, 0xf97e, 0xed1b, 0xe501, 0xca32, 0xad53, 0xc82a, 0xa502, 0xe813, 0x0814, 0x0a24, 0x281b, 0x4a33, 0x0823, 0x0403, 0x070c, 0x270c, 0x290c, 0x8c0c, 0xce1c, 0x8b23, 0xea5a, 0xa972, 0xa872, 0xa97a, 0xaa82, 0xeb7a, 0x0a7b, 0x4983, 0x698b, 0x4a7b,
		0x4451, 0xe240, 0xc138, 0x8138, 0x6030, 0x4028, 0x6018, 0xe008, 0xe309, 0x450b, 0xe60b, 0x260c, 0x2604, 0x0704, 0x0904, 0x3245, 0xfb86, 0x3e8f, 0x3e8f, 0x7c87, 0xd24d, 0x4904, 0x2704, 0x2704, 0x2704, 0x6804, 0x4704, 0x0604, 0x260c, 0x260c, 0x4604, 0x2704, 0x070c, 0xe302, 0x0613, 0x2713, 0x3265, 0xfb96, 0xfd96, 0xfe96, 0xff96, 0xff8e, 0xfe8e, 0xfe8e, 0x1d97, 0x1c97, 0x1c8f, 0xfc8e, 0x596e, 0x396e, 0xfe8e, 0x1e8f, 0x5e8f, 0x1d8f, 0x3e8f, 0x1e8f, 0xff96, 0xdf96, 0xfd96, 0x5d8f, 0xb655, 0xd655, 0xdb7e, 0x3d97, 0x3d9f, 0x1c97, 0x5c97, 0xf765, 0x8e33, 0x8601, 0xa501, 0xe401, 0x2713, 0x281c, 0x0814, 0xa91b, 0x2a2b, 0x7064, 0xf16c, 0x2723, 0x6603, 0x081c, 0x0914, 0x4a0c, 0xed14, 0xcb1b, 0x8942, 0x6862, 0x676a, 0xa972, 0xa97a, 0xa972, 0xc972, 0xc86a, 0x096b, 0xe962,
		0x897a, 0xa559, 0x6449, 0x0341, 0xc238, 0xa138, 0xa128, 0xe110, 0xc309, 0x050b, 0x081c, 0xc70b, 0x0804, 0x4b0c, 0xab03, 0xf244, 0x1c8f, 0x3e97, 0x1d8f, 0x7c87, 0x934d, 0xc903, 0xe803, 0x2804, 0x2704, 0x2704, 0x270c, 0x2714, 0xe713, 0x0714, 0xe70b, 0x0914, 0x2603, 0xa302, 0x250b, 0xa402, 0x3676, 0x3c97, 0xfd96, 0xfd96, 0xfd96, 0xfd96, 0xfe8e, 0xfe8e, 0xfe96, 0xfd8e, 0x3d8f, 0x3766, 0xec03, 0x2d0c, 0x796e, 0x5c8f, 0x7c8f, 0x786e, 0x1766, 0xfc86, 0x1e97, 0xff96, 0x1e97, 0x5e97, 0x175e, 0xcc03, 0xd034, 0x1a87, 0x3b8f, 0x5d97, 0x3d8f, 0x5d97, 0xbb8e, 0x0f3c, 0x4702, 0x280b, 0xe913, 0x070c, 0x280c, 0x4603, 0x2612, 0x2c43, 0xd064, 0x4823, 0x8603, 0x0814, 0xe813, 0x4914, 0xab0c, 0xea13, 0xa83a, 0x475a, 0x475a, 0x675a, 0x4762, 0x666a, 0x465a, 0x874a, 0xc94a, 0x893a,
		0x4b8b, 0x276a, 0xa559, 0x6451, 0x2349, 0xe240, 0xe230, 0x0219, 0x8309, 0xe50a, 0xa813, 0x0b14, 0x3556, 0xd966, 0x175e, 0x9b7e, 0x3d97, 0x1d8f, 0x5e8f, 0x7a6e, 0x7024, 0x8e24, 0x8c14, 0x2804, 0x470c, 0x270c, 0xc813, 0x4613, 0xc502, 0x060b, 0x891b, 0x280b, 0x4b33, 0x325d, 0xb03c, 0x4c03, 0x1866, 0x3e8f, 0x1e8f, 0x1d8f, 0x1d8f, 0x1c8f, 0xfd96, 0xfe96, 0x1e97, 0xfe8e, 0x5d8f, 0x5766, 0x0a04, 0xe903, 0x303d, 0xb76e, 0x5566, 0x4c1c, 0xab03, 0xb55d, 0x3d8f, 0x1e97, 0x1f97, 0x5e8f, 0xba6e, 0x0d04, 0x0b04, 0xd35d, 0x1a87, 0x1d87, 0x3e97, 0x1d97, 0x3c8f, 0xf665, 0xd034, 0x2b14, 0x0804, 0x2704, 0x870c, 0x0604, 0x4302, 0x2201, 0x661a, 0xe502, 0x070c, 0x060c, 0xe713, 0x0614, 0x2804, 0x8803, 0x662a, 0xe549, 0xe549, 0x064a, 0x0652, 0x2452, 0x4542, 0x662a, 0x681a, 0x6912,
		0xcd9b, 0xa97a, 0xe661, 0x8559, 0x4449, 0x0341, 0x2339, 0x2329, 0x6319, 0x840a, 0x8703, 0x1035, 0x3b7f, 0x7e8f, 0x5e8f, 0x3e8f, 0x1e9f, 0x3d97, 0xfb7e, 0x133d, 0xf75d, 0x1b7f, 0xb876, 0x0f3d, 0x2704, 0x0804, 0x270b, 0x4402, 0xa71a, 0x081b, 0x4602, 0x4b23, 0x5886, 0x3c9f, 0x1c87, 0x1866, 0xd955, 0x1e87, 0x1e8f, 0x1d8f, 0x1d8f, 0x1d8f, 0x3e97, 0xbd86, 0xf96d, 0xdb76, 0x1a77, 0x513d, 0x0904, 0x2804, 0x0a04, 0x090c, 0x2804, 0xe803, 0xeb0b, 0xf665, 0x5c97, 0x1c97, 0x1e97, 0x3e8f, 0xfb76, 0xae1c, 0x0904, 0xe803, 0xae2c, 0x996e, 0x7c8f, 0x1c8f, 0xfd96, 0x1d97, 0x1b87, 0xd24d, 0x0804, 0x0704, 0x2704, 0x6804, 0xa70b, 0x250b, 0x450b, 0xc60b, 0x460c, 0x2604, 0x060c, 0x0614, 0x0704, 0xa70b, 0xa61a, 0xe631, 0xc631, 0xe631, 0xe529, 0xe742, 0x2a5c, 0x883b, 0xa712, 0x890a,
		0x2fac, 0x2c8b, 0x4872, 0xc661, 0x6451, 0x2349, 0x2339, 0x2331, 0x2321, 0x2312, 0x660b, 0x8d1c, 0xb976, 0x3e97, 0x1d8f, 0x3d8f, 0x1d97, 0x1c8f, 0xb655, 0x7545, 0x3d7f, 0x3d8f, 0x3d9f, 0x166e, 0xef2c, 0x6d1c, 0xa702, 0x870a, 0xed43, 0x1265, 0x2a1b, 0x703c, 0xdb8e, 0xfc96, 0x3c8f, 0x3d87, 0x3a66, 0x1d87, 0x3d8f, 0x1d97, 0x1e97, 0x1e8f, 0x3d8f, 0x544d, 0xcc03, 0x6d24, 0xac24, 0x0804, 0x2704, 0x270c, 0x280c, 0x0704, 0x2604, 0x0704, 0x6d24, 0xba76, 0x5e97, 0x1c97, 0x1d8f, 0x1d8f, 0x3b87, 0x1035, 0xe803, 0x0704, 0xe803, 0x5045, 0x1877, 0x1a87, 0xde9e, 0xbfa6, 0xfd96, 0xf876, 0xcd24, 0x0a04, 0xc903, 0x0904, 0x0804, 0x2814, 0x060c, 0x260c, 0x250c, 0x250c, 0x260c, 0x070c, 0xe60b, 0xc613, 0x0613, 0x681a, 0x4922, 0x481a, 0x681a, 0xc822, 0xe943, 0xeb5c, 0x093c, 0xc812,
		0xb1b4, 0xad9b, 0x897a, 0xe661, 0x6459, 0x4349, 0x2341, 0x4331, 0x2329, 0xe311, 0x470b, 0xc903, 0x8e2c, 0xf565, 0x3a87, 0x9c87, 0x5c97, 0x587e, 0x0e24, 0xda76, 0x5d87, 0x1d8f, 0x1e9f, 0xfd96, 0x1c8f, 0x997e, 0x8c23, 0x6802, 0x4c33, 0x504c, 0x8d2b, 0x7565, 0x1c97, 0x1c97, 0x1c8f, 0x5d87, 0xf855, 0xbb76, 0x1d8f, 0xfd96, 0xfd8e, 0x1d8f, 0xfa86, 0x3045, 0xc803, 0x270c, 0x0504, 0x260c, 0x0504, 0x0604, 0xe603, 0x0504, 0x260c, 0x270c, 0xeb0b, 0xb655, 0xfc7e, 0xfc86, 0x1d8f, 0x1d8f, 0x5c87, 0xb34d, 0x0804, 0x270c, 0x080c, 0xe903, 0x0b0c, 0xb55d, 0xfe96, 0xdf9e, 0xfe96, 0x3c87, 0x1a7f, 0xf65d, 0x366e, 0xf565, 0x8d2c, 0xc803, 0x280c, 0x060c, 0x060c, 0x050c, 0x060c, 0x2704, 0x2604, 0x070c, 0x4703, 0xa80a, 0x8912, 0x890a, 0xa90a, 0x8a0a, 0xa70a, 0xa82b, 0xca4c, 0x8944,
		0xf1b4, 0x0ea4, 0xca7a, 0x066a, 0x8459, 0x6451, 0x4341, 0x4439, 0x4329, 0xc419, 0x060b, 0xe80b, 0xa703, 0xc813, 0x4f3d, 0xb666, 0x3566, 0x2d34, 0xcb13, 0x565e, 0xbd87, 0x5e8f, 0x3f97, 0xfe9e, 0xffa6, 0x1e9f, 0xd875, 0x935c, 0x6f3b, 0x8b12, 0x966d, 0x5d9f, 0x1d97, 0x1d97, 0x1c87, 0x1866, 0x501c, 0xbb76, 0x3d97, 0x1d97, 0x1d97, 0x3d8f, 0x3d8f, 0xf97e, 0xad34, 0xe603, 0x270c, 0xe70b, 0x0b14, 0x3245, 0xd455, 0x103d, 0x0804, 0x0804, 0xe903, 0x0b0c, 0x8e2c, 0xb034, 0x5a7e, 0x1d8f, 0x5d8f, 0x155e, 0xe803, 0x0604, 0x270c, 0xe70b, 0xc803, 0x8e2c, 0x997e, 0x1e97, 0x1e8f, 0x3e8f, 0x1d87, 0x5e8f, 0x1d97, 0x1c97, 0x576e, 0x6d24, 0xe803, 0x0704, 0x0604, 0x060c, 0x060c, 0x2704, 0x2604, 0x2704, 0x6703, 0xe902, 0xca02, 0xcb02, 0xeb02, 0xeb0a, 0xca0a, 0xc802, 0x6623, 0xc84c,
		0x12b5, 0x4fa4, 0x0a83, 0x276a, 0xa561, 0x6451, 0x4341, 0x4339, 0x2331, 0xa421, 0xa60a, 0xc70b, 0xe60b, 0xc60b, 0xe603, 0x0704, 0xc903, 0xa703, 0xc703, 0xee34, 0x1456, 0x7866, 0x3d87, 0x1e97, 0xfe9e, 0xfe9e, 0x1e97, 0xdd9e, 0x7b96, 0x1665, 0xbc8e, 0x5e9f, 0x1d97, 0x3d97, 0x186e, 0xac03, 0xac03, 0x5866, 0x1d8f, 0xfe96, 0x1d97, 0x1d8f, 0x3f8f, 0x3c87, 0x3145, 0xa803, 0xe90b, 0xaa03, 0xb655, 0x1e87, 0x3e8f, 0x1b7f, 0x1135, 0xe803, 0x2804, 0x0704, 0xa603, 0xc703, 0xf76d, 0xfd8e, 0x5d8f, 0x776e, 0x0904, 0x070c, 0x0604, 0x060c, 0x0704, 0xe803, 0x2c14, 0xb55d, 0x3d8f, 0xfd8e, 0x1e97, 0x1e97, 0xfd96, 0xfd96, 0x5c8f, 0x5556, 0x6b04, 0x2804, 0x2704, 0xe603, 0xe70b, 0x070c, 0x0604, 0x0704, 0x6703, 0xe902, 0xca02, 0xcb02, 0xeb02, 0xe902, 0xeb02, 0xab02, 0xa702, 0x441b,
		0x12bd, 0xb0ac, 0x8c8b, 0x6872, 0xc561, 0x6451, 0x4349, 0x2341, 0x0331, 0x6321, 0x850a, 0xa60b, 0xe60b, 0xe50b, 0x0604, 0x2704, 0xe80b, 0xe713, 0xe60b, 0xc703, 0xc803, 0x2b04, 0x9766, 0x7c8f, 0x1c97, 0x1d97, 0x3e97, 0x1e9f, 0xfe9e, 0xfd96, 0x3d8f, 0x1d8f, 0x3d97, 0x5d97, 0xf665, 0xaa03, 0xc903, 0xd555, 0x1d8f, 0xfe96, 0xfd96, 0x1c8f, 0x3d87, 0x9976, 0x6d24, 0xe803, 0xe803, 0x6d24, 0xda76, 0x3e8f, 0x1d8f, 0x5c8f, 0x355e, 0x0804, 0x2704, 0x0704, 0x2b1c, 0x1145, 0x7a86, 0xfe96, 0x1d8f, 0xba7e, 0x4c24, 0xe703, 0x0604, 0x260c, 0x0604, 0x2604, 0xe603, 0x8c24, 0xb97e, 0x1d97, 0xfe96, 0xfc96, 0xfc8e, 0x1d97, 0x5c8f, 0x5977, 0xce24, 0xe803, 0x090c, 0x0814, 0xc713, 0xc713, 0xe60b, 0x060c, 0x8703, 0xe802, 0xaa0a, 0xab02, 0xca02, 0x0803, 0xca02, 0x8b02, 0xcc12, 0x491b,
		0x32bd, 0xd1b4, 0xed9b, 0xa87a, 0xe569, 0x8459, 0x2349, 0x2341, 0x0339, 0x4321, 0x440a, 0x6603, 0xc60b, 0xc613, 0x0604, 0x0704, 0xc70b, 0xc60b, 0xc60b, 0xc713, 0x8713, 0x8803, 0xad24, 0xd355, 0xd565, 0x1b8f, 0x5d97, 0x1d97, 0x1d97, 0xfd8e, 0x9b76, 0x3d87, 0x3c8f, 0x3876, 0x8e2c, 0xc803, 0xe703, 0x3145, 0xdc86, 0xff96, 0x1e97, 0x1b8f, 0x524d, 0xea0b, 0x080c, 0x070c, 0xe603, 0x6b1c, 0xd76e, 0x5b87, 0x1a8f, 0x5b8f, 0xf45d, 0xe803, 0xe703, 0xe803, 0x9455, 0x1e8f, 0x1e97, 0xfd96, 0x1e97, 0xfc86, 0xaf34, 0xc703, 0xe603, 0x2704, 0x0604, 0x2604, 0x2604, 0x2904, 0x7776, 0x1d9f, 0xdd96, 0x3c97, 0x797e, 0xd665, 0xd97e, 0x1566, 0x2c24, 0xa90b, 0xe91b, 0x8813, 0x4713, 0xa713, 0xe60b, 0x060c, 0xc70b, 0xe702, 0xa90a, 0xaa0a, 0xca02, 0xe802, 0xc902, 0xec0a, 0x4d1b, 0x2b1b,
		0x12b5, 0xd1ac, 0xed9b, 0xe97a, 0xe569, 0x8459, 0x2351, 0x0341, 0xe238, 0x2221, 0x030a, 0x2503, 0xa713, 0xa713, 0xe703, 0xe703, 0xc613, 0xc713, 0x670b, 0xc50a, 0x8402, 0x270b, 0x8803, 0x8803, 0xca03, 0x1566, 0x1b87, 0x3c8f, 0x1c8f, 0x7655, 0x100c, 0xdb76, 0xdb7e, 0x0e24, 0xa803, 0x270c, 0xe503, 0xae2c, 0xbb7e, 0xff96, 0xfe96, 0xfa86, 0xcf2c, 0x8803, 0xc703, 0xe703, 0x080c, 0xc803, 0x914d, 0xf97e, 0x1c8f, 0xbb7e, 0x902c, 0xc903, 0x070c, 0x080c, 0x366e, 0x1e97, 0xfd96, 0xfd96, 0xfe96, 0x1d8f, 0x534d, 0xc803, 0x0804, 0x2704, 0xe70b, 0xe603, 0x2604, 0x8a14, 0xb876, 0x1e9f, 0xfe96, 0xdb86, 0xb03c, 0x4a03, 0x6a1b, 0x691b, 0xc712, 0x450a, 0xa61a, 0x650a, 0x4402, 0x870b, 0x070c, 0x0604, 0xe70b, 0x0703, 0xc90a, 0xc90a, 0xaa02, 0xcb0a, 0x0a13, 0x6a1b, 0x2a13, 0xca0a,
		0xf1bc, 0xb0ac, 0xed9b, 0xe982, 0x0562, 0x8459, 0x4351, 0x0341, 0xe238, 0x0229, 0xc211, 0x0503, 0xc70b, 0xc70b, 0xc70b, 0xc60b, 0xc613, 0x670b, 0x4402, 0xa82a, 0xcd4b, 0x292b, 0x0703, 0xca0b, 0xa903, 0x2c24, 0xf03c, 0x534d, 0xdb7e, 0x9b76, 0x185e, 0x7c87, 0x3666, 0xcb13, 0xc703, 0x0604, 0xc503, 0x2b1c, 0x5976, 0xfe8e, 0xfd8e, 0x1b8f, 0xf565, 0x534d, 0xf03c, 0xea03, 0xe803, 0xe803, 0xc903, 0x534d, 0xfe8e, 0x9c7e, 0x5024, 0xc903, 0x0704, 0x0704, 0x5155, 0xdb86, 0xfd8e, 0xfe8e, 0xde8e, 0x3d8f, 0xd55d, 0xc903, 0x0804, 0x0804, 0xe813, 0xc70b, 0x0704, 0xe803, 0xd45d, 0xfc8e, 0xfd96, 0xfc96, 0x1355, 0x8502, 0xa712, 0x450a, 0xe409, 0xc82a, 0x8b43, 0xd16c, 0xac43, 0x4603, 0xe70b, 0x0604, 0xe70b, 0x2603, 0xc80a, 0xc90a, 0xca0a, 0x0c13, 0x2b1b, 0xe70a, 0xc80a, 0xca0a,
		0xf1bc, 0xb1b4, 0x0ea4, 0x0a83, 0x066a, 0x8459, 0x4349, 0x2341, 0xe338, 0xe330, 0x6219, 0xe402, 0xe603, 0xe603, 0xa60b, 0xa613, 0xc70b, 0x0603, 0x0402, 0x2e5c, 0x9485, 0xad43, 0x6602, 0xe602, 0xe502, 0x2503, 0x8703, 0xaa03, 0xb555, 0x1c87, 0x5c87, 0xb76e, 0xad24, 0xc703, 0xe70b, 0xe60b, 0xc60b, 0xa903, 0x366e, 0x1c8f, 0x1d8f, 0x3d8f, 0x1c97, 0x3d8f, 0xdb76, 0x1035, 0x0704, 0xe503, 0xa703, 0x5455, 0x1d8f, 0x3d8f, 0xf65d, 0x0b04, 0xc703, 0xe803, 0xaa03, 0xd65d, 0x1e87, 0xff8e, 0xde8e, 0x1d8f, 0x5666, 0x0904, 0xe803, 0xe80b, 0xc713, 0xc613, 0xc70b, 0xe70b, 0xe90b, 0xf45d, 0x3b8f, 0xfc96, 0xd364, 0xa722, 0xed4b, 0x4a33, 0xa301, 0x8722, 0x2e54, 0xd58d, 0x4e5c, 0x2503, 0xc60b, 0xe603, 0xe70b, 0x460b, 0xc70a, 0xe912, 0x2b13, 0x0a13, 0xc90a, 0xa80a, 0xa90a, 0xca0a,
		0xd1bc, 0xb1b4, 0x2ea4, 0x2a8b, 0x476a, 0xa459, 0x6349, 0x2341, 0x0339, 0xe330, 0x4219, 0xa402, 0xa603, 0xc603, 0xa60b, 0xa613, 0xc70b, 0x0503, 0x0302, 0x6b43, 0xee53, 0xc822, 0xe812, 0xa923, 0x6713, 0x0403, 0x2503, 0x4703, 0xca13, 0x6d2c, 0x8e34, 0x0a14, 0xa603, 0xe703, 0x0604, 0x060c, 0xe60b, 0xa803, 0x9455, 0x3d8f, 0xfd86, 0x1d8f, 0xfc8e, 0xfd86, 0x5d87, 0xb34d, 0xe703, 0xe603, 0xa903, 0xf765, 0x1d97, 0x1d8f, 0x1b87, 0x3245, 0x5145, 0xae34, 0xb03c, 0xba7e, 0x1c8f, 0xfd8e, 0xdd96, 0x1d8f, 0xb776, 0x4a14, 0xe603, 0x060c, 0xe60b, 0xe50b, 0xe60b, 0x0604, 0xe703, 0xe90b, 0xb25d, 0xf575, 0xea22, 0x4722, 0xac4b, 0xac43, 0x050a, 0xa401, 0xc509, 0x6722, 0x4612, 0x0503, 0xc60b, 0xe603, 0xe70b, 0x670b, 0xe812, 0x2b1b, 0x0b13, 0xa90a, 0xa90a, 0xa90a, 0xaa0a, 0xca0a,
		0xd1bc, 0xb1b4, 0x4fa4, 0x4b8b, 0x476a, 0xa459, 0x4349, 0x2341, 0xe338, 0xc230, 0x2219, 0x4302, 0x6503, 0xc603, 0xa60b, 0xa60b, 0xa70b, 0x460b, 0x4302, 0xc201, 0xa201, 0x450a, 0xe612, 0xe612, 0x0513, 0x4613, 0x250b, 0xc402, 0x0503, 0x4503, 0x6503, 0xa60b, 0xc703, 0xe703, 0x0604, 0x0504, 0x0604, 0xa703, 0x1245, 0x1c87, 0xfd8e, 0xfd8e, 0xfd8e, 0xfd86, 0xdc7e, 0xb034, 0x8803, 0xc903, 0x4e24, 0x7976, 0x1c97, 0xfc8e, 0x3e8f, 0xfc7e, 0x1b7f, 0xda7e, 0xba7e, 0xfc8e, 0x1b8f, 0xfc96, 0xdd96, 0xfd8e, 0xf97e, 0xac24, 0xc503, 0xe50b, 0xe50b, 0xe50b, 0x060c, 0xe50b, 0xe60b, 0xc70b, 0x870b, 0x2703, 0x2402, 0x0512, 0xc409, 0x6612, 0x660a, 0x4502, 0x2402, 0x4502, 0xe612, 0xa60b, 0xe603, 0xe603, 0xc703, 0x670b, 0x2813, 0xe912, 0xa902, 0xaa0a, 0xaa0a, 0xcb0a, 0xcb0a, 0xcb0a,
		0xd1bc, 0xb1b4, 0x4fac, 0x4b8b, 0x466a, 0xa459, 0x4349, 0x2341, 0xe338, 0xc230, 0x2219, 0x030a, 0x2503, 0xc60b, 0xa60b, 0xa60b, 0xa60b, 0xc70b, 0x660b, 0xe50a, 0xa50a, 0xc50a, 0xe502, 0x250b, 0xe40a, 0xa402, 0x060b, 0x2513, 0xc30a, 0xa202, 0x440b, 0xa60b, 0xa70b, 0xc703, 0x0604, 0x0504, 0x0504, 0xc703, 0xaf34, 0xfb7e, 0x1e8f, 0x1e97, 0xfd8e, 0xdd8e, 0xbc7e, 0xb23c, 0xab03, 0x724d, 0xb976, 0x1c8f, 0xfb96, 0xdc96, 0xde8e, 0xde8e, 0xdd86, 0x1d8f, 0x1d8f, 0xdc8e, 0xfb8e, 0xfc96, 0xde96, 0xfe96, 0xfb86, 0xee34, 0xe703, 0xe60b, 0xc613, 0xc713, 0xa60b, 0x850b, 0x2403, 0xc302, 0xa402, 0xa40a, 0xe61a, 0xe61a, 0x2302, 0xe50a, 0x881b, 0x6713, 0x6713, 0xa81b, 0xa713, 0xe60b, 0xc503, 0xe503, 0xc603, 0x870b, 0x0703, 0xc702, 0xc90a, 0xaa0a, 0xab0a, 0xcb0a, 0xcb0a, 0xcb0a,
		0xd1bc, 0xb0b4, 0x4fac, 0x6b93, 0x6772, 0xc559, 0x6451, 0x2349, 0x0339, 0xc330, 0x0221, 0xc311, 0xe50a, 0xa60b, 0xa603, 0xa60b, 0xa70b, 0xc603, 0xc603, 0xa613, 0xa713, 0xa70b, 0x8603, 0xc70b, 0xa713, 0x050b, 0x8502, 0xc40a, 0x2513, 0x0513, 0xa302, 0xe502, 0x880b, 0xa80b, 0xc603, 0xe503, 0xe503, 0xc603, 0x4d24, 0xba7e, 0xfd8e, 0xfe8e, 0xde8e, 0xdd8e, 0x1d8f, 0xbb7e, 0x386e, 0xfb86, 0x1c8f, 0xfc8e, 0xfb96, 0xdc96, 0xde96, 0xde8e, 0xde8e, 0xfd8e, 0xdd8e, 0xfd96, 0xfc8e, 0xdd96, 0xde9e, 0x1e9f, 0xdb86, 0x4d2c, 0x6703, 0x4503, 0xe502, 0xa502, 0xa402, 0xc40a, 0xe512, 0x261b, 0x261b, 0x061b, 0x0613, 0xa302, 0x650b, 0xa613, 0xa60b, 0xc60b, 0xa603, 0xc60b, 0xc603, 0xe503, 0xc503, 0xa503, 0x8503, 0x8703, 0x2703, 0x270b, 0xc80a, 0xaa0a, 0xcb0a, 0xaa0a, 0xaa0a, 0xaa0a,
		0xd0bc, 0x90ac, 0x2fa4, 0x8c93, 0x8872, 0xe561, 0x8451, 0x4449, 0x0341, 0xc330, 0x0321, 0xa319, 0x840a, 0x660b, 0xc603, 0xa703, 0xa70b, 0xc603, 0xc603, 0xa60b, 0xa60b, 0xc603, 0xc603, 0xa603, 0xa70b, 0x8713, 0x4713, 0xc502, 0xa402, 0x0613, 0x2613, 0xc502, 0xc502, 0x2603, 0xa70b, 0xe613, 0xc503, 0xa603, 0xea0b, 0x376e, 0xfc8e, 0xdd8e, 0xfe8e, 0xdd8e, 0xdc8e, 0x1c8f, 0x1c8f, 0xfc8e, 0xdc8e, 0xfd96, 0xfc96, 0xdc96, 0xde96, 0xde96, 0xfd96, 0xfc8e, 0xfc8e, 0xfd8e, 0x1d8f, 0x1d97, 0xfd96, 0x5a86, 0xd14c, 0xc502, 0xc402, 0xa50a, 0xe612, 0x071b, 0x271b, 0x2613, 0x0513, 0xc40a, 0x8402, 0x8402, 0xc402, 0x4403, 0xc60b, 0xc603, 0xc603, 0xc603, 0xc703, 0xa603, 0xa603, 0xa603, 0x8703, 0xca23, 0xad3c, 0x4c2c, 0x4803, 0x6913, 0x2913, 0xaa0a, 0xaa0a, 0xaa0a, 0xaa0a, 0xaa0a,
		0xb0b4, 0x90b4, 0x2fa4, 0xcd9b, 0xc982, 0xe561, 0x8451, 0x4449, 0x0339, 0xc330, 0x0329, 0xa421, 0x6412, 0x660b, 0xa603, 0xc703, 0xa70b, 0xa603, 0xc603, 0xa60b, 0xa60b, 0xa603, 0xc603, 0xa703, 0x870b, 0xa713, 0x860b, 0x8713, 0x2613, 0xa502, 0xa502, 0x0613, 0x050b, 0x8302, 0xc502, 0x650b, 0xa50b, 0xc70b, 0xa903, 0xb55d, 0x1c8f, 0xfd8e, 0xdd8e, 0xdd8e, 0xfc96, 0xfc8e, 0xdd8e, 0xfe96, 0xfe96, 0xdc8e, 0xfd96, 0xdd96, 0xfe96, 0xfd96, 0x1b97, 0x1b8f, 0xfc8e, 0x9c86, 0x3976, 0x755d, 0x9254, 0xac2b, 0x0503, 0x450b, 0x4613, 0xc512, 0xc512, 0xa40a, 0x8302, 0xa302, 0xe402, 0x240b, 0x860b, 0xa70b, 0xa70b, 0xa60b, 0xa603, 0x8603, 0x8603, 0x8703, 0xa903, 0x2c2c, 0xf044, 0x9355, 0x1676, 0x7886, 0x1a8f, 0xd45d, 0x2903, 0x0903, 0x0a13, 0x2b1b, 0xc90a, 0xa902, 0xa902, 0xaa0a,
		0xb0b4, 0xb0ac, 0x6fac, 0x0ea4, 0x0a83, 0x266a, 0xa559, 0x6449, 0x2341, 0xe338, 0x2431, 0xa429, 0x2412, 0x460b, 0xa703, 0xc703, 0xa70b, 0xa60b, 0x860b, 0x8613, 0x8613, 0x870b, 0xa70b, 0x470b, 0x060b, 0xc402, 0x0403, 0x460b, 0x6713, 0x6713, 0xc502, 0xa302, 0x040b, 0x2613, 0xa50a, 0x8302, 0x640b, 0xa60b, 0x8803, 0x324d, 0x1c8f, 0x1d8f, 0xde8e, 0xdc86, 0xdb86, 0xfc8e, 0xfd8e, 0xde96, 0xfe96, 0x1d97, 0xfc8e, 0xdc8e, 0xbc8e, 0x7986, 0x377e, 0x335d, 0x503c, 0x6f1b, 0xcf1b, 0x3034, 0x2b0b, 0xa602, 0xe40a, 0xe202, 0xe302, 0xa402, 0x050b, 0x450b, 0x8613, 0x8613, 0xa613, 0xa60b, 0xa603, 0xa503, 0x8603, 0x8803, 0xea1b, 0x8e34, 0x314d, 0xd565, 0x987e, 0xb986, 0xfb86, 0x3c8f, 0x1d97, 0xfd9e, 0x3d97, 0x1866, 0x6c03, 0xa902, 0xca0a, 0x0a13, 0x4b1b, 0xe912, 0xc90a, 0xc90a,
		0xb0ac, 0xb0ac, 0x90a4, 0x0e9c, 0x4b83, 0x486a, 0xc559, 0x6451, 0x2349, 0x0341, 0x2339, 0x8431, 0xe419, 0x060b, 0xa70b, 0xc60b, 0xa60b, 0xa613, 0x460b, 0x260b, 0x2713, 0x4813, 0xc60a, 0x460a, 0xc401, 0x2933, 0xe722, 0xc50a, 0x6713, 0x870b, 0xa713, 0x250b, 0x8302, 0x840a, 0x0713, 0x0613, 0x8202, 0xc302, 0x0603, 0x8f3c, 0xdc86, 0xfe8e, 0xff8e, 0x1e8f, 0x1c87, 0x3c87, 0x1c8f, 0xfc8e, 0x7a86, 0x387e, 0xb565, 0xf24c, 0x303c, 0x6c1b, 0x2a13, 0x0903, 0x2b03, 0x965d, 0xbb86, 0xdb8e, 0xf775, 0x6a1b, 0x2503, 0x840b, 0xc50b, 0xc70b, 0xc70b, 0xa603, 0x8603, 0x6503, 0x4503, 0xa803, 0x0b24, 0xce3c, 0x9255, 0x1666, 0xb97e, 0x1a87, 0x1b8f, 0x1c8f, 0xfd96, 0xfd96, 0xfe96, 0x1d8f, 0xfd96, 0xdd96, 0x1d97, 0x7976, 0xad13, 0xc902, 0xc90a, 0xca0a, 0x0a13, 0x4b1b, 0x0a13, 0xc90a,
		0x90ac, 0x90a4, 0x70a4, 0x0e9c, 0x6c8b, 0x886a, 0xe659, 0x8551, 0x2349, 0x0341, 0x2339, 0x8431, 0xe419, 0xe612, 0x860b, 0xa603, 0xa60b, 0x6613, 0x6402, 0x440a, 0xc71a, 0x4502, 0x2502, 0x092b, 0xf27c, 0xf695, 0x6a3b, 0x0202, 0x6713, 0xa70b, 0x860b, 0x8613, 0x4613, 0xc402, 0x8402, 0x0513, 0x2513, 0xe40a, 0x6302, 0x491b, 0xb565, 0xfc8e, 0xfc96, 0xba86, 0xb97e, 0x176e, 0x5455, 0x513c, 0xad2b, 0x2913, 0x080b, 0xc802, 0x8802, 0x880a, 0x2502, 0x2402, 0x9044, 0x1b8f, 0x1c8f, 0x1d8f, 0x1b8f, 0x8f3c, 0x8603, 0xc50b, 0xc503, 0xc703, 0xa803, 0xca0b, 0x2c2c, 0x104d, 0x9365, 0x3676, 0xd986, 0x1a87, 0x3b8f, 0x3b8f, 0x1b8f, 0x1c8f, 0xfc8e, 0xdd8e, 0xdd96, 0xdd96, 0xfd96, 0x1c97, 0xfc96, 0xdc96, 0x1c97, 0xba7e, 0x0e2c, 0xc802, 0xc90a, 0xca0a, 0xa90a, 0x0a13, 0x2b1b, 0x0a13,
		0x6fac, 0x70a4, 0x70a4, 0x2f9c, 0x8c8b, 0xa972, 0xe659, 0x8551, 0x0341, 0x0239, 0xe230, 0x4329, 0xc319, 0xa50a, 0x660b, 0x8603, 0xa60b, 0xe50a, 0x240a, 0x082b, 0xec4b, 0xe82a, 0xa301, 0xc932, 0x548d, 0x548d, 0x2933, 0x2402, 0x260b, 0xa60b, 0xa603, 0x8503, 0x850b, 0x8613, 0x250b, 0xc402, 0xc502, 0x260b, 0x0713, 0x6502, 0xe812, 0x4e44, 0xd154, 0x4e44, 0x8c1b, 0xef2b, 0xb34c, 0x9244, 0x290b, 0xa502, 0x4402, 0x250a, 0x4b3b, 0xed4b, 0x4a3b, 0x2402, 0xb04c, 0xfb8e, 0x1d8f, 0x1d8f, 0x9976, 0xed23, 0x8703, 0xa503, 0xc503, 0xa603, 0x514d, 0x9876, 0xb986, 0xfb8e, 0xfc8e, 0x1c97, 0xfd96, 0xfd8e, 0x1d8f, 0xfc8e, 0xfc8e, 0xfd96, 0xfd96, 0xdd96, 0xdd96, 0xdd96, 0xfd96, 0x1b97, 0xfb96, 0xdc9e, 0xfb96, 0x1b8f, 0xb144, 0xc802, 0xc90a, 0xca0a, 0xca0a, 0xca0a, 0xe90a, 0x4b1b,
		0x6fac, 0x70a4, 0x4fa4, 0x0e9c, 0x8c8b, 0xa972, 0xe659, 0x6449, 0x0341, 0xe238, 0xc230, 0x0329, 0x8319, 0x650a, 0x470b, 0x860b, 0xa60b, 0xa402, 0x240a, 0x0833, 0x8a43, 0x461a, 0xe401, 0x8301, 0x8401, 0xc511, 0xc401, 0x2402, 0x460b, 0xa60b, 0xa503, 0xa503, 0xc503, 0x8503, 0x8513, 0x660b, 0x0503, 0xa502, 0xe60a, 0x0613, 0x261b, 0xc40a, 0xe502, 0x8502, 0xf254, 0x9b86, 0xdd8e, 0xfc8e, 0x735d, 0x260b, 0x2402, 0xa82a, 0xad4b, 0xf27c, 0xd16c, 0x260a, 0xea1a, 0x9665, 0xfc8e, 0xfc8e, 0x9a7e, 0xd13c, 0xa803, 0xa603, 0xa503, 0x8503, 0xd45d, 0x3c8f, 0xfc8e, 0xfd96, 0xdd96, 0xdd96, 0xde96, 0xde96, 0xdd8e, 0xdd96, 0xdd96, 0xdd96, 0xdd96, 0xbd96, 0xdd96, 0xdd9e, 0xfd96, 0x1c97, 0xfc9e, 0xdc9e, 0xdc96, 0x1c8f, 0x334d, 0xc902, 0xc90a, 0xa90a, 0xca0a, 0xca0a, 0xc90a, 0xea0a,
		0x4fa4, 0x2fa4, 0x0e9c, 0xce93, 0x6c8b, 0xa972, 0xe659, 0x6449, 0x0341, 0xe230, 0xc230, 0xe228, 0x4319, 0x2412, 0x4713, 0x870b, 0x860b, 0x260b, 0x0202, 0x0302, 0xe301, 0x2402, 0x8502, 0x4502, 0x0402, 0x450a, 0x8612, 0xe60a, 0x8713, 0xa603, 0xa503, 0xc503, 0xc503, 0xa503, 0x8503, 0x860b, 0x870b, 0x470b, 0xa502, 0x8302, 0xc40a, 0xa302, 0x8302, 0xe70a, 0x587e, 0xfe96, 0xff96, 0xfe8e, 0x5776, 0x8813, 0x2402, 0x0a33, 0x2c43, 0x506c, 0xee53, 0x260a, 0x8902, 0x765d, 0xfd8e, 0xfd8e, 0x1c87, 0x576e, 0xc903, 0xa603, 0xa603, 0x8503, 0x114d, 0xda86, 0xfc8e, 0xfd96, 0xdd96, 0xbd96, 0xdd96, 0xdd96, 0xdd96, 0xde96, 0xde96, 0xde96, 0xdd96, 0xdd96, 0xdd96, 0xdd96, 0xdd96, 0xfd8e, 0xdd96, 0xfd9e, 0xfd96, 0xfc8e, 0x965d, 0xca02, 0xca0a, 0xaa0a, 0xaa0a, 0xaa0a, 0xa90a, 0xa90a,
		0xee9b, 0xce9b, 0xcd93, 0x8c8b, 0x2b83, 0x686a, 0xc551, 0x4449, 0x2339, 0xe230, 0xa228, 0xc228, 0x2319, 0xe411, 0x0613, 0x860b, 0xa60b, 0xa70b, 0xe502, 0x6302, 0x2302, 0xe60a, 0x670b, 0x470b, 0x270b, 0x681b, 0x681b, 0x8713, 0xa60b, 0x8503, 0xa503, 0xa603, 0xa603, 0xa603, 0xa603, 0xa60b, 0x860b, 0x870b, 0x870b, 0x260b, 0x0403, 0x250b, 0x460b, 0xaa1b, 0x166e, 0xfe96, 0xff96, 0xfe8e, 0x5555, 0x2803, 0x2402, 0x0612, 0xe611, 0xa501, 0xe509, 0x8301, 0x0a13, 0x1766, 0xfd8e, 0xdd8e, 0x1d8f, 0x1766, 0xa903, 0xa703, 0xa603, 0x6503, 0x8e3c, 0xfa8e, 0x1c97, 0xdc96, 0xdd96, 0xdd96, 0xdd96, 0xdd96, 0xdd96, 0xdd96, 0xbd96, 0xbd96, 0xdd96, 0xdd96, 0xdd96, 0xfd96, 0xfd96, 0xfd8e, 0xdd96, 0xfe9e, 0x1d97, 0x3c8f, 0x376e, 0x0a03, 0xa802, 0xaa0a, 0xaa0a, 0xaa0a, 0xaa0a, 0xa902,
		0x6c8b, 0x6c8b, 0x6c8b, 0x2b83, 0xca72, 0x2762, 0x8449, 0x2341, 0xe230, 0xc228, 0x8128, 0x8220, 0xe218, 0xa311, 0xa50a, 0x660b, 0xa60b, 0xa60b, 0x870b, 0x4613, 0x2613, 0x6713, 0x870b, 0xa703, 0x870b, 0x870b, 0x860b, 0xa60b, 0xa603, 0xa503, 0xa603, 0xa603, 0x860b, 0x870b, 0xa603, 0xa603, 0xa603, 0xa50b, 0x860b, 0x860b, 0x870b, 0x870b, 0xa70b, 0x4603, 0x2d2c, 0x7a7e, 0xfe8e, 0x1e8f, 0x386e, 0x4d2c, 0xc602, 0x0302, 0x8301, 0x8301, 0x8101, 0x850a, 0x480b, 0xaf34, 0x7a7e, 0xfe96, 0x1d8f, 0xb65d, 0xaa03, 0x8703, 0x8603, 0x4503, 0xec23, 0xb97e, 0x1c97, 0xfd96, 0xde96, 0xbe96, 0xdd96, 0xdd8e, 0xdc8e, 0xdc96, 0xdc96, 0xdd96, 0xdd96, 0xfd96, 0xfd96, 0xfd96, 0xfd8e, 0x1d8f, 0x1d97, 0xfc96, 0xdb86, 0xb976, 0x9355, 0x4803, 0xe702, 0xa90a, 0xaa0a, 0xaa0a, 0xaa0a, 0xa90a,
		0x0a83, 0x0a83, 0x0a7b, 0xea7a, 0x686a, 0xe659, 0x4341, 0xc130, 0x8028, 0x8120, 0x6120, 0x6120, 0x8118, 0x8311, 0x850a, 0x660b, 0xa60b, 0x8603, 0x660b, 0x6613, 0x6613, 0x660b, 0x860b, 0xa603, 0x8603, 0xa603, 0xa603, 0xa503, 0xa503, 0xa503, 0xa603, 0x860b, 0x670b, 0x870b, 0xa603, 0xa603, 0xa503, 0xa503, 0x8503, 0x8603, 0x8703, 0x6703, 0xa603, 0x8603, 0x6d34, 0xda86, 0xfc8e, 0xfd8e, 0x1b87, 0x314d, 0x2503, 0xe502, 0x6402, 0x640a, 0xc412, 0x4513, 0x860b, 0x0a0c, 0x597e, 0xdd96, 0xfd8e, 0xfb7e, 0xf03c, 0x6703, 0x870b, 0x6603, 0x8a13, 0x5876, 0x1c8f, 0xfe96, 0xbe96, 0xbe96, 0xde96, 0xdd8e, 0xfc96, 0xfc96, 0xfc96, 0xfc96, 0xfd96, 0xfd8e, 0xfd8e, 0xfd8e, 0xfc86, 0x9976, 0xd665, 0x1355, 0x6f3c, 0xeb13, 0xa903, 0x4703, 0xe702, 0xaa0a, 0xaa0a, 0xca0a, 0xc90a, 0xc90a,
		0x0e9c, 0x0e9c, 0xed93, 0xed93, 0x8c8b, 0x2a7b, 0xc972, 0x275a, 0xa549, 0x6339, 0x4341, 0x0441, 0x2439, 0xa421, 0x650a, 0x260b, 0x660b, 0x660b, 0x660b, 0x660b, 0x660b, 0x860b, 0x860b, 0x8503, 0x8503, 0xa503, 0xa503, 0xa503, 0x8603, 0x8603, 0x660b, 0x660b, 0x660b, 0x650b, 0xa503, 0xa603, 0xa603, 0x860b, 0x850b, 0x850b, 0x870b, 0x6703, 0x6603, 0x6703, 0xaf3c, 0x1a87, 0xfc8e, 0xfc8e, 0xda86, 0x9034, 0x2503, 0x870b, 0x680b, 0x8813, 0x870b, 0x860b, 0x8603, 0x6b2c, 0xfa86, 0x1d8f, 0xfc8e, 0xfc8e, 0xd24c, 0x0803, 0x8703, 0xa603, 0xa703, 0xf45d, 0x1c8f, 0xde96, 0xbf96, 0xbd96, 0xdc96, 0xfb8e, 0xfb8e, 0x1c97, 0x1c97, 0xdb8e, 0xbb86, 0x5976, 0xd665, 0x3355, 0x6f34, 0xaa1b, 0x6803, 0x6703, 0x6503, 0x8403, 0x8603, 0x8803, 0xe902, 0x8b0a, 0xca0a, 0xe702, 0x0703, 0xe802,
		0x90ac, 0x90ac, 0x90ac, 0x90ac, 0x6fa4, 0x6fa4, 0x2f9c, 0xac8b, 0xea72, 0x475a, 0xc559, 0x8559, 0x8549, 0xe531, 0x240a, 0x260b, 0x660b, 0x660b, 0x660b, 0x660b, 0x660b, 0x860b, 0x850b, 0x850b, 0x850b, 0x850b, 0x850b, 0x850b, 0x8603, 0x6603, 0x6603, 0x8603, 0x8603, 0x8503, 0x650b, 0x4603, 0x8813, 0x8713, 0x650b, 0x650b, 0x860b, 0x870b, 0x660b, 0xa80b, 0xab0b, 0xb55d, 0xdb8e, 0x1d97, 0xdb86, 0x1245, 0x8803, 0x6703, 0x8803, 0x870b, 0xa60b, 0xa60b, 0x8603, 0xea1b, 0x376e, 0x1d8f, 0xfd96, 0xfd96, 0x1876, 0x134d, 0x0c1c, 0x6703, 0x6703, 0x514d, 0x3b8f, 0xdd8e, 0xdd96, 0xfc96, 0x1b97, 0x1a87, 0xd986, 0x577e, 0xb565, 0xf24c, 0x2e34, 0xab13, 0x4803, 0x2603, 0x4703, 0x6803, 0x8703, 0x8603, 0x840b, 0x830b, 0x850b, 0x470b, 0xc802, 0xc802, 0xca0a, 0xab02, 0xab02, 0xa902,
		0xf2b4, 0x12b5, 0x12b5, 0xd1b4, 0xd1ac, 0xf1b4, 0xb0ac, 0x4f9c, 0xcd8b, 0xe972, 0x066a, 0xc669, 0xc559, 0xe539, 0x2412, 0xe50a, 0x660b, 0x650b, 0x660b, 0x660b, 0x650b, 0x650b, 0x650b, 0x650b, 0x650b, 0x650b, 0x650b, 0x650b, 0x660b, 0x6603, 0x8603, 0x8603, 0x8603, 0x860b, 0x2613, 0x8502, 0xa602, 0x2713, 0x4613, 0x650b, 0x660b, 0x870b, 0x850b, 0x8703, 0x4803, 0x3355, 0xfc96, 0xfc96, 0xfc8e, 0x996e, 0x0b1c, 0x4703, 0x8703, 0x8503, 0xa403, 0x850b, 0x670b, 0x2903, 0x765d, 0xfd96, 0xdd96, 0xde96, 0xdd96, 0xfc8e, 0x376e, 0x6f2c, 0x0703, 0xcf3c, 0x1a87, 0xfa8e, 0xd986, 0x5676, 0xb35d, 0xf144, 0x2d2c, 0xaa03, 0x4803, 0x2703, 0x2603, 0x6703, 0x860b, 0x850b, 0x6503, 0x8603, 0x6603, 0x6603, 0x860b, 0x6513, 0x6513, 0xc40a, 0xe60a, 0xc602, 0xca0a, 0xad12, 0x6b0a, 0x482b,
		0x33bd, 0x33bd, 0x33bd, 0xf2b4, 0x12b5, 0xf2b4, 0xf1ac, 0xd1ac, 0x6fa4, 0x6b8b, 0x887a, 0x2772, 0xe661, 0xe441, 0x2422, 0xa40a, 0x450b, 0x6503, 0x660b, 0x660b, 0x660b, 0x650b, 0x650b, 0x650b, 0x650b, 0x650b, 0x6503, 0x660b, 0x660b, 0x460b, 0x670b, 0x660b, 0x660b, 0x2613, 0x0402, 0xc92a, 0x0e4c, 0xa822, 0x6402, 0x050b, 0x660b, 0x860b, 0x850b, 0x6603, 0x6803, 0xf665, 0xfc96, 0xdc96, 0x1d8f, 0x7976, 0xcb13, 0x4703, 0x8703, 0x8403, 0xa303, 0x840b, 0x4703, 0xd24c, 0xbc8e, 0xdd96, 0xde96, 0xde9e, 0xdd96, 0xdc8e, 0x1c8f, 0x176e, 0xab0b, 0x2c24, 0x524d, 0xaf3c, 0x0b24, 0x880b, 0x4703, 0x2803, 0x4903, 0x8803, 0x8803, 0x6b24, 0x0a24, 0x6603, 0x6503, 0x840b, 0x630b, 0x830b, 0x650b, 0x470b, 0x0703, 0xe60a, 0xc50a, 0xa50a, 0xc70a, 0xca02, 0xc90a, 0x8702, 0xa63b, 0x2a6d,
		0x53bd, 0x53bd, 0x33bd, 0x53bd, 0x33bd, 0x12b5, 0xf2b4, 0xf2b4, 0xd1ac, 0x0ea4, 0xc982, 0x6772, 0x0662, 0xc449, 0xe329, 0x8412, 0x660b, 0x8603, 0x6603, 0x860b, 0x6603, 0x6603, 0x860b, 0x660b, 0x4603, 0x6603, 0xa603, 0x6603, 0x2603, 0x4813, 0x0713, 0x8402, 0x4202, 0x0302, 0x461a, 0x958d, 0x5cc7, 0x337d, 0xe101, 0xc40a, 0x250b, 0x660b, 0x8503, 0x6603, 0x4803, 0xd244, 0xbb8e, 0xdd96, 0x1d97, 0x5976, 0xd144, 0xcb13, 0x4703, 0x8503, 0xa403, 0x6503, 0xab1b, 0x597e, 0xfd96, 0xdd96, 0xdd96, 0xfe9e, 0xfd96, 0xdc8e, 0x1c8f, 0x1c8f, 0xd13c, 0x4903, 0x2803, 0x2703, 0x4603, 0x6603, 0xa803, 0x4d24, 0x0c1c, 0x6d24, 0x6d24, 0x5045, 0x0f3d, 0x680b, 0x660b, 0x450b, 0x240b, 0xe30a, 0xa40a, 0x0613, 0x061b, 0xa502, 0xa702, 0xca0a, 0xab02, 0xab0a, 0xc602, 0x043c, 0xc975, 0x496d,
		0x54bd, 0x74bd, 0x53bd, 0x74bd, 0x53bd, 0x53bd, 0x33bd, 0x33b5, 0x12b5, 0x70ac, 0x4c8b, 0xa872, 0x4662, 0xe451, 0xe331, 0x641a, 0x460b, 0x6603, 0x870b, 0x6603, 0x460b, 0x6713, 0x6713, 0x4713, 0x260b, 0xa813, 0x870b, 0x0603, 0xe602, 0xa60a, 0xe401, 0xac53, 0x5285, 0x6732, 0xe932, 0x9695, 0x7dd7, 0x9695, 0x0402, 0x6302, 0x050b, 0x460b, 0x6503, 0x8703, 0x8a03, 0x755d, 0xdd96, 0xdd9e, 0xdd8e, 0xfc8e, 0xfb8e, 0x176e, 0x2d2c, 0x4603, 0x8503, 0x6503, 0xd044, 0xfb8e, 0xfd8e, 0xfd8e, 0x3d97, 0x1c8f, 0xfc8e, 0xba86, 0x5876, 0xd665, 0x6e2c, 0x8903, 0x8a0b, 0x2c24, 0x6c2c, 0x6b24, 0xca13, 0xf034, 0xb02c, 0x5245, 0x5245, 0x3245, 0x8f34, 0x0803, 0xa602, 0x8502, 0x6602, 0x4812, 0x4602, 0x293c, 0x4a5d, 0xc42b, 0xc502, 0x8b0a, 0x8d0a, 0xc80a, 0x0744, 0xca75, 0x2865, 0x462b,
		0x54bd, 0x54bd, 0x54bd, 0x74bd, 0x54bd, 0x54bd, 0x33bd, 0x33b5, 0x12b5, 0xb2b4, 0xee93, 0x0a73, 0x6762, 0xe551, 0xe439, 0x441a, 0x060b, 0x260b, 0xc502, 0x6402, 0xc502, 0xe712, 0x0713, 0xc602, 0x6502, 0xc71a, 0x0302, 0x2e54, 0x3275, 0x882a, 0x2712, 0xb595, 0x7ccf, 0x2e6c, 0x461a, 0x8d53, 0xf484, 0x306c, 0x261a, 0xe201, 0xc502, 0x2603, 0x870b, 0x6803, 0x734d, 0xfc8e, 0xdd96, 0xbd96, 0xdd96, 0xfd8e, 0xdc96, 0xfc96, 0xf665, 0xcb0b, 0x6703, 0x4603, 0x514d, 0x5c8f, 0xfb86, 0xba7e, 0x586e, 0x955d, 0xd144, 0x0d24, 0xab0b, 0x4903, 0xca0b, 0xee34, 0x6e24, 0xb02c, 0xb034, 0x103d, 0x0d24, 0xb034, 0x903c, 0x4f34, 0xcd23, 0x4b13, 0xa902, 0x8902, 0x8802, 0x8702, 0xa90a, 0x6a0a, 0xa80a, 0x061b, 0xa84c, 0x4a65, 0xe63b, 0x860a, 0x8712, 0x2754, 0xac75, 0xca54, 0x271b, 0xa802,
		0x74bd, 0x53bd, 0x53bd, 0x74bd, 0x74bd, 0x74bd, 0x53bd, 0x53bd, 0x13b5, 0xf2b4, 0x909c, 0x6c7b, 0x8862, 0x065a, 0xe541, 0x241a, 0xe60a, 0xc602, 0x650a, 0x6933, 0xab3b, 0x250a, 0xe92a, 0xf174, 0x77a6, 0x906c, 0x0001, 0x9495, 0x3bbf, 0xef5b, 0x070a, 0x5485, 0xb9ae, 0x4e64, 0xe209, 0x472a, 0x516c, 0x4d53, 0xc511, 0xc201, 0x8402, 0x2603, 0x4703, 0x6e2c, 0x1a7f, 0xfd8e, 0xbd96, 0xbd96, 0xdd96, 0xfd96, 0xdd9e, 0xfd96, 0xdb86, 0xd13c, 0x2703, 0x4703, 0xcf3c, 0xd565, 0xd244, 0x2f24, 0xac03, 0x4e1c, 0x4d1c, 0x4c1c, 0xce2c, 0x6803, 0x880b, 0xce34, 0xb02c, 0xb234, 0x7134, 0x4f2c, 0x4f34, 0xad23, 0x2b1b, 0x6802, 0x6802, 0x8902, 0x8a0a, 0x8a0a, 0x890a, 0x890a, 0xa902, 0xa802, 0xca02, 0x8902, 0xc712, 0x4954, 0x2975, 0xe253, 0x6464, 0x6a85, 0x695c, 0xa712, 0xc902, 0xe902,
		0x74c5, 0x74c5, 0x74c5, 0x74c5, 0x74c5, 0x74bd, 0x54bd, 0x33bd, 0x33b5, 0x13b5, 0xf2ac, 0xcd8b, 0xc972, 0x2662, 0x054a, 0x242a, 0x840a, 0x4302, 0xe82a, 0x9485, 0x57a6, 0xad53, 0xc932, 0x57a6, 0x9dcf, 0xd27c, 0xa301, 0x916c, 0x958d, 0x8d4b, 0xa609, 0xca32, 0xea3a, 0xc832, 0xa201, 0x462a, 0x6832, 0x0622, 0xa411, 0x0402, 0xe60a, 0x6603, 0x6503, 0xb455, 0xfe8e, 0xbf96, 0xbe96, 0xdd9e, 0x1c97, 0x3d8f, 0xdb8e, 0x9a86, 0x176e, 0x6f34, 0x6903, 0xa90b, 0xa903, 0x8d24, 0x0d1c, 0xd034, 0xb12c, 0x1235, 0xd12c, 0x3135, 0xb245, 0xeb1b, 0xe702, 0xcc2b, 0xee33, 0x0b1b, 0xeb1a, 0x4802, 0x8902, 0x8902, 0x8802, 0x8802, 0x890a, 0x690a, 0x6b0a, 0x6c0a, 0x6b0a, 0x8a0a, 0x890a, 0x8a02, 0x6b02, 0x8b0a, 0x870a, 0x800a, 0x6564, 0xa995, 0x8a95, 0x0664, 0x650a, 0xa902, 0xea02, 0x2803,
		0x74c5, 0x74c5, 0x74bd, 0x74bd, 0x74c5, 0x54bd, 0x54bd, 0x33bd, 0x33bd, 0x33b5, 0xf2ac, 0x4f9c, 0x2a83, 0x466a, 0x2552, 0x2432, 0x440a, 0x2302, 0x2d5c, 0xdab6, 0x3cc7, 0xb27c, 0x4722, 0x4f6c, 0x3385, 0x4c4b, 0x8301, 0x271a, 0xa92a, 0x271a, 0x6401, 0x8401, 0x8309, 0xc411, 0x4201, 0x6309, 0x8311, 0x8311, 0xa309, 0xa512, 0x4613, 0x4503, 0x6503, 0xf565, 0x1d97, 0xfd96, 0xbb96, 0x587e, 0xf66d, 0x334d, 0x6f34, 0xac1b, 0xab03, 0x6e1c, 0x6e1c, 0x313d, 0xf034, 0x5245, 0x4e24, 0x5245, 0x944d, 0xd234, 0xb23c, 0x0e2c, 0x6b1b, 0xa70a, 0xe501, 0xc501, 0x6401, 0xe200, 0x2401, 0xe709, 0x4802, 0x8902, 0x8902, 0x6902, 0x890a, 0x890a, 0x8a0a, 0x6b0a, 0x8a0a, 0x890a, 0xa80a, 0xa802, 0xaa0a, 0xca12, 0x8602, 0x432b, 0x276d, 0xc78d, 0xa78d, 0x475c, 0xc51a, 0xa902, 0xeb02, 0xea02,
		0x74c5, 0x74c5, 0x74c5, 0x74c5, 0x74c5, 0x74c5, 0x53bd, 0x33bd, 0x33bd, 0x33b5, 0xf2ac, 0xb0ac, 0x8c8b, 0x676a, 0x465a, 0x4532, 0x4412, 0x240a, 0xab4b, 0xb174, 0xd37c, 0xae5b, 0xa519, 0xc519, 0x4822, 0x4722, 0xa411, 0x4201, 0x6301, 0xa401, 0xa301, 0xc301, 0xa209, 0xc309, 0x0512, 0xa401, 0x8301, 0xa309, 0x230a, 0x0513, 0x440b, 0x6403, 0x4713, 0x515d, 0xd56d, 0xf154, 0x2d34, 0xa913, 0x4703, 0x2803, 0xaa03, 0xef24, 0xaf1c, 0x723d, 0xf12c, 0x754d, 0xf444, 0xd344, 0x2f34, 0xcc23, 0x8c23, 0xeb1a, 0x8a1a, 0x4401, 0xe300, 0x6000, 0xc100, 0x8000, 0x8100, 0xa200, 0xc300, 0xa609, 0x2912, 0x690a, 0x6a02, 0x6a0a, 0x890a, 0x880a, 0xa80a, 0xa90a, 0xa90a, 0xa80a, 0xa702, 0xc90a, 0xe80a, 0xa602, 0x672b, 0x2c65, 0xab75, 0x013c, 0x6354, 0x4a6d, 0x6a4c, 0xe80a, 0xaa02, 0xab0a,
		0x74c5, 0x74c5, 0x74c5, 0x74c5, 0x74c5, 0x74c5, 0x54c5, 0x53bd, 0x33bd, 0x33b5, 0x12b5, 0xd1ac, 0xed9b, 0xc97a, 0x465a, 0x253a, 0x441a, 0x2412, 0x4622, 0x6c4b, 0xef5b, 0xeb42, 0x8411, 0x8309, 0xa511, 0xc511, 0xa309, 0xa301, 0x240a, 0x4402, 0x850a, 0xc512, 0xa40a, 0xe61a, 0xc612, 0xa612, 0x650a, 0xa60a, 0xe60a, 0x460b, 0x6503, 0x6603, 0x280b, 0xaa1b, 0x2703, 0x4503, 0x4403, 0x4503, 0x4703, 0x2803, 0x0c1c, 0x924d, 0x3145, 0xb03c, 0x4c1b, 0xef33, 0xec22, 0x4e33, 0x0b33, 0xa401, 0xe200, 0xa200, 0x2100, 0x4100, 0x2108, 0x2108, 0x4008, 0x6000, 0xa108, 0xa100, 0xc200, 0xc711, 0x2812, 0x490a, 0x4a0a, 0x6a0a, 0x880a, 0xa702, 0xa702, 0xa802, 0xa90a, 0xa90a, 0x8a0a, 0x8b0a, 0xa602, 0xc533, 0x6b6d, 0x4d6d, 0xa833, 0xa402, 0xa302, 0xe73b, 0x4c65, 0xab4c, 0xe712, 0x8a12,
		0x53bd, 0x33bd, 0x53c5, 0x53c5, 0x54c5, 0x53c5, 0x53c5, 0x33bd, 0x33bd, 0x13b5, 0xf2ac, 0xb1ac, 0x0e9c, 0xe97a, 0x4762, 0x4542, 0x4522, 0x2412, 0xe409, 0x892a, 0xaa32, 0x2722, 0x6309, 0x8201, 0xa401, 0xc401, 0x2302, 0x850a, 0x0613, 0x050b, 0x460b, 0x460b, 0x450b, 0x650b, 0x4503, 0x460b, 0x2703, 0x4803, 0x6803, 0x6803, 0xea0b, 0x2c14, 0xb02c, 0xef34, 0x8703, 0x8603, 0xe81b, 0xac3c, 0xca33, 0xa712, 0x4a23, 0x0e44, 0x4b33, 0x471a, 0xa519, 0xa521, 0xa529, 0x8529, 0x6529, 0x8210, 0x2100, 0x4100, 0x4100, 0x4100, 0x6108, 0x4108, 0x6000, 0x8000, 0xa100, 0x0301, 0x6509, 0xe709, 0x480a, 0x6902, 0x6a0a, 0x6a0a, 0x880a, 0xa702, 0xa802, 0xaa0a, 0x8a02, 0x8b0a, 0x8a0a, 0x680a, 0xa63b, 0x8975, 0x4975, 0x4433, 0x6512, 0x082b, 0x0723, 0x8412, 0x8533, 0x6a65, 0xc954, 0x0723,
		0x33bd, 0x32bd, 0x33bd, 0x33bd, 0x53bd, 0x53bd, 0x33bd, 0x32bd, 0x12bd, 0x33b5, 0x13b5, 0xf1ac, 0x6fac, 0x2b8b, 0x676a, 0x464a, 0x242a, 0x2412, 0x040a, 0xa401, 0x8401, 0x8301, 0xc301, 0x6412, 0x650a, 0x6402, 0x8402, 0x0503, 0x4503, 0x6503, 0x6503, 0x6503, 0x8603, 0x4503, 0x8503, 0x8603, 0xc903, 0xcb0b, 0x1135, 0x4e24, 0xf134, 0x4f24, 0xf234, 0xd034, 0x4703, 0x060b, 0x271b, 0x292b, 0x2622, 0xa419, 0xc621, 0x6521, 0x6429, 0x8431, 0xc541, 0xa441, 0xc349, 0xc449, 0x8539, 0x4110, 0x2000, 0x4100, 0x6100, 0x8100, 0xa200, 0xa200, 0xe200, 0x6301, 0x6401, 0xc509, 0xa91a, 0xa91a, 0x6802, 0x6802, 0x890a, 0x690a, 0x880a, 0xa802, 0xa90a, 0x8a0a, 0x8b0a, 0x6a0a, 0x660a, 0x444c, 0xa975, 0x086d, 0x4233, 0xa322, 0xc74b, 0x4a75, 0x6a7d, 0xe84b, 0xa00a, 0xa333, 0x2965, 0x0b6d,
		0x32bd, 0x32bd, 0x32bd, 0x33bd, 0x33bd, 0x33bd, 0x32bd, 0x12bd, 0x12bd, 0x13b5, 0x12ad, 0xf1ac, 0x90ac, 0x8c93, 0x676a, 0x264a, 0x0432, 0x641a, 0x840a, 0xe401, 0xc401, 0x2402, 0xa412, 0xe512, 0xe50a, 0xe50a, 0xe402, 0x0403, 0x4403, 0x4403, 0x6503, 0x8603, 0x4603, 0x0a1c, 0x303d, 0x2c1c, 0x313d, 0x113d, 0xd134, 0xb13c, 0x913c, 0xb24c, 0x9144, 0x4e44, 0xc722, 0xe319, 0x8421, 0x4421, 0x8429, 0xc431, 0xa541, 0xc649, 0x0652, 0x275a, 0x4762, 0x6762, 0x8762, 0x465a, 0x8531, 0x2100, 0x6100, 0xa200, 0xe200, 0x2301, 0x6501, 0x8609, 0xe609, 0x070a, 0x270a, 0x270a, 0x8812, 0x2b23, 0xea1a, 0x880a, 0x4802, 0x690a, 0x890a, 0xa90a, 0xaa0a, 0xaa0a, 0x8812, 0x6512, 0x6754, 0xa875, 0xe85c, 0xe51a, 0xa50a, 0x8633, 0x897d, 0x657d, 0x858d, 0x4885, 0xa443, 0xc01a, 0x632b, 0x0a65,
		0x33bd, 0x12bd, 0x12bd, 0x12bd, 0x12bd, 0x12bd, 0x12bd, 0xf2bc, 0x12bd, 0x12b5, 0xf2ac, 0xb1ac, 0x6fac, 0xcd9b, 0x8872, 0x4652, 0x0532, 0x4312, 0xe512, 0xc612, 0xa60a, 0x0613, 0x4513, 0x240b, 0x450b, 0x250b, 0x040b, 0x240b, 0x440b, 0x4403, 0x4503, 0x670b, 0x0603, 0x4e34, 0xb555, 0x1345, 0x754d, 0x1345, 0xb244, 0xee33, 0xca1a, 0x0b33, 0x0822, 0x262a, 0xe439, 0x8441, 0x6649, 0xa749, 0x275a, 0xc762, 0xe972, 0x0973, 0x0a7b, 0x2b7b, 0x4c83, 0x4c7b, 0x4c73, 0xea5a, 0xc629, 0x2301, 0x6401, 0x8401, 0xc601, 0xe609, 0x070a, 0x0812, 0x280a, 0x2802, 0x480a, 0x690a, 0x480a, 0x8912, 0x2b23, 0xc91a, 0x690a, 0x6a0a, 0x8a0a, 0x8a02, 0x890a, 0x870a, 0xc41a, 0x875c, 0xaa7d, 0x6954, 0xe812, 0xaa02, 0xa902, 0x8623, 0xa875, 0xa585, 0x8395, 0xc595, 0xaa8d, 0x8a5c, 0xc51a, 0x0423,
		0x12bd, 0xf2b4, 0xf2bc, 0xf2bc, 0x12bd, 0x12bd, 0x12bd, 0x12bd, 0x12bd, 0x13bd, 0xd2b4, 0xb1ac, 0x90ac, 0x0e9c, 0x097b, 0x465a, 0x054a, 0x031a, 0xe50a, 0x260b, 0x060b, 0x260b, 0x250b, 0x2503, 0x4603, 0x250b, 0x0513, 0x2513, 0x250b, 0x250b, 0x260b, 0x460b, 0x0603, 0xcb23, 0xd244, 0x0f34, 0xeb1a, 0x691a, 0x682a, 0xe629, 0x8429, 0xa539, 0xe749, 0x275a, 0x4862, 0xa972, 0x0b7b, 0x2c83, 0x8d8b, 0xed8b, 0xab93, 0x8c93, 0xad93, 0xce8b, 0xcd8b, 0x8c83, 0x6c6b, 0xeb52, 0x071a, 0xe701, 0x070a, 0x270a, 0x480a, 0x480a, 0x480a, 0x480a, 0x490a, 0x490a, 0x680a, 0x870a, 0x890a, 0x6a0a, 0xaa12, 0x4a23, 0x091b, 0x890a, 0x8b0a, 0x6b02, 0x8802, 0x4523, 0xc864, 0x8a7d, 0x0854, 0xa90a, 0xa90a, 0xaa02, 0xca0a, 0xc80a, 0x0744, 0x467d, 0x059e, 0x8074, 0x267d, 0xec85, 0x672b, 0xa70a,
		0x13bd, 0xf2bc, 0xf2bc, 0x12bd, 0x12bd, 0x12bd, 0xf2bc, 0x12bd, 0xf2bc, 0xd2bc, 0xb2b4, 0xb1ac, 0xb1ac, 0x4fa4, 0x4a7b, 0x465a, 0xe451, 0x032a, 0xa50a, 0x050b, 0x2603, 0x2503, 0x260b, 0x260b, 0x4603, 0x4503, 0x450b, 0x250b, 0xe512, 0xa512, 0x8512, 0x4412, 0x0412, 0x0522, 0x682a, 0xe621, 0xc639, 0xc641, 0xc651, 0x075a, 0x6972, 0xca7a, 0x2c83, 0x6d8b, 0x8d8b, 0xce93, 0x0f9c, 0x2f9c, 0x0f9c, 0x2f9c, 0x0e9c, 0xce9b, 0xef93, 0xee93, 0xee93, 0x8c83, 0x2b6b, 0x8942, 0x070a, 0x2802, 0x480a, 0x480a, 0x690a, 0x690a, 0x690a, 0x690a, 0x690a, 0x690a, 0x690a, 0x890a, 0x6902, 0x890a, 0x880a, 0xc812, 0x4a1b, 0xe90a, 0x8a0a, 0x4802, 0x262b, 0x0a6d, 0x8b75, 0xe74b, 0xa71a, 0x890a, 0xc80a, 0xc80a, 0xaa0a, 0x8a0a, 0x8812, 0x843b, 0xa885, 0x6785, 0xa885, 0x896d, 0x461b, 0xca02,
		0x13bd, 0x12bd, 0xf2bc, 0xf2bc, 0xf2b4, 0xf2bc, 0xd2b4, 0xf2bc, 0xf2bc, 0xd2b4, 0xb2b4, 0xb1ac, 0xb1b4, 0x4fa4, 0x8c8b, 0x476a, 0xe559, 0xe439, 0x4412, 0xc512, 0x260b, 0x260b, 0x2613, 0x0613, 0xe512, 0xc502, 0xa402, 0x6302, 0x2312, 0xe321, 0xa431, 0x8441, 0x8551, 0xa659, 0xe761, 0x296a, 0x8a7a, 0xcb82, 0x2c8b, 0x4c93, 0x8d93, 0xad93, 0xee9b, 0xefa3, 0xef9b, 0x0fa4, 0x2fa4, 0x2fa4, 0x2fa4, 0x2f9c, 0x109c, 0x0f94, 0x2f94, 0xee9b, 0x6d8b, 0x2c7b, 0xea62, 0x2632, 0x270a, 0x490a, 0x690a, 0x690a, 0x690a, 0x690a, 0x690a, 0x690a, 0x870a, 0x880a, 0x6b02, 0x6b02, 0x8902, 0xa802, 0x8702, 0x690a, 0xea0a, 0x491b, 0x061b, 0x4543, 0x2a7d, 0x2a7d, 0xa73b, 0xa702, 0xca0a, 0xa90a, 0xc80a, 0xc80a, 0xaa0a, 0xac0a, 0x8b12, 0x871a, 0x2954, 0x4b75, 0x2b65, 0xc733, 0xe702, 0xab0a,
		0xf2bc, 0xf2bc, 0xf2bc, 0xf2bc, 0xf2bc, 0xf2bc, 0xf2b4, 0xf2bc, 0xf2bc, 0xd2b4, 0xb1ac, 0x90ac, 0x70ac, 0x2fa4, 0xad9b, 0x8872, 0xe561, 0xc449, 0xc429, 0x2412, 0x840a, 0x840a, 0x430a, 0xe309, 0xe311, 0xc321, 0xc331, 0xc331, 0xe439, 0x054a, 0x265a, 0x686a, 0x8972, 0xca82, 0x0b8b, 0x6c93, 0x6c93, 0x6c93, 0xad93, 0xce93, 0xee8b, 0x0e94, 0xeea3, 0xefa3, 0x0fa4, 0x0fa4, 0x2fa4, 0x0fa4, 0x0fa4, 0xef9b, 0xf093, 0x0f94, 0x0c94, 0xab93, 0x2c83, 0xec72, 0x6942, 0x2612, 0x680a, 0x690a, 0x690a, 0x690a, 0x690a, 0x690a, 0x690a, 0x890a, 0x870a, 0x880a, 0x8b02, 0x8c02, 0xaa02, 0xa802, 0x880a, 0x8a0a, 0x8902, 0x0613, 0x6754, 0x697d, 0x287d, 0x4443, 0x860a, 0xca02, 0xcb02, 0xaa0a, 0xa90a, 0xc80a, 0xca02, 0xac0a, 0xad12, 0x8b12, 0x890a, 0x080b, 0x070b, 0xc70a, 0xc912, 0xab0a,
		0x13bd, 0xf2bc, 0xf2bc, 0xf2b4, 0xf2bc, 0xf2bc, 0xf2b4, 0xd2b4, 0xd1b4, 0xb1ac, 0x91ac, 0x90ac, 0x70ac, 0x2fac, 0xeea3, 0xca82, 0xe669, 0xa559, 0x8449, 0xc431, 0xe321, 0xc319, 0xa329, 0xc439, 0xe541, 0x065a, 0xe669, 0x276a, 0x8872, 0xe97a, 0x2a7b, 0x6b83, 0x8b83, 0xac8b, 0xab8b, 0xac93, 0xac93, 0xac8b, 0xcd8b, 0xed8b, 0x0e8c, 0x0e8c, 0xeea3, 0xeea3, 0xcea3, 0xce9b, 0xee9b, 0x0f9c, 0xee9b, 0xee9b, 0xcf9b, 0xcc9b, 0xca93, 0x6983, 0x0a73, 0x6a4a, 0x091a, 0x8902, 0x890a, 0x690a, 0x690a, 0x690a, 0x690a, 0x690a, 0x690a, 0x8902, 0x8902, 0x8902, 0x8902, 0x8a02, 0x8a02, 0x8a02, 0xa90a, 0x870a, 0xa51a, 0xe653, 0x8a7d, 0x8975, 0xa433, 0xa60a, 0x890a, 0x8a0a, 0x8a0a, 0xab0a, 0xaa0a, 0xc902, 0xc902, 0xca02, 0xab0a, 0xab0a, 0xaa0a, 0xca02, 0xc90a, 0xc912, 0xa912, 0x8a12,
		0xd2b4, 0xf2bc, 0x12bd, 0xf2bc, 0xf2bc, 0xf2b4, 0xd2b4, 0xd1b4, 0xd1b4, 0xd1b4, 0xd1b4, 0xb1b4, 0xb1b4, 0x90b4, 0x2fac, 0x6c93, 0x4872, 0xc669, 0xa561, 0xc551, 0xe541, 0xc541, 0x0652, 0x4762, 0x8872, 0xc97a, 0xca82, 0x0a8b, 0x4b8b, 0x6b8b, 0x8c8b, 0x8c8b, 0xac8b, 0xac93, 0xcc93, 0xcc93, 0xac9b, 0xac9b, 0xad9b, 0xad9b, 0xce9b, 0xee9b, 0xeea3, 0xeea3, 0xcd9b, 0xce9b, 0x0e9c, 0xee9b, 0xcd93, 0xad93, 0x8c9b, 0x6a8b, 0x8983, 0x6873, 0xc752, 0x0622, 0x4902, 0x8b02, 0x6a02, 0x690a, 0x690a, 0x690a, 0x690a, 0x6902, 0x6902, 0x6902, 0x6a02, 0x8a0a, 0xa802, 0xa802, 0x8902, 0x6a0a, 0x680a, 0xc50a, 0x475c, 0x8a85, 0xc864, 0x8523, 0x891b, 0x2b0b, 0x8902, 0x8912, 0x8912, 0xab0a, 0xaa0a, 0xc90a, 0xc902, 0xc902, 0xc90a, 0xc90a, 0xc90a, 0xca0a, 0xca12, 0xa912, 0xa91a, 0xaa1a,
		0xf2bc, 0x12bd, 0x12bd, 0xf2bc, 0xf2bc, 0xf2b4, 0xd1b4, 0xd1b4, 0xd1b4, 0xb1ac, 0xb0ac, 0x90ac, 0x90ac, 0x70ac, 0x2fa4, 0xce9b, 0x2b83, 0x697a, 0x4872, 0x476a, 0x686a, 0x486a, 0x897a, 0xca82, 0x0b83, 0x4b83, 0x6b83, 0x8c8b, 0x8c8b, 0x8c93, 0x8c93, 0x8c9b, 0x8c9b, 0x8c9b, 0x8c9b, 0x8c9b, 0x6ca3, 0x6da3, 0x8dab, 0x8dab, 0xaeab, 0xaea3, 0xce9b, 0xee9b, 0xcd93, 0xcd9b, 0xcd93, 0xcd93, 0xad93, 0x8c8b, 0x6a8b, 0x4a7b, 0x0963, 0xea6b, 0x496c, 0xc32a, 0x4602, 0x8b02, 0x6a02, 0x690a, 0x6a0a, 0x8a0a, 0x8a0a, 0x8a02, 0x8a02, 0x8a02, 0x8a0a, 0x8a0a, 0x880a, 0xa80a, 0x880a, 0x880a, 0xe61a, 0xa954, 0xab7d, 0x675c, 0xc51a, 0xa802, 0xea0a, 0x4c13, 0x2b1b, 0xa912, 0xa912, 0xaa02, 0xab02, 0xab0a, 0xaa0a, 0xc90a, 0xc80a, 0xc90a, 0xa90a, 0xaa12, 0xaa12, 0xaa12, 0xca12, 0xca12,
		0xd2bc, 0xf2bc, 0xf2bc, 0xd2b4, 0xf2b4, 0xb1b4, 0xb1ac, 0x91ac, 0x90ac, 0x90ac, 0x90ac, 0x90ac, 0x90ac, 0x70a4, 0x4f9c, 0x0e9c, 0xcd93, 0x6c8b, 0x2b8b, 0x2b83, 0x0b83, 0xca8a, 0xca8a, 0x0b8b, 0x4b83, 0x6c83, 0x6c8b, 0x6c93, 0x8c93, 0x8c93, 0x6b93, 0x6b9b, 0x6b9b, 0x6b9b, 0x6c9b, 0x6c9b, 0x6c9b, 0x6d9b, 0x8d9b, 0xad9b, 0xed9b, 0xee93, 0xcd9b, 0xcd93, 0xac8b, 0xac8b, 0x8c8b, 0x8c8b, 0x6b83, 0x4b7b, 0x096b, 0xca52, 0x292a, 0x283b, 0x096d, 0xa55c, 0xc322, 0x0902, 0x4a0a, 0x6a0a, 0x8a0a, 0x8a0a, 0x8a0a, 0x8a02, 0x8a02, 0x8a02, 0x890a, 0x890a, 0x6b0a, 0x8a0a, 0x870a, 0xe51a, 0xe95c, 0xcb7d, 0x664c, 0xe402, 0x880a, 0x6b12, 0x8b12, 0x091b, 0x6a23, 0xea0a, 0xca02, 0xc902, 0xaa02, 0xab0a, 0xab0a, 0xaa0a, 0xaa0a, 0xaa0a, 0xaa12, 0xaa12, 0xaa12, 0xcb0a, 0xcb02, 0xea02,
		0xf2bc, 0xd2b4, 0xd2b4, 0xb1b4, 0xb1ac, 0x90ac, 0x70ac, 0x70ac, 0x70ac, 0x6fa4, 0x6fac, 0x70ac, 0x70ac, 0x6fa4, 0x2fa4, 0x0e9c, 0xcd93, 0xad93, 0x8c93, 0x6c8b, 0x4b8b, 0xea82, 0xea8a, 0x2b8b, 0x4b83, 0x6c8b, 0x4c93, 0x6c93, 0x6c93, 0x8c93, 0x8b93, 0x8b93, 0x8b93, 0x8b93, 0x6c93, 0x6c93, 0x6c93, 0x6c93, 0x6c8b, 0xac8b, 0xed8b, 0xed93, 0xad93, 0x8c93, 0x6c8b, 0x4c83, 0x4c7b, 0x4b73, 0x0a63, 0xc952, 0x883a, 0x2822, 0x0912, 0x280a, 0xc63b, 0xa875, 0x665c, 0x661a, 0x6812, 0x6a0a, 0x6a0a, 0xa90a, 0xa802, 0x8902, 0x8a02, 0x8a02, 0x8a02, 0x8b0a, 0x6a12, 0x8812, 0x0423, 0x4965, 0xcb75, 0x2744, 0xc502, 0xc702, 0xaa0a, 0x8b0a, 0x8a12, 0xa912, 0xe912, 0xea0a, 0xcb02, 0xc902, 0xaa0a, 0xab0a, 0xab0a, 0xaa0a, 0xaa0a, 0xaa0a, 0xaa0a, 0xca12, 0xcb0a, 0xcb0a, 0xcb02, 0xca02
};
const uint8_t logo_w = 96;	// Largura do logo (quadrado)

/* USER CODE END PV */

void SystemClock_Config(void);

int main(void)
{

  /* MCU Configuration--------------------------------------------------------*/

  /* Reset of all peripherals, Initializes the Flash interface and the Systick. */
  HAL_Init();

  /* Configure the system clock */
  SystemClock_Config();

  /* Initialize all configured peripherals */
  MX_GPIO_Init();
  MX_SPI1_Init();
  /* USER CODE BEGIN 2 */

  ST7789_Init();	// Inicializa o display (fundo preto)

  /* USER CODE END 2 */

  ST7789_Fill_Color(WHITE);	// Preenche display com fundo branco

  // Desenha logo no centro da tela (240x240):
  ST7789_DrawImage((240-logo_w)/2, (240-logo_w)/2, logo_w, logo_w, logo_franzininho);

  /* Infinite loop */
  while (1)
  {

  }
}

void SystemClock_Config(void)
{
  RCC_OscInitTypeDef RCC_OscInitStruct = {0};
  RCC_ClkInitTypeDef RCC_ClkInitStruct = {0};

  /** Initializes the RCC Oscillators according to the specified parameters
  * in the RCC_OscInitTypeDef structure.
  */
  RCC_OscInitStruct.OscillatorType = RCC_OSCILLATORTYPE_HSI;
  RCC_OscInitStruct.HSIState = RCC_HSI_ON;
  RCC_OscInitStruct.HSIDiv = RCC_HSI_DIV1;
  RCC_OscInitStruct.HSICalibrationValue = RCC_HSICALIBRATION_DEFAULT;
  if (HAL_RCC_OscConfig(&RCC_OscInitStruct) != HAL_OK)
  {
    Error_Handler();
  }

  /** Initializes the CPU, AHB and APB buses clocks
  */
  RCC_ClkInitStruct.ClockType = RCC_CLOCKTYPE_HCLK|RCC_CLOCKTYPE_SYSCLK
                              |RCC_CLOCKTYPE_PCLK1;
  RCC_ClkInitStruct.SYSCLKSource = RCC_SYSCLKSOURCE_HSI;
  RCC_ClkInitStruct.SYSCLKDivider = RCC_SYSCLK_DIV1;
  RCC_ClkInitStruct.AHBCLKDivider = RCC_HCLK_DIV1;
  RCC_ClkInitStruct.APB1CLKDivider = RCC_APB1_DIV1;

  if (HAL_RCC_ClockConfig(&RCC_ClkInitStruct, FLASH_LATENCY_1) != HAL_OK)
  {
    Error_Handler();
  }
}

void Error_Handler(void)
{
  __disable_irq();
  while (1)
  {
  }
}
